VERSION ""

NS_ :

BS_:

BU_: Server VCU Body Brakes
VAL_TABLE_ VCI_SevereWarn 2 "All Clear" 1 "Warning Active" 0 "Offline" ;

BO_ 3221225472 VECTOR__INDEPENDENT_SIG_MSG: 0 Vector__XXX
 SG_ WP_Spd : 0|16@1- (0.01,0) [0|0] "kph" Vector__XXX
 SG_ AuxBattErr : 0|8@1+ (1,0) [0|0] "" Vector__XXX
 SG_ AuxBattCurr : 0|16@1- (0.1,0) [-3276.8|3276.7] "A" Vector__XXX
 SG_ AuxBattVolt : 0|16@1- (0.01,0) [-327.68|327.67] "V" Vector__XXX
 SG_ SOH : 0|8@1+ (1,0) [0|0] "%" Vector__XXX
 SG_ SOC : 0|8@1+ (1,0) [0|0] "%" Vector__XXX
 SG_ TiRemn : 0|8@1+ (1,0) [0|0] "hr" Vector__XXX
 SG_ patch_type : 0|8@1+ (0.1,0) [0|25.5] "" Vector__XXX
 SG_ ActEngBrkPerc : 0|8@1+ (1,-125) [-125|125] "%" Vector__XXX
 SG_ Pressure_P4 : 0|8@1+ (80,0) [0|255] "mbar" Vector__XXX
 SG_ Pressure_P1 : 0|8@1+ (80,0) [0|255] "mbar" Vector__XXX
 SG_ Pressure_P21 : 0|8@1+ (80,0) [0|255] "mbar" Vector__XXX
 SG_ Pressure_P22 : 0|8@1+ (80,0) [0|255] "mbar" Vector__XXX
 SG_ Pressure_P42 : 0|8@1+ (80,0) [0|255] "mbar" Vector__XXX
 SG_ EBS_button : 0|2@1+ (1,0) [0|3] "" Vector__XXX
 SG_ EBS_status : 0|2@1+ (1,0) [0|3] "" Vector__XXX
 SG_ XPR_ErrState : 0|2@1+ (1,0) [0|3] "" Vector__XXX
 SG_ ATC_EC_Act : 0|2@1+ (1,0) [0|3] "" Vector__XXX
 SG_ ATC_BC_Act : 0|2@1+ (1,0) [0|3] "" Vector__XXX
 SG_ ABS_Active : 0|2@1+ (1,0) [0|3] "" Vector__XXX
 SG_ ABS_OffRoad_Switch : 0|2@1+ (1,0) [0|3] "" Vector__XXX
 SG_ ABS_Fully_Op : 0|2@1+ (1,0) [0|3] "" Vector__XXX
 SG_ ABS_Amber_WL : 0|2@1+ (1,0) [0|3] "" Vector__XXX
 SG_ ATC_Info_Lamp : 0|2@1+ (1,0) [0|3] "" Vector__XXX
 SG_ IdentityNum : 0|21@1+ (1,0) [0|2097151] "" Vector__XXX
 SG_ Manufacturer : 0|11@1+ (1,0) [0|2047] "" Vector__XXX
 SG_ EcuInstance : 0|3@1+ (1,0) [0|7] "" Vector__XXX
 SG_ FctInstance : 0|5@1+ (1,0) [0|31] "" Vector__XXX
 SG_ Reserved : 0|1@1+ (1,0) [0|1] "" Vector__XXX
 SG_ VehSystem : 0|7@1+ (1,0) [0|127] "" Vector__XXX
 SG_ VehSysInstance : 0|4@1+ (1,0) [0|15] "" Vector__XXX
 SG_ ArbAddrCapable : 0|1@1+ (1,0) [0|1] "" Vector__XXX
 SG_ ACHeatOption : 0|2@1- (1,0) [0|0] "" Vector__XXX
 SG_ ACControlMode : 0|2@1- (1,0) [0|0] "" Vector__XXX
 SG_ PreCruiseCtrlDeactivRq : 0|2@1+ (1,0) [0|3] "" Vector__XXX
 SG_ CabInteriorTempCmd : 0|16@1+ (0.03125,-273) [-273|1734.96875] "deg C" Vector__XXX
 SG_ AuxHeaterCoolantPumpRq : 0|2@1+ (1,0) [0|3] "" Vector__XXX
 SG_ BatteryMainSwitchHoldRq : 0|2@1+ (1,0) [0|3] "" Vector__XXX
 SG_ OperatorSeatDirectionSwitch : 0|2@1+ (1,0) [0|3] "" Vector__XXX
 SG_ SeatBeltSwitch : 0|2@1+ (1,0) [0|3] "" Vector__XXX
 SG_ VhclLmtngSpdGvrnrDecrementSwitch : 0|2@1+ (1,0) [0|3] "" Vector__XXX
 SG_ VhclLmtngSpdGvrnrIncrementSwitch : 0|2@1+ (1,0) [0|3] "" Vector__XXX
 SG_ VhclLmtngSpdGovernorEnableSwitch : 0|2@1+ (1,0) [0|3] "" Vector__XXX
 SG_ DslPrtcltFltrRgnrtnInhibitSwitch : 0|2@1+ (1,0) [0|3] "" Vector__XXX
 SG_ DslPrtcltFltrRgnrtionForceSwitch : 0|2@1+ (1,0) [0|3] "" Vector__XXX
 SG_ AtomaticGearShiftingEnableSwitch : 0|2@1+ (1,0) [0|3] "" Vector__XXX
 SG_ EngAutomaticStartEnableSwitch : 0|2@1+ (1,0) [0|3] "" Vector__XXX
 SG_ AuxHeaterModeRq : 0|4@1+ (1,0) [0|15] "" Vector__XXX
 SG_ RqEngZoneHeating : 0|2@1+ (1,0) [0|3] "" Vector__XXX
 SG_ RqCabZoneHeating : 0|2@1+ (1,0) [0|3] "" Vector__XXX
 SG_ SelectedMaxVehicleSpeedLimit : 0|8@1+ (1,0) [0|250] "" Vector__XXX
 SG_ EnginePercentLoadAtCurrentSpeed : 0|8@1+ (1,0) [0|255] "%" Vector__XXX
 SG_ AcceleratorPedalPosition2 : 0|8@1+ (0.4,0) [0|102] "%" Vector__XXX
 SG_ AcceleratorPedalPosition1 : 0|8@1+ (0.4,0) [0|102] "%" Vector__XXX
 SG_ xbr_demand : 0|8@1+ (0.025,0) [0|6.375] "" Vector__XXX
 SG_ CTIWheelEndElectricalFault_00 : 0|2@1+ (1,0) [0|3] "" Vector__XXX
 SG_ CTIWheelSensorStatus_00 : 0|2@1+ (1,0) [0|3] "" Vector__XXX
 SG_ TirePress_00 : 0|8@1+ (4,0) [0|1000] "kPa" Vector__XXX
 SG_ TirePress_01 : 0|8@1+ (4,0) [0|1000] "kPa" Vector__XXX
 SG_ TirePressThresholdDetection_00 : 0|3@1+ (1,0) [0|7] "" Vector__XXX
 SG_ TirePressThresholdDetection_20 : 0|3@1+ (1,0) [0|7] "" Vector__XXX
 SG_ TirePressThresholdDetection_21 : 0|3@1+ (1,0) [0|7] "" Vector__XXX
 SG_ TirePressThresholdDetection_22 : 0|3@1+ (1,0) [0|7] "" Vector__XXX
 SG_ TirePressThresholdDetection_23 : 0|3@1+ (1,0) [0|7] "" Vector__XXX
 SG_ TirePressThresholdDetection_30 : 0|3@1+ (1,0) [0|7] "" Vector__XXX
 SG_ TirePressThresholdDetection_31 : 0|3@1+ (1,0) [0|7] "" Vector__XXX
 SG_ TirePressThresholdDetection_32 : 0|3@1+ (1,0) [0|7] "" Vector__XXX
 SG_ TirePressThresholdDetection_33 : 0|3@1+ (1,0) [0|7] "" Vector__XXX
 SG_ TireTemp_01 : 0|16@1+ (0.03125,-273) [-273|1735] "°C" Vector__XXX
 SG_ TireTemp_10 : 0|16@1+ (0.03125,-273) [-273|1735] "°C" Vector__XXX
 SG_ TireTemp_12 : 0|16@1+ (0.03125,-273) [-273|1735] "°C" Vector__XXX
 SG_ TireTemp_13 : 0|16@1+ (0.03125,-273) [-273|1735] "°C" Vector__XXX
 SG_ TireTemp_20 : 0|16@1+ (0.03125,-273) [-273|1735] "°C" Vector__XXX
 SG_ TireTemp_21 : 0|16@1+ (0.03125,-273) [-273|1735] "°C" Vector__XXX
 SG_ TireTemp_22 : 0|16@1+ (0.03125,-273) [-273|1735] "°C" Vector__XXX
 SG_ TireTemp_23 : 0|16@1+ (0.03125,-273) [-273|1735] "°C" Vector__XXX
 SG_ TireTemp_30 : 0|16@1+ (0.03125,-273) [-273|1735] "°C" Vector__XXX
 SG_ TireTemp_31 : 0|16@1+ (0.03125,-273) [-273|1735] "°C" Vector__XXX
 SG_ TireTemp_32 : 0|16@1+ (0.03125,-273) [-273|1735] "°C" Vector__XXX
 SG_ TireTemp_33 : 0|16@1+ (0.03125,-273) [-273|1735] "°C" Vector__XXX
 SG_ TireTemp_11 : 0|16@1+ (0.03125,-273) [-273|1735] "°C" Vector__XXX
 SG_ CTITireStatus_01 : 0|2@1+ (1,0) [0|3] "" Vector__XXX
 SG_ CTITireStatus_10 : 0|2@1+ (1,0) [0|3] "" Vector__XXX
 SG_ CTITireStatus_11 : 0|2@1+ (1,0) [0|3] "" Vector__XXX
 SG_ CTITireStatus_12 : 0|2@1+ (1,0) [0|3] "" Vector__XXX
 SG_ CTITireStatus_13 : 0|2@1+ (1,0) [0|3] "" Vector__XXX
 SG_ CTITireStatus_20 : 0|2@1+ (1,0) [0|3] "" Vector__XXX
 SG_ CTITireStatus_21 : 0|2@1+ (1,0) [0|3] "" Vector__XXX
 SG_ CTITireStatus_22 : 0|2@1+ (1,0) [0|3] "" Vector__XXX
 SG_ CTITireStatus_23 : 0|2@1+ (1,0) [0|3] "" Vector__XXX
 SG_ CTITireStatus_30 : 0|2@1+ (1,0) [0|3] "" Vector__XXX
 SG_ CTITireStatus_31 : 0|2@1+ (1,0) [0|3] "" Vector__XXX
 SG_ CTITireStatus_32 : 0|2@1+ (1,0) [0|3] "" Vector__XXX
 SG_ CTITireStatus_33 : 0|2@1+ (1,0) [0|3] "" Vector__XXX
 SG_ CTIWheelEndElectricalFault_01 : 0|2@1+ (1,0) [0|3] "" Vector__XXX
 SG_ CTIWheelEndElectricalFault_10 : 0|2@1+ (1,0) [0|3] "" Vector__XXX
 SG_ CTIWheelEndElectricalFault_11 : 0|2@1+ (1,0) [0|3] "" Vector__XXX
 SG_ CTIWheelEndElectricalFault_12 : 0|2@1+ (1,0) [0|3] "" Vector__XXX
 SG_ CTIWheelEndElectricalFault_13 : 0|2@1+ (1,0) [0|3] "" Vector__XXX
 SG_ CTIWheelEndElectricalFault_20 : 0|2@1+ (1,0) [0|3] "" Vector__XXX
 SG_ CTIWheelEndElectricalFault_21 : 0|2@1+ (1,0) [0|3] "" Vector__XXX
 SG_ CTIWheelEndElectricalFault_22 : 0|2@1+ (1,0) [0|3] "" Vector__XXX
 SG_ CTIWheelEndElectricalFault_23 : 0|2@1+ (1,0) [0|3] "" Vector__XXX
 SG_ CTIWheelEndElectricalFault_30 : 0|2@1+ (1,0) [0|3] "" Vector__XXX
 SG_ CTIWheelEndElectricalFault_31 : 0|2@1+ (1,0) [0|3] "" Vector__XXX
 SG_ CTIWheelEndElectricalFault_32 : 0|2@1+ (1,0) [0|3] "" Vector__XXX
 SG_ CTIWheelSensorStatus_01 : 0|2@1+ (1,0) [0|3] "" Vector__XXX
 SG_ CTIWheelSensorStatus_10 : 0|2@1+ (1,0) [0|3] "" Vector__XXX
 SG_ CTIWheelSensorStatus_11 : 0|2@1+ (1,0) [0|3] "" Vector__XXX
 SG_ CTIWheelSensorStatus_12 : 0|2@1+ (1,0) [0|3] "" Vector__XXX
 SG_ CTIWheelSensorStatus_13 : 0|2@1+ (1,0) [0|3] "" Vector__XXX
 SG_ CTIWheelSensorStatus_20 : 0|2@1+ (1,0) [0|3] "" Vector__XXX
 SG_ CTIWheelSensorStatus_21 : 0|2@1+ (1,0) [0|3] "" Vector__XXX
 SG_ CTIWheelSensorStatus_22 : 0|2@1+ (1,0) [0|3] "" Vector__XXX
 SG_ CTIWheelSensorStatus_23 : 0|2@1+ (1,0) [0|3] "" Vector__XXX
 SG_ CTIWheelSensorStatus_30 : 0|2@1+ (1,0) [0|3] "" Vector__XXX
 SG_ CTIWheelSensorStatus_31 : 0|2@1+ (1,0) [0|3] "" Vector__XXX
 SG_ CTIWheelSensorStatus_32 : 0|2@1+ (1,0) [0|3] "" Vector__XXX
 SG_ TireAirLeakageRate_00 : 0|16@1+ (0.1,0) [0|6425.5] "Pa/s" Vector__XXX
 SG_ TireAirLeakageRate_01 : 0|16@1+ (0.1,0) [0|6425.5] "Pa/s" Vector__XXX
 SG_ TireAirLeakageRate_10 : 0|16@1+ (0.1,0) [0|6425.5] "Pa/s" Vector__XXX
 SG_ TireAirLeakageRate_11 : 0|16@1+ (0.1,0) [0|6425.5] "Pa/s" Vector__XXX
 SG_ TireAirLeakageRate_12 : 0|16@1+ (0.1,0) [0|6425.5] "Pa/s" Vector__XXX
 SG_ TireAirLeakageRate_13 : 0|16@1+ (0.1,0) [0|6425.5] "Pa/s" Vector__XXX
 SG_ TireAirLeakageRate_20 : 0|16@1+ (0.1,0) [0|6425.5] "Pa/s" Vector__XXX
 SG_ TireAirLeakageRate_21 : 0|16@1+ (0.1,0) [0|6425.5] "Pa/s" Vector__XXX
 SG_ TireAirLeakageRate_22 : 0|16@1+ (0.1,0) [0|6425.5] "Pa/s" Vector__XXX
 SG_ TireAirLeakageRate_23 : 0|16@1+ (0.1,0) [0|6425.5] "Pa/s" Vector__XXX
 SG_ TireAirLeakageRate_30 : 0|16@1+ (0.1,0) [0|6425.5] "Pa/s" Vector__XXX
 SG_ TireAirLeakageRate_31 : 0|16@1+ (0.1,0) [0|6425.5] "Pa/s" Vector__XXX
 SG_ TireAirLeakageRate_32 : 0|16@1+ (0.1,0) [0|6425.5] "Pa/s" Vector__XXX
 SG_ TirePress_10 : 0|8@1+ (4,0) [0|1000] "kPa" Vector__XXX
 SG_ TirePress_11 : 0|8@1+ (4,0) [0|1000] "kPa" Vector__XXX
 SG_ TirePress_12 : 0|8@1+ (4,0) [0|1000] "kPa" Vector__XXX
 SG_ TirePress_13 : 0|8@1+ (4,0) [0|1000] "kPa" Vector__XXX
 SG_ TirePress_20 : 0|8@1+ (4,0) [0|1000] "kPa" Vector__XXX
 SG_ TirePress_21 : 0|8@1+ (4,0) [0|1000] "kPa" Vector__XXX
 SG_ TirePress_22 : 0|8@1+ (4,0) [0|1000] "kPa" Vector__XXX
 SG_ TirePress_23 : 0|8@1+ (4,0) [0|1000] "kPa" Vector__XXX
 SG_ TirePress_30 : 0|8@1+ (4,0) [0|1000] "kPa" Vector__XXX
 SG_ TirePress_31 : 0|8@1+ (4,0) [0|1000] "kPa" Vector__XXX
 SG_ TirePress_32 : 0|8@1+ (4,0) [0|1000] "kPa" Vector__XXX
 SG_ TirePressThresholdDetection_01 : 0|3@1+ (1,0) [0|7] "" Vector__XXX
 SG_ TirePressThresholdDetection_10 : 0|3@1+ (1,0) [0|7] "" Vector__XXX
 SG_ TirePressThresholdDetection_11 : 0|3@1+ (1,0) [0|7] "" Vector__XXX
 SG_ TirePressThresholdDetection_12 : 0|3@1+ (1,0) [0|7] "" Vector__XXX
 SG_ AxleWeight_00 : 0|16@1+ (0.5,0) [0|32127.5] "kg" Vector__XXX
 SG_ AxleWeight_10 : 0|16@1+ (0.5,0) [0|32127.5] "kg" Vector__XXX
 SG_ AxleWeight_20 : 0|16@1+ (0.5,0) [0|32127.5] "kg" Vector__XXX
 SG_ TrailerWeight_00 : 0|16@1+ (2,0) [0|128510] "kg" Vector__XXX
 SG_ TrailerWeight_10 : 0|16@1+ (2,0) [0|128510] "kg" Vector__XXX
 SG_ TrailerWeight_20 : 0|16@1+ (2,0) [0|128510] "kg" Vector__XXX
 SG_ CargoWeight_00 : 0|16@1+ (2,0) [0|128510] "kg" Vector__XXX
 SG_ CargoWeight_10 : 0|16@1+ (2,0) [0|128510] "kg" Vector__XXX
 SG_ CargoWeight_20 : 0|16@1+ (2,0) [0|128510] "kg" Vector__XXX
 SG_ BrkPos_Ord : 0|1@1+ (1,0) [0|1] "" Vector__XXX
 SG_ Counter : 0|4@1+ (1,0) [0|15] "" Vector__XXX
 SG_ EBI_Mode : 0|1@1- (1,0) [0|1] "" Vector__XXX
 SG_ BrakeDemand : 0|16@1- (0.000488,-15.687) [-31.6778|0.303295] "m/s2" Vector__XXX
 SG_ Counter : 0|4@1+ (1,0) [0|15] "" Vector__XXX
 SG_ EBI_Mode : 0|1@1- (1,0) [0|1] "" Vector__XXX
 SG_ BrakeDemand : 0|16@1- (0.000488,-15.687) [-31.6778|0.303295] "m/s2" Vector__XXX

BO_ 2147516743 VehFSLogRpt1: 8 Vector__XXX
 SG_ FSBMod : 8|2@1+ (1,0) [0|3] "" Vector__XXX
 SG_ FSBA : 0|8@1+ (0.1,-12.5) [-12.5|13] "" Vector__XXX

BO_ 2147488545 VCU_Test3MSG: 8 Vector__XXX
 SG_ ACCTarSpd : 8|8@1+ (1,0) [0|255] "km/h" Vector__XXX
 SG_ FSBEna : 0|2@1+ (1,0) [0|3] "" Vector__XXX

BO_ 2466192724 MURR_PWM2: 8 Vector__XXX
 SG_ PWMCtrlOut4B : 48|12@1+ (1,0) [0|0] "" Vector__XXX
 SG_ PWMCtrlOut4A : 32|12@1+ (1,0) [0|0] "" Vector__XXX
 SG_ PWMCtrlOut3B : 16|12@1+ (1,0) [0|0] "" Vector__XXX
 SG_ PWMCtrlOut3A : 0|16@1+ (1,0) [0|0] "" Vector__XXX

BO_ 2466192468 MURR_PWM1: 8 Vector__XXX
 SG_ PWMCtrlOut2B : 48|12@1+ (1,0) [0|0] "" Vector__XXX
 SG_ PWMCtrlOut2A : 32|12@1+ (1,0) [0|0] "" Vector__XXX
 SG_ PWMCtrlOut1B : 16|12@1+ (1,0) [0|0] "" Vector__XXX
 SG_ PWMCtrlOut1A : 0|16@1+ (1,0) [0|0] "" Vector__XXX

BO_ 2466192980 MURR_PWM3: 8 Vector__XXX
 SG_ PWMCtrlOut6B : 48|12@1+ (1,0) [0|0] "" Vector__XXX
 SG_ PWMCtrlOut6A : 32|12@1+ (1,0) [0|0] "" Vector__XXX
 SG_ PWMCtrlOut5B : 16|12@1+ (1,0) [0|0] "" Vector__XXX
 SG_ PWMCtrlOut5A : 0|12@1+ (1,0) [0|0] "" Vector__XXX

BO_ 2466193236 MURR_PWM4: 8 Vector__XXX
 SG_ PWMCtrlOut8B : 48|12@1+ (1,0) [0|0] "" Vector__XXX
 SG_ PWMCtrlOut8A : 32|12@1+ (1,0) [0|0] "" Vector__XXX
 SG_ PWMCtrlOut7B : 16|12@1+ (1,0) [0|0] "" Vector__XXX
 SG_ PWMCtrlOut7A : 0|12@1+ (1,0) [0|0] "" Vector__XXX

BO_ 2147484440 PwrRpt: 8 Vector__XXX
 SG_ PwrSevereWarn : 16|8@1+ (1,0) [0|0] "mV" Vector__XXX
 SG_ AuxV : 0|16@1+ (0.5,0) [0|32767.5] "mV" Vector__XXX

BO_ 2147484438 SwtTRpt: 8 Vector__XXX
 SG_ TSevereWarn : 16|8@1+ (1,0) [0|0] "deg C" Vector__XXX
 SG_ SwtT : 0|16@1+ (0.11,-28.919) [-28.919|7179.931] "deg C" Vector__XXX

BO_ 2566911200 StatusMsg5: 8 Vector__XXX
 SG_ OUT8B_AMP_FB : 56|8@1+ (1,0) [0|4000] "A" Vector__XXX
 SG_ OUT8A_AMP_FB : 48|8@1+ (1,0) [0|4000] "A" Vector__XXX
 SG_ OUT7B_AMP_FB : 40|8@1+ (1,0) [0|4000] "A" Vector__XXX
 SG_ OUT7A_AMP_FB : 32|8@1+ (1,0) [0|4000] "A" Vector__XXX
 SG_ OUT6B_AMP_FB : 24|8@1+ (1,0) [0|4000] "A" Vector__XXX
 SG_ OUT6A_AMP_FB : 16|8@1+ (1,0) [0|4000] "A" Vector__XXX
 SG_ OUT5B_AMP_FB : 8|8@1+ (1,0) [0|4000] "A" Vector__XXX
 SG_ OUT5A_AMP_FB : 0|8@1+ (1,0) [0|4000] "A" Vector__XXX

BO_ 2566910944 StatusMsg4: 8 Vector__XXX
 SG_ OUT4B_AMP_FB : 56|8@1+ (1,0) [0|0] "mA" Vector__XXX
 SG_ OUT4A_AMP_FB : 48|8@1+ (1,0) [0|0] "mA" Vector__XXX
 SG_ OUT3B_AMP_FB : 40|8@1+ (1,0) [0|0] "mA" Vector__XXX
 SG_ OUT3A_AMP_FB : 32|8@1+ (1,0) [0|0] "mA" Vector__XXX
 SG_ OUT2B_AMP_FB : 24|8@1+ (1,0) [0|0] "mA" Vector__XXX
 SG_ OUT2A_AMP_FB : 16|8@1+ (1,0) [0|0] "mA" Vector__XXX
 SG_ OUT1B_AMP_FB : 8|8@1+ (1,0) [0|0] "mA" Vector__XXX
 SG_ OUT1A_AMP_FB : 0|8@1+ (1,0) [0|0] "mA" Vector__XXX

BO_ 2566912992 StatusMsg2: 8 Vector__XXX
 SG_ SaveConfigCounter : 56|8@1+ (1,0) [0|0] "" Vector__XXX
 SG_ PowerBussP3 : 52|2@1+ (1,0) [0|0] "A" Vector__XXX
 SG_ PowerBussP2 : 50|2@1+ (1,0) [0|0] "A" Vector__XXX
 SG_ PowerBussP4 : 54|2@1+ (1,0) [0|0] "A" Vector__XXX
 SG_ PowerBussP1 : 48|2@1+ (1,0) [0|0] "A" Vector__XXX
 SG_ Output8BStatus : 46|2@1+ (1,0) [0|0] "" Vector__XXX
 SG_ Output8AStatus : 44|2@1+ (1,0) [0|0] "" Vector__XXX
 SG_ Output7BStatus : 42|2@1+ (1,0) [0|0] "" Vector__XXX
 SG_ Output7AStatus : 40|2@1+ (1,0) [0|0] "" Vector__XXX
 SG_ Output6BStatus : 38|2@1+ (1,0) [0|0] "" Vector__XXX
 SG_ Output6AStatus : 36|2@1+ (1,0) [0|0] "" Vector__XXX
 SG_ Output5BStatus : 34|2@1+ (1,0) [0|0] "" Vector__XXX
 SG_ Output5AStatus : 32|2@1+ (1,0) [0|0] "" Vector__XXX
 SG_ Output4BStatus : 30|2@1+ (1,0) [0|0] "" Vector__XXX
 SG_ Output4AStatus : 28|2@1+ (1,0) [0|0] "" Vector__XXX
 SG_ Output3BStatus : 26|2@1+ (1,0) [0|0] "" Vector__XXX
 SG_ Output3AStatus : 24|2@1+ (1,0) [0|0] "" Vector__XXX
 SG_ Output2BStatus : 22|2@1+ (1,0) [0|0] "" Vector__XXX
 SG_ Output2AStatus : 20|2@1+ (1,0) [0|0] "" Vector__XXX
 SG_ Output1BStatus : 18|2@1+ (1,0) [0|0] "" Vector__XXX
 SG_ Output1AStatus : 16|2@1+ (1,0) [0|0] "" Vector__XXX
 SG_ ConfigPair5 : 8|2@1+ (1,0) [0|0] "" Vector__XXX
 SG_ ConfigPair4 : 6|2@1+ (1,0) [0|0] "" Vector__XXX
 SG_ ConfigPair3 : 4|2@1+ (1,0) [0|0] "" Vector__XXX
 SG_ ConfigPair2 : 2|2@1+ (1,0) [0|0] "" Vector__XXX
 SG_ ConfigPair1 : 0|2@1+ (1,0) [0|0] "" Vector__XXX

BO_ 2566913248 StatusMsg3: 8 Vector__XXX
 SG_ CNFG3 : 48|8@1+ (1,0) [0|0] "" Vector__XXX
 SG_ TEMP : 32|12@1+ (1,0) [0|0] "" Vector__XXX
 SG_ VBAT : 16|10@1+ (1,0) [0|0] "" Vector__XXX
 SG_ CNFG2 : 8|8@1+ (1,0) [0|0] "" Vector__XXX
 SG_ CNFG1 : 0|8@1+ (1,0) [0|0] "" Vector__XXX

BO_ 2565857361 MURR_Relay: 8 Vector__XXX
 SG_ Output8B : 38|2@1+ (1,0) [0|0] "" Vector__XXX
 SG_ Output8A : 36|2@1+ (1,0) [0|0] "" Vector__XXX
 SG_ Output7B : 34|2@1+ (1,0) [0|0] "" Vector__XXX
 SG_ Output7A : 32|2@1+ (1,0) [0|0] "" Vector__XXX
 SG_ Output6B : 30|2@1+ (1,0) [0|0] "" Vector__XXX
 SG_ Output6A : 28|2@1+ (1,0) [0|0] "" Vector__XXX
 SG_ Output5B : 26|2@1+ (1,0) [0|0] "" Vector__XXX
 SG_ Output5A : 24|2@1+ (1,0) [0|0] "" Vector__XXX
 SG_ Output4B : 22|2@1+ (1,0) [0|0] "" Vector__XXX
 SG_ Output4A : 20|2@1+ (1,0) [0|0] "" Vector__XXX
 SG_ Output3B : 18|2@1+ (1,0) [0|0] "" Vector__XXX
 SG_ Output3A : 16|2@1+ (1,0) [0|0] "" Vector__XXX
 SG_ Output2B : 14|2@1+ (1,0) [0|0] "" Vector__XXX
 SG_ Output2A : 12|2@1+ (1,0) [0|0] "" Vector__XXX
 SG_ Output1B : 10|2@1+ (1,0) [0|0] "" Vector__XXX
 SG_ Output1A : 8|2@1+ (1,0) [0|0] "" Vector__XXX
 SG_ Command : 0|8@1+ (1,0) [0|0] "" Vector__XXX

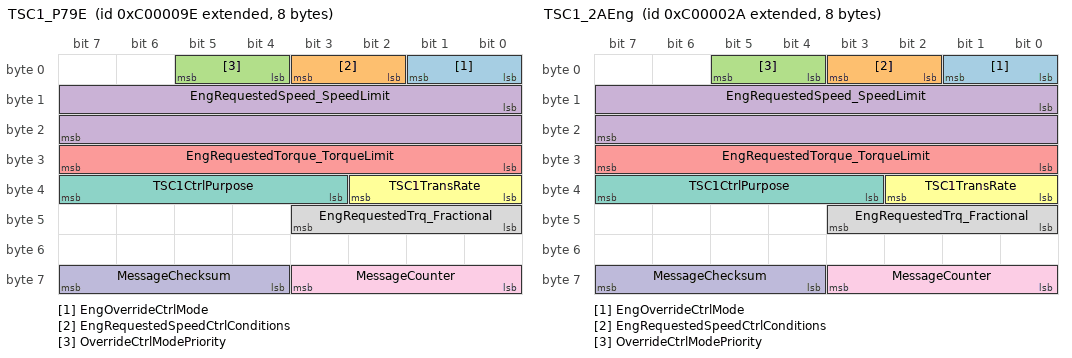
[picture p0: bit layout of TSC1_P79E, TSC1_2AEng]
BO_ 2348810398 TSC1_P79E: 8 Vector__XXX
 SG_ EngOverrideCtrlMode : 0|2@1+ (1,0) [0|3] "" Vector__XXX
 SG_ EngRequestedSpeedCtrlConditions : 2|2@1+ (1,0) [0|3] "" Vector__XXX
 SG_ OverrideCtrlModePriority : 4|2@1+ (1,0) [0|3] "" Vector__XXX
 SG_ EngRequestedSpeed_SpeedLimit : 8|16@1+ (0.125,0) [0|8031.88] "rpm" Vector__XXX
 SG_ EngRequestedTorque_TorqueLimit : 24|8@1+ (1,-125) [-125|125] "%" Vector__XXX
 SG_ TSC1TransRate : 32|3@1+ (1,0) [0|7] "" Vector__XXX
 SG_ TSC1CtrlPurpose : 35|5@1+ (1,0) [0|31] "" Vector__XXX
 SG_ EngRequestedTrq_Fractional : 40|4@1+ (0.125,0) [0|0.875] "%" Vector__XXX
 SG_ MessageCounter : 56|4@1+ (1,0) [0|15] "" Vector__XXX
 SG_ MessageChecksum : 60|4@1+ (1,0) [0|15] "" Vector__XXX

BO_ 2348810282 TSC1_2AEng: 8 Vector__XXX
 SG_ EngOverrideCtrlMode : 0|2@1+ (1,0) [0|3] "" Vector__XXX
 SG_ EngRequestedSpeedCtrlConditions : 2|2@1+ (1,0) [0|3] "" Vector__XXX
 SG_ OverrideCtrlModePriority : 4|2@1+ (1,0) [0|3] "" Vector__XXX
 SG_ EngRequestedSpeed_SpeedLimit : 8|16@1+ (0.125,0) [0|8031.88] "rpm" Vector__XXX
 SG_ EngRequestedTorque_TorqueLimit : 24|8@1+ (1,-125) [-125|125] "%" Vector__XXX
 SG_ TSC1TransRate : 32|3@1+ (1,0) [0|7] "" Vector__XXX
 SG_ TSC1CtrlPurpose : 35|5@1+ (1,0) [0|31] "" Vector__XXX
 SG_ EngRequestedTrq_Fractional : 40|4@1+ (0.125,0) [0|0.875] "%" Vector__XXX
 SG_ MessageCounter : 56|4@1+ (1,0) [0|15] "" Vector__XXX
 SG_ MessageChecksum : 60|4@1+ (1,0) [0|15] "" Vector__XXX

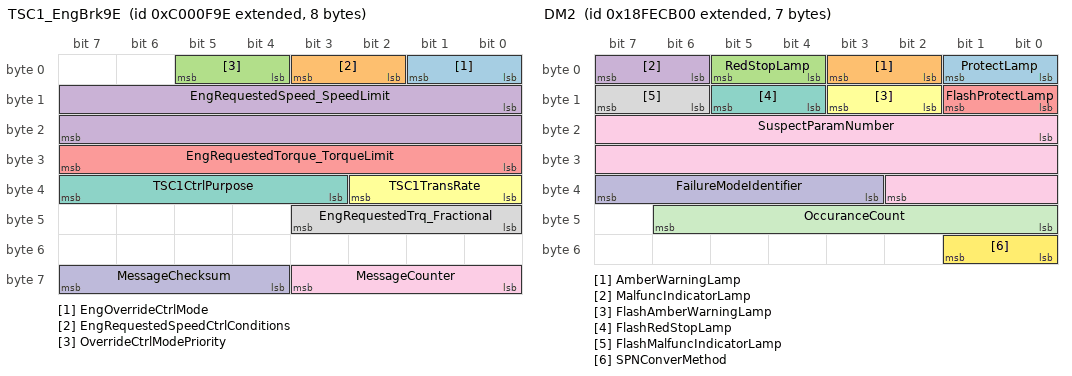
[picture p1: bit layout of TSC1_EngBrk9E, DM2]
BO_ 2348814238 TSC1_EngBrk9E: 8 Vector__XXX
 SG_ EngOverrideCtrlMode : 0|2@1+ (1,0) [0|3] "" Vector__XXX
 SG_ EngRequestedSpeedCtrlConditions : 2|2@1+ (1,0) [0|3] "" Vector__XXX
 SG_ OverrideCtrlModePriority : 4|2@1+ (1,0) [0|3] "" Vector__XXX
 SG_ EngRequestedSpeed_SpeedLimit : 8|16@1+ (0.125,0) [0|8031.88] "rpm" Vector__XXX
 SG_ EngRequestedTorque_TorqueLimit : 24|8@1+ (1,-125) [-125|125] "%" Vector__XXX
 SG_ TSC1TransRate : 32|3@1+ (1,0) [0|7] "" Vector__XXX
 SG_ TSC1CtrlPurpose : 35|5@1+ (1,0) [0|31] "" Vector__XXX
 SG_ EngRequestedTrq_Fractional : 40|4@1+ (0.125,0) [0|0.875] "%" Vector__XXX
 SG_ MessageCounter : 56|4@1+ (1,0) [0|15] "" Vector__XXX
 SG_ MessageChecksum : 60|4@1+ (1,0) [0|15] "" Vector__XXX

BO_ 2566834944 DM2: 7 Vector__XXX
 SG_ ProtectLamp : 0|2@1+ (1,0) [0|3] "" Vector__XXX
 SG_ AmberWarningLamp : 2|2@1+ (1,0) [0|3] "" Vector__XXX
 SG_ RedStopLamp : 4|2@1+ (1,0) [0|3] "" Vector__XXX
 SG_ MalfuncIndicatorLamp : 6|2@1+ (1,0) [0|3] "" Vector__XXX
 SG_ FlashProtectLamp : 8|2@1+ (1,0) [0|3] "" Vector__XXX
 SG_ FlashAmberWarningLamp : 10|2@1+ (1,0) [0|3] "" Vector__XXX
 SG_ FlashRedStopLamp : 12|2@1+ (1,0) [0|3] "" Vector__XXX
 SG_ FlashMalfuncIndicatorLamp : 14|2@1+ (1,0) [0|3] "" Vector__XXX
 SG_ SuspectParamNumber : 16|19@1+ (1,0) [0|524287] "" Vector__XXX
 SG_ FailureModeIdentifier : 35|5@1+ (1,0) [0|31] "" Vector__XXX
 SG_ OccuranceCount : 40|7@1+ (1,0) [0|127] "" Vector__XXX
 SG_ SPNConverMethod : 48|2@1+ (1,0) [0|3] "" Vector__XXX

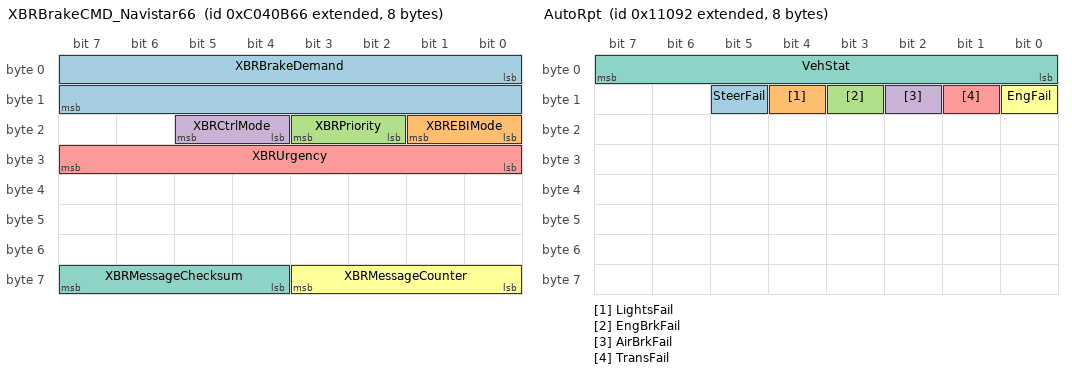
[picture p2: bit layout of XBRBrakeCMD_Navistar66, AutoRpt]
BO_ 2349075302 XBRBrakeCMD_Navistar66: 8 VCU
 SG_ XBRBrakeDemand : 0|16@1+ (0.000488,-15.69) [-15.69|-15.6749] "m/s?" Vector__XXX
 SG_ XBREBIMode : 16|2@1+ (1,0) [0|3] "" Vector__XXX
 SG_ XBRPriority : 18|2@1+ (1,0) [0|3] "" Vector__XXX
 SG_ XBRCtrlMode : 20|2@1+ (1,0) [0|3] "" Vector__XXX
 SG_ XBRUrgency : 24|8@1+ (1,0) [0|100] "%" Vector__XXX
 SG_ XBRMessageCounter : 56|4@1+ (1,0) [0|15] "" Vector__XXX
 SG_ XBRMessageChecksum : 60|4@1+ (1,0) [0|15] "" Vector__XXX

BO_ 2147680272 VersionGWRpt: 8 Vector__XXX
 SG_ GW_truck_type : 24|8@1+ (1,0) [0|0] "" Vector__XXX
 SG_ GW_patch_version : 16|8@1+ (1,0) [0|0] "" Vector__XXX
 SG_ GW_feature_version : 8|8@1+ (1,0) [0|0] "" Vector__XXX
 SG_ GW_version : 0|8@1+ (1,0) [0|0] "" Vector__XXX

BO_ 2147680257 AcsyRpt: 8 VCU
 SG_ HighBeamHeadLightRpt : 8|2@1+ (1,0) [0|0] "" Vector__XXX
 SG_ LowBeamHeadLightRpt : 6|2@1+ (1,0) [0|0] "" Vector__XXX
 SG_ HazardLightRpt : 4|2@1+ (1,0) [0|0] "" Vector__XXX
 SG_ RightTurnSignalLightsRpt : 2|2@1+ (1,0) [0|0] "" Vector__XXX
 SG_ LeftTurnSignalLightsRpt : 0|2@1+ (1,0) [0|0] "" Vector__XXX
 SG_ TurnSignalLightsDriverCmd : 10|2@1+ (1,0) [0|0] "" Vector__XXX

BO_ 2147618952 VcuTimeSync_Slave: 8 Server
 SG_ RollingCounter : 32|32@1+ (1,0) [0|0] "" Vector__XXX
 SG_ Seconds : 24|8@1+ (1,0) [0|0] "sec" Vector__XXX
 SG_ Minutes : 16|8@1+ (1,0) [0|0] "min" Vector__XXX
 SG_ Hour : 8|8@1+ (1,0) [0|0] "hr" Vector__XXX
 SG_ Day : 0|8@1+ (1,0) [0|0] "" Vector__XXX

BO_ 2147520848 TimeSync_Slave: 8 Server
 SG_ RollingCounter : 32|32@1+ (1,0) [0|0] "" Vector__XXX
 SG_ Seconds : 24|8@1+ (1,0) [0|0] "sec" Vector__XXX
 SG_ Minutes : 16|8@1+ (1,0) [0|0] "min" Vector__XXX
 SG_ Hour : 8|8@1+ (1,0) [0|0] "hr" Vector__XXX
 SG_ Day : 0|8@1+ (1,0) [0|0] "" Vector__XXX

BO_ 2147516756 OctopusStatus: 8 Server
 SG_ SystemStatus : 0|8@1+ (1,0) [0|0] "" Vector__XXX
 SG_ ControllerStatus : 14|2@1+ (1,0) [0|0] "" Vector__XXX
 SG_ PlannerStatus : 12|2@1+ (1,0) [0|0] "" Vector__XXX
 SG_ LocalizationStatus : 10|2@1+ (1,0) [0|0] "" Vector__XXX
 SG_ PerceptionStatus : 8|2@1+ (1,0) [0|0] "" Vector__XXX

BO_ 2147516754 VehInfo: 1 Server
 SG_ P7Support : 6|2@1+ (1,0) [0|0] "" Vector__XXX
 SG_ _2C2Present : 4|2@1+ (1,0) [0|3] "" Vector__XXX
 SG_ VehType : 0|4@1+ (1,0) [0|15] "" Vector__XXX

BO_ 2147553416 VcuTimeSync: 8 VCU
 SG_ SimTime : 0|32@1+ (1,0) [0|0] "" Vector__XXX

BO_ 2147484436 AcRpt: 8 VCU
 SG_ SvrT : 48|16@1+ (1,0) [0|0] "" Vector__XXX
 SG_ AcT : 32|16@1+ (1,0) [0|0] "" Vector__XXX
 SG_ CmprSpd : 24|8@1+ (1,0) [0|0] "" Vector__XXX
 SG_ AcSts : 16|4@1+ (1,0) [0|0] "" Vector__XXX
 SG_ CtrlMod : 8|2@1+ (1,0) [0|0] "" Vector__XXX
 SG_ AcFlt : 0|8@1+ (1,0) [0|0] "" Vector__XXX

BO_ 2147484434 AcCmdRpt: 8 VCU
 SG_ CbnT : 48|16@1+ (0.01,0) [0|655.35] "" Vector__XXX
 SG_ ReqdFanSpd : 40|8@1+ (1,0) [0|0] "" Vector__XXX
 SG_ SetT : 32|8@1+ (1,0) [0|0] "" Vector__XXX
 SG_ OperMod : 8|8@1+ (1,0) [0|0] "" Vector__XXX

BO_ 2147516752 TimeSync: 8 Server
 SG_ RollingCounter : 32|32@1+ (1,0) [0|0] "" Vector__XXX
 SG_ Seconds : 24|8@1+ (1,0) [0|0] "sec" Vector__XXX
 SG_ Minutes : 16|8@1+ (1,0) [0|0] "min" Vector__XXX
 SG_ Hour : 8|8@1+ (1,0) [0|0] "hr" Vector__XXX
 SG_ Day : 0|8@1+ (1,0) [0|0] "" Vector__XXX

BO_ 2147516738 VehLatRpt1: 8 Vector__XXX
 SG_ MessageChecksum : 60|4@1+ (1,0) [0|15] "" Vector__XXX
 SG_ MessageCounter : 56|4@1+ (1,0) [0|15] "" Vector__XXX
 SG_ LatSts : 32|4@1+ (1,0) [0|0] "" Vector__XXX
 SG_ A_y : 16|16@1+ (0.00048828,-15.687) [-15.687|16.3124298] "m/s2" Vector__XXX
 SG_ YawRate : 0|16@1+ (0.0001220703125,-3.92) [-3.92|4.0798779296875] "rad/s" Vector__XXX

BO_ 2147516736 SteerRpt1: 8 Vector__XXX
 SG_ SteerSpd : 32|16@1- (0.00097656,0) [-31.99991808|31.99894152] "rev/sec" Vector__XXX
 SG_ MessageChecksum : 60|4@1+ (1,0) [0|15] "" Vector__XXX
 SG_ MessageCounter : 56|4@1+ (1,0) [0|15] "" Vector__XXX
 SG_ SteerAgCmd : 16|16@1- (0.0005,0) [0|0] "rad" Vector__XXX
 SG_ SteerAgMan : 0|16@1- (0.0005,0) [0|0] "rad" Vector__XXX

BO_ 2147516728 LatCmdMai: 8 Server
 SG_ MessageChecksum : 60|4@1+ (1,0) [0|15] "" Vector__XXX
 SG_ MessageCounter : 56|4@1+ (1,0) [0|15] "" Vector__XXX
 SG_ LatCtrlMod : 32|4@1+ (1,0) [0|0] "" Vector__XXX
 SG_ SteerEffort : 16|16@1+ (1,0) [0|0] "" Vector__XXX
 SG_ AgCmd : 0|16@1- (0.04395,0) [0|0] "deg" Vector__XXX

BO_ 2147487744 DTCRpt1: 8 VCU
 SG_ TIRECAN_check2 : 14|2@1+ (1,0) [0|0] "" Vector__XXX
 SG_ TIRECAN_check1 : 12|2@1+ (1,0) [0|0] "" Vector__XXX
 SG_ TireTemp_Flag : 10|2@1+ (1,0) [0|0] "" Vector__XXX
 SG_ TirePres_Flag : 8|2@1+ (1,0) [0|0] "" Vector__XXX
 SG_ MCEPASTEBIN : 0|8@1+ (1,0) [0|0] "" Vector__XXX

BO_ 2147553424 SvrRpt1: 6 VCU
 SG_ Voltage2 : 32|16@1+ (0.05,0) [0|3276.75] "V" Vector__XXX
 SG_ Temperature2 : 16|8@1- (1,-40) [-168|87] "degC" Vector__XXX
 SG_ Current_Server : 0|16@1- (0.05,-1600) [-3238.4|38.3500000000001] "" Vector__XXX

BO_ 2147484432 GenRpt3: 8 VCU

BO_ 2147484424 GenRpt2: 8 VCU

BO_ 2147484422 GenRpt1: 6 VCU
 SG_ DisTFwrVeh : 40|8@1+ (1,0) [0|250] "m" Vector__XXX
 SG_ SpdFwrVeh : 32|8@1+ (1,0) [0|250] "km/h" Vector__XXX
 SG_ WindShieldWiperStatus : 24|8@1+ (1,0) [0|0] "" Vector__XXX
 SG_ RainStatus : 16|8@1+ (1,0) [0|0] "" Vector__XXX
 SG_ GrossCombinationVehicleWeight : 0|16@1+ (10,0) [0|642550] "kg" Vector__XXX

BO_ 2147553426 AutoRpt: 8 VCU
 SG_ SteerFail : 13|1@1+ (1,0) [0|0] "" Vector__XXX
 SG_ LightsFail : 12|1@1+ (1,0) [0|0] "" Vector__XXX
 SG_ EngBrkFail : 11|1@1+ (1,0) [0|0] "" Vector__XXX
 SG_ AirBrkFail : 10|1@1+ (1,0) [0|0] "" Vector__XXX
 SG_ TransFail : 9|1@1+ (1,0) [0|0] "" Vector__XXX
 SG_ EngFail : 8|1@1+ (1,0) [0|0] "" Vector__XXX
 SG_ VehStat : 0|8@1+ (1,0) [0|0] "" Vector__XXX

BO_ 2147484420 EnvRpt1: 8 VCU

BO_ 2147484418 BMSRpt2: 8 VCU
 SG_ StrtgBattVolt : 40|16@1+ (0.01,0) [0|0] "V" Vector__XXX
 SG_ RlySts : 0|2@1+ (1,0) [0|0] "" Vector__XXX

BO_ 2147553428 VINRpt: 1 VCU
 SG_ VINNum : 0|8@1+ (1.02,0) [0|0] "" Vector__XXX

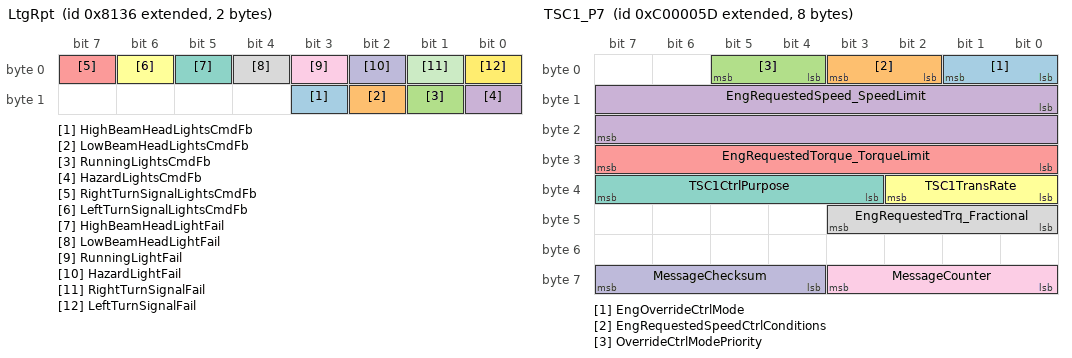
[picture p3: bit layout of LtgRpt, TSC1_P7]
BO_ 2147516726 LtgRpt: 2 VCU
 SG_ HighBeamHeadLightsCmdFb : 11|1@1+ (1,0) [0|1] "" Vector__XXX
 SG_ LowBeamHeadLightsCmdFb : 10|1@1+ (1,0) [0|1] "" Vector__XXX
 SG_ RunningLightsCmdFb : 9|1@1+ (1,0) [0|1] "" Vector__XXX
 SG_ HazardLightsCmdFb : 8|1@1+ (1,0) [0|1] "" Vector__XXX
 SG_ RightTurnSignalLightsCmdFb : 7|1@1+ (1,0) [0|1] "" Vector__XXX
 SG_ LeftTurnSignalLightsCmdFb : 6|1@1+ (1,0) [0|1] "" Vector__XXX
 SG_ HighBeamHeadLightFail : 5|1@1+ (1,0) [0|1] "" Vector__XXX
 SG_ LowBeamHeadLightFail : 4|1@1+ (1,0) [0|1] "" Vector__XXX
 SG_ RunningLightFail : 3|1@1+ (1,0) [0|1] "" Vector__XXX
 SG_ HazardLightFail : 2|1@1+ (1,0) [0|1] "" Vector__XXX
 SG_ RightTurnSignalFail : 1|1@1+ (1,0) [0|1] "" Vector__XXX
 SG_ LeftTurnSignalFail : 0|1@1+ (1,0) [0|1] "" Vector__XXX

BO_ 2147516724 VehLogRpt3: 8 VCU

BO_ 2147516722 VehLatRpt3: 8 VCU

BO_ 2147516720 VehLatRpt2: 8 VCU

BO_ 2147516712 AirBrkRpt2: 8 VCU

BO_ 2147516710 AirBrkRpt1: 8 VCU
 SG_ XPR1CtrlSts : 32|4@1+ (1,0) [0|15] "" Vector__XXX
 SG_ XPRPReq : 24|8@1+ (0.4,0) [0|255] "%" Vector__XXX
 SG_ PrimDrvrPDmd : 16|8@1+ (80,0) [0|255] "mbar" Vector__XXX
 SG_ AirBrkSts : 8|4@1+ (1,0) [0|15] "" Vector__XXX
 SG_ PrimDelivery : 0|8@1+ (80,0) [0|20400] "mbar" Vector__XXX

BO_ 2147516708 EngBrkRpt: 8 VCU
 SG_ EngBrkSts : 8|4@1+ (1,0) [0|15] "" Vector__XXX
 SG_ ActEngBrkTqPerc : 0|8@1+ (1,-125) [-125|125] "%" Vector__XXX

BO_ 2147516706 BrkRpt2: 8 VCU

BO_ 2147516704 BrkRpt1: 8 VCU
 SG_ BrkPedlPos : 0|8@1+ (0.4,0) [0|102] "%" Vector__XXX

BO_ 2147516696 TrsmRpt3: 8 VCU

BO_ 2147516694 TrsmRpt2: 8 VCU
 SG_ TrsmSts : 16|4@1+ (1,0) [0|15] "" Vector__XXX
 SG_ TrsmActGearRat : 0|16@1+ (0.001,0) [0|64.255] "" Vector__XXX

BO_ 2147516692 TrsmRpt1: 8 VCU
 SG_ TrsmShiftInProc : 40|2@1- (1,0) [0|3] "" Vector__XXX
 SG_ TrsmInSpd : 24|16@1+ (0.125,0) [0|8031.88] "rpm" Vector__XXX
 SG_ TrsmOutSpd : 8|16@1+ (0.125,0) [0|8031.88] "rpm" Vector__XXX
 SG_ CurrentGear : 0|8@1+ (1,-125) [-125|125] "" Vector__XXX

BO_ 2147516690 EngRpt3: 8 VCU
 SG_ EngSts : 0|4@1+ (1,0) [0|15] "" Vector__XXX

BO_ 2147516688 EngRpt2: 8 VCU
 SG_ FuLvl2 : 56|8@1+ (0.4,0) [0|102] "" Vector__XXX
 SG_ FuLvl1 : 48|8@1+ (0.4,0) [0|102] "" Vector__XXX
 SG_ EngAvrgFuEco : 32|16@1+ (0.001953,0) [0|125.49] "km/L" Vector__XXX
 SG_ EngInstantaneousFuEco : 16|16@1+ (0.001953,0) [0|125.49] "" Vector__XXX
 SG_ EngFuRate : 0|16@1+ (0.05,0) [0|3212.75] "L/h" Vector__XXX

BO_ 2147516680 EngRpt1: 8 VCU
 SG_ EngNomFricPerTq : 24|8@1+ (1,-125) [-125|130] "%" Vector__XXX
 SG_ EngCooltT : 16|8@1+ (1,-40) [-40|215] "deg C" Vector__XXX
 SG_ EngTq : 8|8@1+ (1,-125) [-125|130] "%" Vector__XXX
 SG_ EngSpd : 0|8@1+ (12.5,0) [0|3187.5] "rpm" Vector__XXX

BO_ 2147516678 SteerColnCmdRpt: 8 VCU
 SG_ MessageChecksum : 60|4@1+ (1,0) [0|15] "" Vector__XXX
 SG_ MessageCounter : 56|4@1+ (1,0) [0|15] "" Vector__XXX
 SG_ SteerCmd : 8|32@1- (0.04395,0) [0|0] "deg" Vector__XXX
 SG_ SteerMod : 0|8@1+ (1,0) [0|0] "" Vector__XXX

BO_ 2147516676 SteerGearCmdRpt: 8 VCU
 SG_ MessageChecksum : 60|4@1+ (1,0) [0|15] "" Vector__XXX
 SG_ MessageCounter : 56|4@1+ (1,0) [0|15] "" Vector__XXX
 SG_ SteerCmd : 8|32@1- (0.04395,0) [0|0] "deg" Vector__XXX
 SG_ SteerMod : 0|8@1+ (1,0) [0|0] "" Vector__XXX

BO_ 2147516674 SteerRpt2: 8 VCU
 SG_ SteerTq : 40|16@1- (0.00097656,0) [0|0] "Nm" Vector__XXX
 SG_ SteerGearCentrPos : 24|16@1- (0.04395,0) [0|0] "deg" Vector__XXX
 SG_ SteerColnCentrPos : 8|16@1- (0.04395,0) [0|0] "deg" Vector__XXX
 SG_ MessageChecksum : 60|4@1+ (1,0) [0|15] "" Vector__XXX
 SG_ MessageCounter : 56|4@1+ (1,0) [0|15] "" Vector__XXX
 SG_ SteerColnSts : 4|4@1+ (1,0) [0|0] "" Vector__XXX
 SG_ SteerGearSts : 0|4@1+ (1,0) [0|3] "" Vector__XXX

BO_ 2147516536 CamClnCmd: 8 Server

BO_ 2147516551 LogCmdOpt: 8 Server
 SG_ MessageChecksum : 60|4@1+ (1,0) [0|15] "" Vector__XXX
 SG_ MessageCounter : 56|4@1+ (1,0) [0|15] "" Vector__XXX
 SG_ BrkPTar : 24|8@1+ (0.4,0) [0|102] "%" Vector__XXX
 SG_ GearTar : 16|8@1+ (1,-125) [-125|130] "" Vector__XXX
 SG_ EngBrkTqPercTar : 8|8@1+ (1,-125) [-125|130] "%" Vector__XXX
 SG_ EngTqPercTar : 0|8@1+ (1,-125) [-125|125] "%" Vector__XXX

BO_ 2147614738 IMUInfo: 8 Server
 SG_ PitchRate : 56|8@1- (0.01,0) [-1.28|1.27] "rad/s" Vector__XXX
 SG_ RollRate : 48|8@1- (0.01,0) [-1.28|1.27] "rad/s" Vector__XXX
 SG_ YawRate : 32|16@1- (0.0001,0) [-3.2768|3.2767] "rad/s" Vector__XXX
 SG_ Ay : 16|16@1- (0.001,0) [-32.768|32.767] "m/s^2" Vector__XXX
 SG_ Ax : 0|16@1- (0.001,0) [-32.768|32.767] "m/s^2" Vector__XXX

BO_ 2147614736 LocalInfo2: 8 Server

BO_ 2147614728 LocalInfo1: 8 Server

BO_ 2147614726 PlanningInfo2: 8 Server

BO_ 2147614724 PlanningInfo1: 8 Server
 SG_ WP_y : 16|16@1- (0.005,0) [0|0] "m" Vector__XXX
 SG_ WP_x : 0|16@1- (0.005,0) [0|0] "m" Vector__XXX

BO_ 2147614722 PerceptInfo2: 8 Server

BO_ 2147614720 PerceptInfo1: 8 Server

BO_ 2147516545 LatCmdOpt: 8 Server
 SG_ SteerCentrPosReq : 0|16@1- (0.04395,0) [0|0] "deg" Vector__XXX

BO_ 2147516432 AcsyCmd: 8 Server
 SG_ HighBeamHeadLightCmd : 8|2@1+ (1,0) [0|3] "" Vector__XXX
 SG_ LowBeamHeadLightCmd : 6|2@1+ (1,0) [0|3] "" Vector__XXX
 SG_ HazardLightSwitch : 4|2@1+ (1,0) [0|3] "" Vector__XXX
 SG_ RightTurnSignalLightsCmd : 2|2@1+ (1,0) [0|3] "" Vector__XXX
 SG_ LeftTurnSignalLightsCmd : 0|2@1+ (1,0) [0|3] "" Vector__XXX

BO_ 2147516740 LogCmdMai: 8 Server
 SG_ MessageChecksum : 60|4@1+ (1,0) [0|15] "" Vector__XXX
 SG_ MessageCounter : 56|4@1+ (1,0) [0|15] "" Vector__XXX
 SG_ LogCtrlUrgency : 24|8@1+ (0.4,0) [0|102] "%" Vector__XXX
 SG_ ATar : 0|8@1+ (0.1,-12.5) [-12.5|13] "" Vector__XXX
 SG_ LogCtrlMod : 32|4@1+ (1,0) [0|15] "" Vector__XXX
 SG_ SpdTar : 8|16@1+ (0.00390625,0) [0|250.996] "km/h" Vector__XXX

BO_ 2147516744 VehLogRpt1: 8 Vector__XXX
 SG_ LogCtrlUrgencyFb : 56|8@1+ (0.4,0) [0|100] "%" Vector__XXX
 SG_ LogCtrlModFb : 48|4@1+ (1,0) [0|15] "" Vector__XXX
 SG_ SpdTarFb : 32|16@1+ (0.00390625,0) [0|250.996] "km/h" Vector__XXX
 SG_ VehA : 0|8@1+ (0.1,-12.5) [-12.5|13] "" Vector__XXX
 SG_ VehSpd : 8|16@1+ (0.00390625,0) [0|255.99609375] "km/h" Vector__XXX
 SG_ ATarFb : 24|8@1+ (0.1,-12.5) [-12.5|13] "" Vector__XXX

BO_ 2147516742 VehLogRpt2: 8 Vector__XXX
 SG_ LogSts : 28|4@1+ (1,0) [0|15] "" Vector__XXX
 SG_ DrvrBrkSwt : 24|2@1+ (1,0) [0|3] "" Vector__XXX
 SG_ RemAPedlPos : 8|8@1+ (0.4,0) [0|102] "%" Vector__XXX
 SG_ BrkPedlPos : 16|8@1+ (0.4,0) [0|102] "%" Vector__XXX
 SG_ DrvrAPedlPos : 0|8@1+ (0.4,0) [0|102] "%" Vector__XXX

BO_ 2147518720 Sim_GPS: 8 Vector__XXX
 SG_ GPS_Y : 32|32@1- (1,0) [-2147483648|2147483647] "m" Vector__XXX
 SG_ GPS_X : 0|32@1- (1,0) [-2147483648|2147483647] "m" Vector__XXX

BO_ 2566862129 ICU_TurnSignal: 8 Vector__XXX
 SG_ ICU_Sound : 62|1@1+ (1,0) [0|0] "" Vector__XXX
 SG_ ICU_RightTurn : 40|1@1+ (1,0) [0|0] "" Vector__XXX
 SG_ ICU_LeftTurn : 14|1@1+ (1,0) [0|0] "" Vector__XXX

BO_ 2566861383 Test: 6 Vector__XXX
 SG_ Test6 : 40|8@1+ (1,0) [0|0] "" Vector__XXX
 SG_ Test5 : 32|8@1+ (1,0) [0|0] "" Vector__XXX

BO_ 1 New_Message_720: 8 Vector__XXX
 SG_ New_Signal_5011 : 7|8@1+ (1,0) [0|0] "" Vector__XXX

BO_ 2452903544 TestTimer: 8 Vector__XXX
 SG_ CurrentTimer : 0|32@1+ (1,0) [0|0] "" Vector__XXX

BO_ 0 New_Message_718: 8 Vector__XXX
 SG_ New_Signal_5010 : 0|8@1+ (1,0) [0|0] "" Vector__XXX

BO_ 2565537536 P7_ECMReq: 3 VCU
 SG_ ParameterGroupNumber : 0|24@1+ (1,0) [0|16777200] "" Vector__XXX

BO_ 2566843229 P7_CptIdnReport: 8 VCU

BO_ 2348810333 TSC1_P7: 8 Vector__XXX
 SG_ EngOverrideCtrlMode : 0|2@1+ (1,0) [0|3] "" Vector__XXX
 SG_ EngRequestedSpeedCtrlConditions : 2|2@1+ (1,0) [0|3] "" Vector__XXX
 SG_ OverrideCtrlModePriority : 4|2@1+ (1,0) [0|3] "" Vector__XXX
 SG_ EngRequestedSpeed_SpeedLimit : 8|16@1+ (0.125,0) [0|8031.88] "rpm" Vector__XXX
 SG_ EngRequestedTorque_TorqueLimit : 24|8@1+ (1,-125) [-125|125] "%" Vector__XXX
 SG_ TSC1TransRate : 32|3@1+ (1,0) [0|7] "" Vector__XXX
 SG_ TSC1CtrlPurpose : 35|5@1+ (1,0) [0|31] "" Vector__XXX
 SG_ EngRequestedTrq_Fractional : 40|4@1+ (0.125,0) [0|0.875] "%" Vector__XXX
 SG_ MessageCounter : 56|4@1+ (1,0) [0|15] "" Vector__XXX
 SG_ MessageChecksum : 60|4@1+ (1,0) [0|15] "" Vector__XXX

BO_ 2365543969 PGN65366_Rx_0x21: 8 Body
 SG_ xprPresReq : 0|8@1+ (0.4,0) [0|255] "%" Vector__XXX
 SG_ xprCtrlMode : 8|2@1+ (1,0) [0|3] "" Vector__XXX
 SG_ xprPresReduct : 16|8@1+ (0.4,0) [0|255] "%" Vector__XXX
 SG_ xprMsgCntr : 56|4@1+ (1,0) [0|15] "" Vector__XXX
 SG_ xprMsgChksum : 60|4@1+ (1,0) [0|15] "" Vector__XXX

BO_ 2633943600 DM1_Tx_2: 0 Vector__XXX
 SG_ ProtLamp : 0|2@1+ (1,0) [0|3] "" Vector__XXX
 SG_ AmbWarnLamp : 2|2@1+ (1,0) [0|3] "" Vector__XXX
 SG_ RedStopLamp : 4|2@1+ (1,0) [0|3] "" Vector__XXX
 SG_ MFILamp : 6|2@1+ (1,0) [0|3] "" Vector__XXX
 SG_ SPNLow : 16|16@1+ (1,0) [0|65535] "" Vector__XXX
 SG_ SPNHigh : 37|3@1+ (1,0) [0|7] "" Vector__XXX
 SG_ FMI : 32|5@1+ (1,0) [0|31] "" Vector__XXX
 SG_ OcCnt : 40|7@1+ (1,0) [0|127] "" Vector__XXX
 SG_ CM : 47|1@1+ (1,0) [0|1] "" Vector__XXX

BO_ 2365544037 XPRCmd_Navistar65: 8 Body
 SG_ xprPresReq : 0|8@1+ (0.4,0) [0|255] "%" Vector__XXX
 SG_ xprCtrlMode : 8|2@1+ (1,0) [0|3] "" Vector__XXX
 SG_ xprPresReduct : 16|8@1+ (0.4,0) [0|255] "%" Vector__XXX
 SG_ xprMsgCntr : 56|4@1+ (1,0) [0|15] "" Vector__XXX
 SG_ xprMsgChksum : 60|4@1+ (1,0) [0|15] "" Vector__XXX

BO_ 2565406512 AckPGN_Tx: 8 Brakes
 SG_ ControlByte : 0|8@1+ (1,0) [0|255] "" Vector__XXX
 SG_ GroupFuncVal : 8|8@1+ (1,0) [0|255] "" Vector__XXX
 SG_ ECUAddress : 32|8@1+ (1,0) [0|255] "" Vector__XXX
 SG_ RequestedPGN : 40|16@1+ (1,0) [0|65535] "" Vector__XXX

BO_ 2298375728 HRW2C2_Tx: 8 Brakes
 SG_ V_FL : 0|16@1+ (0.00390625,0) [0|65535] "km/h" Vector__XXX
 SG_ V_FR : 16|16@1+ (0.00390625,0) [0|65535] "km/h" Vector__XXX
 SG_ V_RL : 32|16@1+ (0.00390625,0) [0|65535] "km/h" Vector__XXX
 SG_ V_RR : 48|16@1+ (0.00390625,0) [0|65535] "km/h" Vector__XXX

BO_ 2632777520 BAM_Tx: 8 Brakes
 SG_ ControlByte : 0|8@1+ (1,0) [0|255] "" Vector__XXX
 SG_ MsgSize_Bytes : 8|16@1+ (1,0) [0|65535] "" Vector__XXX
 SG_ PacketsNum : 24|8@1+ (1,0) [0|255] "" Vector__XXX
 SG_ PacketedPGN : 40|16@1+ (1,0) [0|65535] "" Vector__XXX

BO_ 2632711984 DT_Tx: 8 Brakes
 SG_ SeqNum : 0|8@1+ (1,0) [0|255] "" Vector__XXX
 SG_ Data1 : 8|8@1+ (1,0) [0|255] "" Vector__XXX
 SG_ Data2 : 16|8@1+ (1,0) [0|255] "" Vector__XXX
 SG_ Data3 : 24|8@1+ (1,0) [0|255] "" Vector__XXX
 SG_ Data4 : 32|8@1+ (1,0) [0|255] "" Vector__XXX
 SG_ Data5 : 40|8@1+ (1,0) [0|255] "" Vector__XXX
 SG_ Data6 : 48|8@1+ (1,0) [0|255] "" Vector__XXX
 SG_ Data7 : 56|8@1+ (1,0) [0|255] "" Vector__XXX

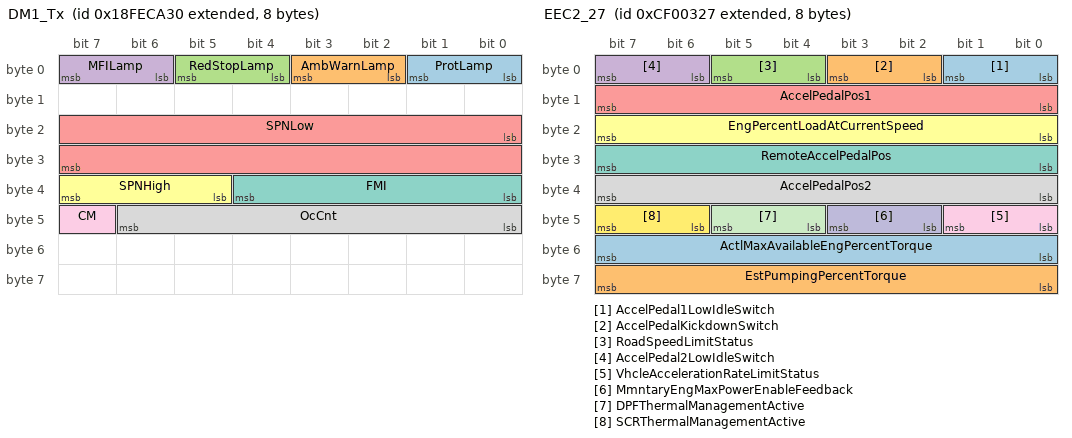
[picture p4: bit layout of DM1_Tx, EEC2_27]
BO_ 2566834736 DM1_Tx: 8 Brakes
 SG_ ProtLamp : 0|2@1+ (1,0) [0|3] "" Vector__XXX
 SG_ AmbWarnLamp : 2|2@1+ (1,0) [0|3] "" Vector__XXX
 SG_ RedStopLamp : 4|2@1+ (1,0) [0|3] "" Vector__XXX
 SG_ MFILamp : 6|2@1+ (1,0) [0|3] "" Vector__XXX
 SG_ SPNLow : 16|16@1+ (1,0) [0|65535] "" Vector__XXX
 SG_ SPNHigh : 37|3@1+ (1,0) [0|7] "" Vector__XXX
 SG_ FMI : 32|5@1+ (1,0) [0|31] "" Vector__XXX
 SG_ OcCnt : 40|7@1+ (1,0) [0|127] "" Vector__XXX
 SG_ CM : 47|1@1+ (1,0) [0|1] "" Vector__XXX

BO_ 2566852135 LightIndicator: 4 Vector__XXX
 SG_ RightLight : 25|1@1+ (1,0) [0|1] "" Vector__XXX
 SG_ LeftLight : 24|1@1+ (1,0) [0|1] ""  VCU

BO_ 2566865191 LightCmd: 8 VCU
 SG_ DRLFrontLeft : 46|2@1+ (1,0) [0|3] "" Vector__XXX
 SG_ DRLFrontRight : 44|2@1+ (1,0) [0|3] "" Vector__XXX
 SG_ HazardSideRight : 40|2@1+ (1,0) [0|3] "" Vector__XXX
 SG_ HazardSideLeft : 42|2@1+ (1,0) [0|3] "" Vector__XXX
 SG_ BrkHazardRearLeft : 36|2@1+ (1,0) [0|3] "" Vector__XXX
 SG_ BrkHazardRearRight : 34|2@1+ (1,0) [0|3] "" Vector__XXX
 SG_ ReverseLight : 32|2@1+ (1,0) [0|3] "" Vector__XXX
 SG_ RearParkLight : 30|2@1+ (1,0) [0|3] "" Vector__XXX
 SG_ HighBeamRight : 28|2@1+ (1,0) [0|3] "" Vector__XXX
 SG_ HighBeamLeft : 26|2@1+ (1,0) [0|3] "" Vector__XXX
 SG_ FrontParkLight : 24|2@1+ (1,0) [0|3] "" Vector__XXX
 SG_ FrontFogLight : 22|2@1+ (1,0) [0|3] "" Vector__XXX
 SG_ RunRight : 20|2@1+ (1,0) [0|3] "" Vector__XXX
 SG_ RunLeft : 18|2@1+ (1,0) [0|3] "" Vector__XXX
 SG_ RightCmd : 16|2@1+ (1,0) [0|3] "" Vector__XXX
 SG_ LeftCmd : 14|2@1+ (1,0) [0|3] "" Vector__XXX
 SG_ Reserve : 0|14@1+ (1,0) [0|0] "" Vector__XXX

BO_ 2364539687 EEC2_27: 8 Vector__XXX
 SG_ AccelPedal1LowIdleSwitch : 0|2@1+ (1,0) [0|3] "" Vector__XXX
 SG_ AccelPedalKickdownSwitch : 2|2@1+ (1,0) [0|3] "" Vector__XXX
 SG_ RoadSpeedLimitStatus : 4|2@1+ (1,0) [0|3] "" Vector__XXX
 SG_ AccelPedal2LowIdleSwitch : 6|2@1+ (1,0) [0|3] "" Vector__XXX
 SG_ AccelPedalPos1 : 8|8@1+ (0.4,0) [0|100] "%" Vector__XXX
 SG_ EngPercentLoadAtCurrentSpeed : 16|8@1+ (1,0) [0|250] "%" Vector__XXX
 SG_ RemoteAccelPedalPos : 24|8@1+ (0.4,0) [0|100] "%" Vector__XXX
 SG_ AccelPedalPos2 : 32|8@1+ (0.4,0) [0|100] "%" Vector__XXX
 SG_ VhcleAccelerationRateLimitStatus : 40|2@1+ (1,0) [0|3] "" Vector__XXX
 SG_ MmntaryEngMaxPowerEnableFeedback : 42|2@1+ (1,0) [0|3] "" Vector__XXX
 SG_ DPFThermalManagementActive : 44|2@1+ (1,0) [0|3] "" Vector__XXX
 SG_ SCRThermalManagementActive : 46|2@1+ (1,0) [0|3] "" Vector__XXX
 SG_ ActlMaxAvailableEngPercentTorque : 48|8@1+ (0.4,0) [0|100] "%" Vector__XXX
 SG_ EstPumpingPercentTorque : 56|8@1+ (1,-125) [-125|125] "%" Vector__XXX

BO_ 2566844711 CCVS_C_Cru: 8 Vector__XXX
 SG_ TwoSpeedAxleSwitch : 0|2@1+ (1,0) [0|3] "" Vector__XXX
 SG_ ParkingBrakeSwitch : 2|2@1+ (1,0) [0|3] "" Vector__XXX
 SG_ CruiseCtrlPauseSwitch : 4|2@1+ (1,0) [0|3] "" Vector__XXX
 SG_ ParkBrakeReleaseInhibitRq : 6|2@1+ (1,0) [0|3] "" Vector__XXX
 SG_ WheelBasedVehicleSpeed : 8|16@1+ (0.003906,0) [0|250.98] "km/h" Vector__XXX
 SG_ CruiseCtrlActive : 24|2@1+ (1,0) [0|3] "" Vector__XXX
 SG_ CruiseCtrlEnableSwitch : 26|2@1+ (1,0) [0|3] "" Vector__XXX
 SG_ BrakeSwitch : 28|2@1+ (1,0) [0|3] "" Vector__XXX
 SG_ ClutchSwitch : 30|2@1+ (1,0) [0|3] "" Vector__XXX
 SG_ CruiseCtrlSetSwitch : 32|2@1+ (1,0) [0|3] "" Vector__XXX
 SG_ CruiseCtrlCoastSwitch : 34|2@1+ (1,0) [0|3] "" Vector__XXX
 SG_ CruiseCtrlResumeSwitch : 36|2@1+ (1,0) [0|3] "" Vector__XXX
 SG_ CruiseCtrlAccelerateSwitch : 38|2@1+ (1,0) [0|3] "" Vector__XXX
 SG_ CruiseCtrlSetSpeed : 40|8@1+ (1,0) [0|250] "km/h" Vector__XXX
 SG_ PTOGovernorState : 48|5@1+ (1,0) [0|31] "" Vector__XXX
 SG_ CruiseCtrlStates : 53|3@1+ (1,0) [0|7] "" Vector__XXX
 SG_ EngIdleIncrementSwitch : 56|2@1+ (1,0) [0|3] "" Vector__XXX
 SG_ EngIdleDecrementSwitch : 58|2@1+ (1,0) [0|3] "" Vector__XXX
 SG_ EngTestModeSwitch : 60|2@1+ (1,0) [0|3] "" Vector__XXX
 SG_ EngShutdownOverrideSwitch : 62|2@1+ (1,0) [0|3] ""  VCU

BO_ 2566844773 CCVS1_Navistar_Control: 8 Vector__XXX
 SG_ TwoSpdAxleSw : 0|2@1+ (1,0) [0|3] "bit" Vector__XXX
 SG_ ParkingBrakeSw : 2|2@1+ (1,0) [0|3] "" Vector__XXX
 SG_ CruiseCtrlPauseSw : 4|2@1+ (1,0) [0|3] "" Vector__XXX
 SG_ ParkBrakeReleaseInhibitReq : 6|2@1+ (1,0) [0|3] "" Vector__XXX
 SG_ WheelBasedVehSpd : 8|16@1+ (0.003906,0) [0|250.98] "km/h" Vector__XXX
 SG_ CruiseCtrlAct : 24|2@1+ (1,0) [0|3] "" Vector__XXX
 SG_ CruiseCtrlEnSw : 26|2@1+ (1,0) [0|3] "" Vector__XXX
 SG_ BrkSw : 28|2@1+ (1,0) [0|3] "" Vector__XXX
 SG_ ClutchSw : 30|2@1+ (1,0) [0|3] "" Vector__XXX
 SG_ CruiseCtrlSetSw : 32|2@1+ (1,0) [0|3] "" Vector__XXX
 SG_ CruiseCtrlCoastSw : 34|2@1+ (1,0) [0|3] "" Vector__XXX
 SG_ CruiseCtrlReSw : 36|2@1+ (1,0) [0|3] "" Vector__XXX
 SG_ CruiseCtrlAccSw : 38|2@1+ (1,0) [0|3] "" Vector__XXX
 SG_ CruiseCtrlSetSpd : 40|8@1+ (1,0) [0|250] "" Vector__XXX
 SG_ PTOGovernorSt : 48|5@1+ (1,0) [0|31] "" Vector__XXX
 SG_ CruiseCtrlSt : 53|3@1+ (1,0) [0|7] "" Vector__XXX
 SG_ EngIdleIncreSw : 56|2@1+ (1,0) [0|3] "" Vector__XXX
 SG_ EngIdleDecreSw : 58|2@1+ (1,0) [0|3] "" Vector__XXX
 SG_ EngDiagTestMdSw : 60|2@1+ (1,0) [0|3] "" Vector__XXX
 SG_ EngShutOvrdSw : 62|2@1+ (1,0) [0|3] "" Vector__XXX

BO_ 2566843392 VI_Navistar: 8 Vector__XXX
 SG_ VehicleIdentificationNumber : 0|8@1+ (1.02,0) [0|255] "per byte" Vector__XXX

BO_ 2566838767 AUXIO1_NavistarCtrl: 8 Vector__XXX
 SG_ AuxI_O03_AutoSwLtgColor : 2|2@1+ (1,0) [0|3] "" Vector__XXX
 SG_ AuxI_O04_AutoSwSts : 0|2@1+ (1,0) [0|3] "" Vector__XXX
 SG_ AuxI_O02_AutoSwLtgSts : 4|2@1+ (1,0) [0|3] "" Vector__XXX
 SG_ AuxI_O01_PrkBrkCmd : 6|2@1+ (1,0) [0|3] "" Vector__XXX
 SG_ AuxI_O08 : 8|2@1+ (1,0) [0|3] "" Vector__XXX
 SG_ RightTurnRq : 10|2@1+ (1,0) [0|3] "" Vector__XXX
 SG_ LeftTurnRq : 12|2@1+ (1,0) [0|3] "" Vector__XXX
 SG_ AuxI_O05_CityHorn : 14|2@1+ (1,0) [0|3] "" Vector__XXX
 SG_ AuxI_O12 : 16|2@1+ (1,0) [0|3] "" Vector__XXX
 SG_ AuxI_O11 : 18|2@1+ (1,0) [0|3] "" Vector__XXX
 SG_ AuxI_O10 : 20|2@1+ (1,0) [0|3] "" Vector__XXX
 SG_ AuxI_O09 : 22|2@1+ (1,0) [0|3] "" Vector__XXX
 SG_ AuxI_O16 : 24|2@1+ (1,0) [0|3] "" Vector__XXX
 SG_ AuxI_O15 : 26|2@1+ (1,0) [0|3] "" Vector__XXX
 SG_ AuxI_O14 : 28|2@1+ (1,0) [0|3] "" Vector__XXX
 SG_ AuxI_O13 : 30|2@1+ (1,0) [0|3] "" Vector__XXX
 SG_ AuxI_OChannel1 : 32|16@1+ (1,0) [0|64255] "counts" Vector__XXX
 SG_ AuxI_OChannel2 : 48|16@1+ (1,0) [0|64255] "counts" Vector__XXX

BO_ 2566803735 ACC2_Navistar: 8 Vector__XXX
 SG_ ACCUsageDemand : 0|2@1+ (1,0) [0|3] "" Vector__XXX
 SG_ RequestedACCDistanceMode : 5|3@1+ (1,0) [0|7] "" Vector__XXX

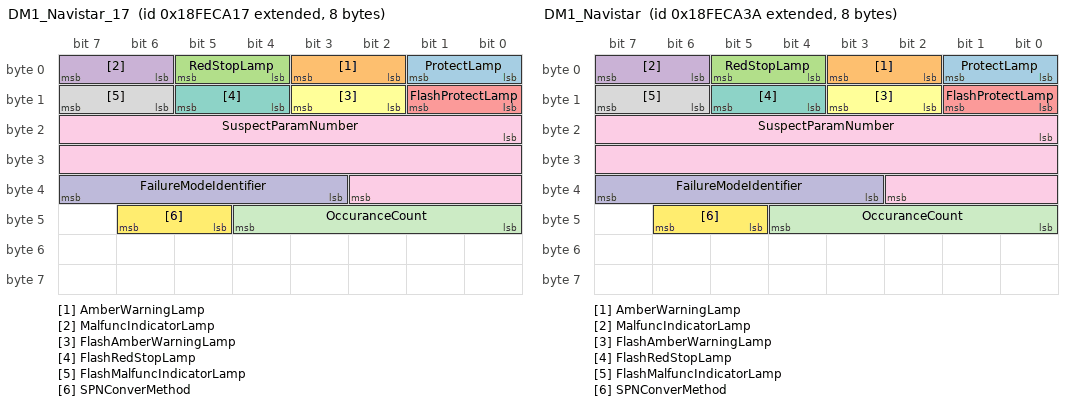
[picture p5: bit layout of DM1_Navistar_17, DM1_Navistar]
BO_ 2566834711 DM1_Navistar_17: 8 Vector__XXX
 SG_ ProtectLamp : 0|2@1+ (1,0) [0|3] "" Vector__XXX
 SG_ AmberWarningLamp : 2|2@1+ (1,0) [0|3] "" Vector__XXX
 SG_ RedStopLamp : 4|2@1+ (1,0) [0|3] "" Vector__XXX
 SG_ MalfuncIndicatorLamp : 6|2@1+ (1,0) [0|3] "" Vector__XXX
 SG_ FlashProtectLamp : 8|2@1+ (1,0) [0|3] "" Vector__XXX
 SG_ FlashAmberWarningLamp : 10|2@1+ (1,0) [0|3] "" Vector__XXX
 SG_ FlashRedStopLamp : 12|2@1+ (1,0) [0|3] "" Vector__XXX
 SG_ FlashMalfuncIndicatorLamp : 14|2@1+ (1,0) [0|3] "" Vector__XXX
 SG_ SuspectParamNumber : 16|19@1+ (1,0) [0|524287] "" Vector__XXX
 SG_ FailureModeIdentifier : 35|5@1+ (1,0) [0|31] "" Vector__XXX
 SG_ OccuranceCount : 40|5@1+ (1,0) [0|31] "" Vector__XXX
 SG_ SPNConverMethod : 45|2@1+ (1,0) [0|3] "" Vector__XXX

BO_ 2566846987 B1_Navistar_0B: 8 Vector__XXX
 SG_ BrkAppPress : 0|8@1+ (4,0) [0|1000] "kPa" Vector__XXX
 SG_ BrkPrimPress : 8|8@1+ (4,0) [0|1000] "kPa" Vector__XXX
 SG_ BrkSecondPress : 16|8@1+ (4,0) [0|1000] "kPa" Vector__XXX
 SG_ ParkingBrkAct : 24|2@1+ (1,0) [0|3] "" Vector__XXX
 SG_ ParkingBrkRdWarnSig : 32|2@1+ (1,0) [0|3] "" Vector__XXX
 SG_ ParkBrkReleasenhibitSt : 40|2@1+ (1,0) [0|3] "" Vector__XXX

BO_ 2566844683 CCVS_OnlyD_spd: 8 Vector__XXX
 SG_ TwoSpdAxleSw : 0|2@1+ (1,0) [0|3] "bit" Vector__XXX
 SG_ ParkingBrakeSw : 2|2@1+ (1,0) [0|3] "" Vector__XXX
 SG_ CruiseCtrlPauseSw : 4|2@1+ (1,0) [0|3] "" Vector__XXX
 SG_ ParkBrakeReleaseInhibitReq : 6|2@1+ (1,0) [0|3] "" Vector__XXX
 SG_ WheelBasedVehSpd : 8|16@1+ (0.003906,0) [0|250.98] "km/h" Vector__XXX
 SG_ CruiseCtrlAct : 24|2@1+ (1,0) [0|3] "" Vector__XXX
 SG_ CruiseCtrlEnSw : 26|2@1+ (1,0) [0|3] "" Vector__XXX
 SG_ BrkSw : 28|2@1+ (1,0) [0|3] "" Vector__XXX
 SG_ ClutchSw : 30|2@1+ (1,0) [0|3] "" Vector__XXX
 SG_ CruiseCtrlSetSw : 32|2@1+ (1,0) [0|3] "" Vector__XXX
 SG_ CruiseCtrlCoastSw : 34|2@1+ (1,0) [0|3] "" Vector__XXX
 SG_ CruiseCtrlReSw : 36|2@1+ (1,0) [0|3] "" Vector__XXX
 SG_ CruiseCtrlAccSw : 38|2@1+ (1,0) [0|3] "" Vector__XXX
 SG_ CruiseCtrlSetSpd : 40|8@1+ (1,0) [0|250] "" Vector__XXX
 SG_ PTOGovernorSt : 48|5@1+ (1,0) [0|31] "" Vector__XXX
 SG_ CruiseCtrlSt : 53|3@1+ (1,0) [0|7] "" Vector__XXX
 SG_ EngIdleIncreSw : 56|2@1+ (1,0) [0|3] "" Vector__XXX
 SG_ EngIdleDecreSw : 58|2@1+ (1,0) [0|3] "" Vector__XXX
 SG_ EngDiagTestMdSw : 60|2@1+ (1,0) [0|3] "" Vector__XXX
 SG_ EngShutOvrdSw : 62|2@1+ (1,0) [0|3] ""  VCU

BO_ 2364602883 ETC13: 8 Vector__XXX

BO_ 2566759427 PTODE_Navistar: 8 Vector__XXX
 SG_ EnblSwtchTrnsfrCseOutputShaftPTO : 0|2@1+ (1,0) [0|3] "" Vector__XXX
 SG_ EnableSwitchTransOutputShaftPTO : 2|2@1+ (1,0) [0|3] "" Vector__XXX
 SG_ EnableSwitchTransInputShaftPTO2 : 4|2@1+ (1,0) [0|3] "" Vector__XXX
 SG_ EnableSwitchTransInputShaftPTO1 : 6|2@1+ (1,0) [0|3] "" Vector__XXX
 SG_ EnableSwitchPTOEngFlywheel : 8|2@1+ (1,0) [0|3] "" Vector__XXX
 SG_ EnbleSwitchPTOEngAccessoryDrive1 : 10|2@1+ (1,0) [0|3] "" Vector__XXX
 SG_ EnbleSwitchPTOEngAccessoryDrive2 : 12|2@1+ (1,0) [0|3] "" Vector__XXX
 SG_ EnggmntCnsntTrnsfrCsOtptShaftPTO : 16|2@1+ (1,0) [0|3] "" Vector__XXX
 SG_ EnggmntCnsentTransOutputShaftPTO : 18|2@1+ (1,0) [0|3] "" Vector__XXX
 SG_ EnggmntCnsentTransInputShaftPTO2 : 20|2@1+ (1,0) [0|3] "" Vector__XXX
 SG_ EnggmntCnsentTransInputShaftPTO1 : 22|2@1+ (1,0) [0|3] "" Vector__XXX
 SG_ EngagementConsentPTOEngFlywheel : 24|2@1+ (1,0) [0|3] "" Vector__XXX
 SG_ EnggmntCnsntPTOEngAccssoryDrive1 : 26|2@1+ (1,0) [0|3] "" Vector__XXX
 SG_ EnggmntCnsntPTOEngAccssoryDrive2 : 28|2@1+ (1,0) [0|3] "" Vector__XXX
 SG_ EnggmntSttsTrnsfrCsOtputShaftPTO : 32|2@1+ (1,0) [0|3] "" Vector__XXX
 SG_ EnggmntStatusTransOutputShaftPTO : 34|2@1+ (1,0) [0|3] "" Vector__XXX
 SG_ EnggmntStatusTransInputShaftPTO2 : 36|2@1+ (1,0) [0|3] "" Vector__XXX
 SG_ EnggmntStatusTransInputShaftPTO1 : 38|2@1+ (1,0) [0|3] "" Vector__XXX
 SG_ EngagementStatusPTOEngFlywheel : 40|2@1+ (1,0) [0|3] "" Vector__XXX
 SG_ EnggmntSttsPTOEngAccessoryDrive1 : 42|2@1+ (1,0) [0|3] "" Vector__XXX
 SG_ EnggmntSttsPTOEngAccessoryDrive2 : 44|2@1+ (1,0) [0|3] "" Vector__XXX
 SG_ AtLeastOnePTOEngaged : 48|2@1+ (1,0) [0|3] "" Vector__XXX

BO_ 2566842913 VW_Navistar: 7 Vector__XXX
 SG_ AxleWeight : 8|16@1+ (0.5,0) [0|32127.5] "kg" Vector__XXX
 SG_ TrailerWeight : 24|16@1+ (2,0) [0|128510] "kg" Vector__XXX
 SG_ CargoWeight : 40|16@1+ (2,0) [0|128510] "kg" Vector__XXX
 SG_ AxleLocation : 0|8@1+ (1,0) [0|255] "" Vector__XXX

BO_ 2565865733 EBC1_Navistar_05: 8 Vector__XXX
 SG_ ASREngCtrlActive : 0|2@1+ (1,0) [0|3] "" Vector__XXX
 SG_ ASRBrakeCtrlActive : 2|2@1+ (1,0) [0|3] "" Vector__XXX
 SG_ AntiLockBrakingActive : 4|2@1+ (1,0) [0|3] "" Vector__XXX
 SG_ EBSBrakeSwitch : 6|2@1+ (1,0) [0|3] "" Vector__XXX
 SG_ BrakePedalPos : 8|8@1+ (0.4,0) [0|100] "%" Vector__XXX
 SG_ ABSOffroadSwitch : 16|2@1+ (1,0) [0|3] "" Vector__XXX
 SG_ ASROffroadSwitch : 18|2@1+ (1,0) [0|3] "" Vector__XXX
 SG_ ASRHillHolderSwitch : 20|2@1+ (1,0) [0|3] "" Vector__XXX
 SG_ TractionCtrlOverrideSwitch : 22|2@1+ (1,0) [0|3] "" Vector__XXX
 SG_ AccelInterlockSwitch : 24|2@1+ (1,0) [0|3] "" Vector__XXX
 SG_ EngDerateSwitch : 26|2@1+ (1,0) [0|3] "" Vector__XXX
 SG_ EngAuxShutdownSwitch : 28|2@1+ (1,0) [0|3] "" Vector__XXX
 SG_ RemoteAccelEnableSwitch : 30|2@1+ (1,0) [0|3] "" Vector__XXX
 SG_ EngRetarderSelection : 32|8@1+ (0.4,0) [0|100] "%" Vector__XXX
 SG_ ABSFullyOperational : 40|2@1+ (1,0) [0|3] "" Vector__XXX
 SG_ EBSRedWarningSignal : 42|2@1+ (1,0) [0|3] "" Vector__XXX
 SG_ ABS_EBSAmberWarningSignal : 44|2@1+ (1,0) [0|3] "" Vector__XXX
 SG_ ATC_ASRInformationSignal : 46|2@1+ (1,0) [0|3] "" Vector__XXX
 SG_ SrcAddrssOfCntrllngDvcFrBrkeCtrl : 48|8@1+ (1,0) [0|255] "" Vector__XXX
 SG_ HaltBrakeSwitch : 58|2@1+ (1,0) [0|3] "" Vector__XXX
 SG_ TrailerABSStatus : 60|2@1+ (1,0) [0|3] "" Vector__XXX
 SG_ TrctrMntdTrailerABSWarningSignal : 62|2@1+ (1,0) [0|3] "" Vector__XXX
 SG_ RailroadModeSwitch : 56|2@1+ (1,0) [0|3] "" Vector__XXX

BO_ 2432498944 EEC9_Navistar: 8 Vector__XXX
 SG_ EngExhstGsRecirculation2ValvePos : 0|16@1+ (0.0025,0) [0|160.637] "%" Vector__XXX
 SG_ EngExhstGsRcirculation2Valve2Pos : 16|16@1+ (0.0025,0) [0|160.637] "%" Vector__XXX
 SG_ CommandedEngFuelRailPress : 32|16@1+ (0.003906,0) [0|250.98] "MPa" Vector__XXX
 SG_ CmmndedEngFuelInjectionCtrlPress : 48|16@1+ (0.003906,0) [0|250.98] "MPa" Vector__XXX

BO_ 2564882209 CM1_Navistar_FF: 8 Vector__XXX
 SG_ RequestedPercentFanSpeed : 0|8@1+ (0.4,0) [0|100] "%" Vector__XXX
 SG_ CabInteriorTempCmd : 8|16@1+ (0.03125,-273) [-273|1734.96875] "deg C" Vector__XXX
 SG_ AuxHeaterCoolantPumpRq : 24|2@1+ (1,0) [0|3] "" Vector__XXX
 SG_ BatteryMainSwitchHoldRq : 26|2@1+ (1,0) [0|3] "" Vector__XXX
 SG_ OperatorSeatDirectionSwitch : 28|2@1+ (1,0) [0|3] "" Vector__XXX
 SG_ SeatBeltSwitch : 30|2@1+ (1,0) [0|3] "" Vector__XXX
 SG_ VhclLmtngSpdGvrnrDecrementSwitch : 34|2@1+ (1,0) [0|3] "" Vector__XXX
 SG_ VhclLmtngSpdGvrnrIncrementSwitch : 36|2@1+ (1,0) [0|3] "" Vector__XXX
 SG_ VhclLmtngSpdGovernorEnableSwitch : 38|2@1+ (1,0) [0|3] "" Vector__XXX
 SG_ DslPrtcltFltrRgnrtnInhibitSwitch : 40|2@1+ (1,0) [0|3] "" Vector__XXX
 SG_ DslPrtcltFltrRgnrtionForceSwitch : 42|2@1+ (1,0) [0|3] "" Vector__XXX
 SG_ AtomaticGearShiftingEnableSwitch : 44|2@1+ (1,0) [0|3] "" Vector__XXX
 SG_ EngAutomaticStartEnableSwitch : 46|2@1+ (1,0) [0|3] "" Vector__XXX
 SG_ AuxHeaterModeRq : 48|4@1+ (1,0) [0|15] "" Vector__XXX
 SG_ RqEngZoneHeating : 52|2@1+ (1,0) [0|3] "" Vector__XXX
 SG_ RqCabZoneHeating : 54|2@1+ (1,0) [0|3] "" Vector__XXX
 SG_ SelectedMaxVehicleSpeedLimit : 56|8@1+ (1,0) [0|250] "" Vector__XXX

BO_ 2566799393 LD_Navistar: 8 Vector__XXX
 SG_ RunningLight : 0|2@1+ (1,0) [0|3] "" Vector__XXX
 SG_ AltBeamHeadLightData : 2|2@1+ (1,0) [0|3] "" Vector__XXX
 SG_ LowBeamHeadLightData : 4|2@1+ (1,0) [0|3] "" Vector__XXX
 SG_ HighBeamHeadLightData : 6|2@1+ (1,0) [0|3] "" Vector__XXX
 SG_ TractorFrontFogLights : 8|2@1+ (1,0) [0|3] "" Vector__XXX
 SG_ RotatingBeaconLight : 10|2@1+ (1,0) [0|3] "" Vector__XXX
 SG_ RightTurnSignalLights : 12|2@1+ (1,0) [0|3] "" Vector__XXX
 SG_ LeftTurnSignalLights : 14|2@1+ (1,0) [0|3] "" Vector__XXX
 SG_ BackUpLightAndAlarmHorn : 16|2@1+ (1,0) [0|3] "" Vector__XXX
 SG_ CenterStopLight : 18|2@1+ (1,0) [0|3] "" Vector__XXX
 SG_ RightStopLight : 20|2@1+ (1,0) [0|3] "" Vector__XXX
 SG_ LeftStopLight : 22|2@1+ (1,0) [0|3] "" Vector__XXX
 SG_ ImplementClearanceLight : 24|2@1+ (1,0) [0|3] "" Vector__XXX
 SG_ TractorClearanceLight : 26|2@1+ (1,0) [0|3] "" Vector__XXX
 SG_ ImplementMarkerLight : 28|2@1+ (1,0) [0|3] "" Vector__XXX
 SG_ TractorMarkerLight : 30|2@1+ (1,0) [0|3] "" Vector__XXX
 SG_ RearFogLights : 32|2@1+ (1,0) [0|3] "" Vector__XXX
 SG_ TrctorUndersideMountedWorkLights : 34|2@1+ (1,0) [0|3] "" Vector__XXX
 SG_ TractorRearLowMountedWorkLights : 36|2@1+ (1,0) [0|3] "" Vector__XXX
 SG_ TractorRearHighMountedWorkLights : 38|2@1+ (1,0) [0|3] "" Vector__XXX
 SG_ TractorSideLowMountedWorkLights : 40|2@1+ (1,0) [0|3] "" Vector__XXX
 SG_ TractorSideHighMountedWorkLights : 42|2@1+ (1,0) [0|3] "" Vector__XXX
 SG_ TractorFrontLowMountedWorkLights : 44|2@1+ (1,0) [0|3] "" Vector__XXX
 SG_ TrctorFrontHighMountedWorkLights : 46|2@1+ (1,0) [0|3] "" Vector__XXX
 SG_ ImplementOEMOption2Light : 48|2@1+ (1,0) [0|3] "" Vector__XXX
 SG_ ImplementOEMOption1Light : 50|2@1+ (1,0) [0|3] "" Vector__XXX
 SG_ ImplementRightFacingWorkLight : 52|2@1+ (1,0) [0|3] "" Vector__XXX
 SG_ ImplementLeftFacingWorkLight : 54|2@1+ (1,0) [0|3] "" Vector__XXX
 SG_ ImplementRightForwardWorkLight : 58|2@1+ (1,0) [0|3] "" Vector__XXX
 SG_ ImplementLeftForwardWorkLight : 60|2@1+ (1,0) [0|3] "" Vector__XXX
 SG_ ImplementRearWorkLight : 62|2@1+ (1,0) [0|3] "" Vector__XXX

BO_ 2564816929 CM1_Navistar: 8 Vector__XXX
 SG_ RequestedPercentFanSpeed : 0|8@1+ (0.4,0) [0|100] "%" Vector__XXX
 SG_ CabInteriorTempCmd : 8|16@1+ (0.03125,-273) [-273|1734.96875] "deg C" Vector__XXX
 SG_ AuxHeaterCoolantPumpRq : 24|2@1+ (1,0) [0|3] "" Vector__XXX
 SG_ BatteryMainSwitchHoldRq : 26|2@1+ (1,0) [0|3] "" Vector__XXX
 SG_ OperatorSeatDirectionSwitch : 28|2@1+ (1,0) [0|3] "" Vector__XXX
 SG_ SeatBeltSwitch : 30|2@1+ (1,0) [0|3] "" Vector__XXX
 SG_ VhclLmtngSpdGvrnrDecrementSwitch : 34|2@1+ (1,0) [0|3] "" Vector__XXX
 SG_ VhclLmtngSpdGvrnrIncrementSwitch : 36|2@1+ (1,0) [0|3] "" Vector__XXX
 SG_ VhclLmtngSpdGovernorEnableSwitch : 38|2@1+ (1,0) [0|3] "" Vector__XXX
 SG_ DslPrtcltFltrRgnrtnInhibitSwitch : 40|2@1+ (1,0) [0|3] "" Vector__XXX
 SG_ DslPrtcltFltrRgnrtionForceSwitch : 42|2@1+ (1,0) [0|3] "" Vector__XXX
 SG_ AtomaticGearShiftingEnableSwitch : 44|2@1+ (1,0) [0|3] "" Vector__XXX
 SG_ EngAutomaticStartEnableSwitch : 46|2@1+ (1,0) [0|3] "" Vector__XXX
 SG_ AuxHeaterModeRq : 48|4@1+ (1,0) [0|15] "" Vector__XXX
 SG_ RqEngZoneHeating : 52|2@1+ (1,0) [0|3] "" Vector__XXX
 SG_ RqCabZoneHeating : 54|2@1+ (1,0) [0|3] "" Vector__XXX
 SG_ SelectedMaxVehicleSpeedLimit : 56|8@1+ (1,0) [0|250] "" Vector__XXX

BO_ 2566846241 VEP1_Navistar: 8 Vector__XXX
 SG_ BatteryPotential_PowerInput1 : 32|16@1+ (0.05,0) [0|3212.75] "V" Vector__XXX
 SG_ KeyswitchBatteryPotential : 48|16@1+ (0.05,0) [0|3212.75] "V" Vector__XXX
 SG_ NetBatteryCurrent : 0|8@1+ (1,-125) [-125|125] "A" Vector__XXX
 SG_ AltCurrent : 8|8@1+ (1,0) [0|250] "A" Vector__XXX
 SG_ ChargingSystemPotential : 16|16@1+ (0.05,0) [0|3212.75] "V" Vector__XXX

BO_ 2566827553 AIR1_Navistar: 8 Vector__XXX
 SG_ PneumaticSupplyPress : 0|8@1+ (8,0) [0|2000] "kPa" Vector__XXX
 SG_ ParkingAnd_orTrailerAirPress : 8|8@1+ (8,0) [0|2000] "kPa" Vector__XXX
 SG_ ServiceBrakeCircuit1AirPress : 16|8@1+ (8,0) [0|2000] "kPa" Vector__XXX
 SG_ ServiceBrakeCircuit2AirPress : 24|8@1+ (8,0) [0|2000] "kPa" Vector__XXX
 SG_ AuxEquipmentSupplyPress : 32|8@1+ (8,0) [0|2000] "kPa" Vector__XXX
 SG_ AirSuspensionSupplyPress : 40|8@1+ (8,0) [0|2000] "kPa" Vector__XXX
 SG_ AirCompressorStatus : 48|2@1+ (1,0) [0|3] ""  VCU

BO_ 2566834746 DM1_Navistar: 8 Vector__XXX
 SG_ ProtectLamp : 0|2@1+ (1,0) [0|3] "" Vector__XXX
 SG_ AmberWarningLamp : 2|2@1+ (1,0) [0|3] "" Vector__XXX
 SG_ RedStopLamp : 4|2@1+ (1,0) [0|3] "" Vector__XXX
 SG_ MalfuncIndicatorLamp : 6|2@1+ (1,0) [0|3] "" Vector__XXX
 SG_ FlashProtectLamp : 8|2@1+ (1,0) [0|3] "" Vector__XXX
 SG_ FlashAmberWarningLamp : 10|2@1+ (1,0) [0|3] "" Vector__XXX
 SG_ FlashRedStopLamp : 12|2@1+ (1,0) [0|3] "" Vector__XXX
 SG_ FlashMalfuncIndicatorLamp : 14|2@1+ (1,0) [0|3] "" Vector__XXX
 SG_ SuspectParamNumber : 16|19@1+ (1,0) [0|524287] "" Vector__XXX
 SG_ FailureModeIdentifier : 35|5@1+ (1,0) [0|31] "" Vector__XXX
 SG_ OccuranceCount : 40|5@1+ (1,0) [0|31] "" Vector__XXX
 SG_ SPNConverMethod : 45|2@1+ (1,0) [0|3] "" Vector__XXX

BO_ 2566847009 B1_Navistar: 8 Vector__XXX
 SG_ BrkAppPress : 0|8@1+ (4,0) [0|1000] "kPa" Vector__XXX
 SG_ BrkPrimPress : 8|8@1+ (4,0) [0|1000] "kPa" Vector__XXX
 SG_ BrkSecondPress : 16|8@1+ (4,0) [0|1000] "kPa" Vector__XXX
 SG_ ParkingBrkAct : 24|2@1+ (1,0) [0|3] "" Vector__XXX
 SG_ ParkingBrkRdWarnSig : 32|2@1+ (1,0) [0|3] "" Vector__XXX
 SG_ ParkBrkReleasenhibitSt : 40|2@1+ (1,0) [0|3] "" Vector__XXX

BO_ 2566846753 AI_Navistar: 8 Vector__XXX
 SG_ DriveAxleLocation : 8|8@1+ (1.02,0) [0|255] "" Vector__XXX
 SG_ DriveAxleLiftAirPress : 16|8@1+ (4,0) [0|1000] "kPa" Vector__XXX
 SG_ DriveAxleTemp : 24|8@1+ (1,-40) [-40|210] "deg C" Vector__XXX
 SG_ DriveAxleLubePress : 32|8@1+ (4,0) [0|1000] "kPa" Vector__XXX
 SG_ SteerAxleTemp : 0|8@1+ (1,-40) [-40|210] "deg C" Vector__XXX
 SG_ SteerAxleLubePress : 56|8@1+ (4,0) [0|1000] "kPa" Vector__XXX

BO_ 2566847521 DD1_Navistar: 8 Vector__XXX
 SG_ WasherFluidLevel : 0|8@1+ (0.4,0) [0|100] "%" Vector__XXX
 SG_ FuelLevel1 : 8|8@1+ (0.4,0) [0|100] "%" Vector__XXX
 SG_ EngFuelFilterDiffPress : 16|8@1+ (2,0) [0|500] "kPa" Vector__XXX
 SG_ EngOilFilterDiffPress : 24|8@1+ (0.5,0) [0|125] "kPa" Vector__XXX
 SG_ CargoAmbientTemp : 32|16@1+ (0.03125,-273) [-273|1734.97] "deg C" Vector__XXX
 SG_ FuelLevel2 : 48|8@1+ (0.4,0) [0|100] "%"  VCU

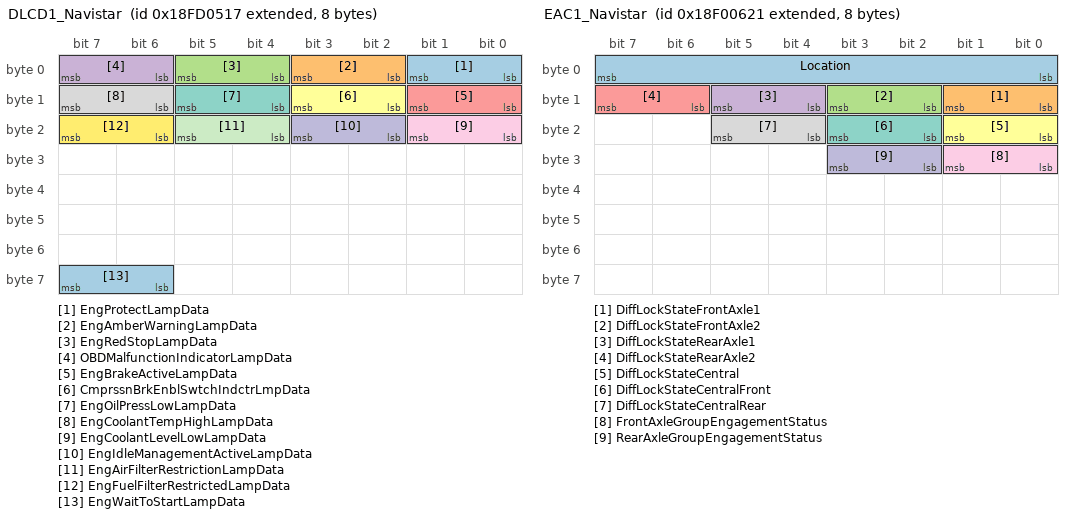
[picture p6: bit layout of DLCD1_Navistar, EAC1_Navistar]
BO_ 2566718743 DLCD1_Navistar: 8 Vector__XXX
 SG_ EngProtectLampData : 0|2@1+ (1,0) [0|3] "" Vector__XXX
 SG_ EngAmberWarningLampData : 2|2@1+ (1,0) [0|3] "" Vector__XXX
 SG_ EngRedStopLampData : 4|2@1+ (1,0) [0|3] "" Vector__XXX
 SG_ OBDMalfunctionIndicatorLampData : 6|2@1+ (1,0) [0|3] "" Vector__XXX
 SG_ EngBrakeActiveLampData : 8|2@1+ (1,0) [0|3] "" Vector__XXX
 SG_ CmprssnBrkEnblSwtchIndctrLmpData : 10|2@1+ (1,0) [0|3] "" Vector__XXX
 SG_ EngOilPressLowLampData : 12|2@1+ (1,0) [0|3] "" Vector__XXX
 SG_ EngCoolantTempHighLampData : 14|2@1+ (1,0) [0|3] "" Vector__XXX
 SG_ EngCoolantLevelLowLampData : 16|2@1+ (1,0) [0|3] "" Vector__XXX
 SG_ EngIdleManagementActiveLampData : 18|2@1+ (1,0) [0|3] "" Vector__XXX
 SG_ EngAirFilterRestrictionLampData : 20|2@1+ (1,0) [0|3] "" Vector__XXX
 SG_ EngFuelFilterRestrictedLampData : 22|2@1+ (1,0) [0|3] "" Vector__XXX
 SG_ EngWaitToStartLampData : 62|2@1+ (1,0) [0|3] "" Vector__XXX

BO_ 2565867041 EAC1_Navistar: 8 Vector__XXX
 SG_ Location : 0|8@1+ (1.02,0) [0|255] "" Vector__XXX
 SG_ DiffLockStateFrontAxle1 : 8|2@1+ (1,0) [0|3] "" Vector__XXX
 SG_ DiffLockStateFrontAxle2 : 10|2@1+ (1,0) [0|3] "" Vector__XXX
 SG_ DiffLockStateRearAxle1 : 12|2@1+ (1,0) [0|3] "" Vector__XXX
 SG_ DiffLockStateRearAxle2 : 14|2@1+ (1,0) [0|3] "" Vector__XXX
 SG_ DiffLockStateCentral : 16|2@1+ (1,0) [0|3] "" Vector__XXX
 SG_ DiffLockStateCentralFront : 18|2@1+ (1,0) [0|3] "" Vector__XXX
 SG_ DiffLockStateCentralRear : 20|2@1+ (1,0) [0|3] "" Vector__XXX
 SG_ FrontAxleGroupEngagementStatus : 24|2@1+ (1,0) [0|3] "" Vector__XXX
 SG_ RearAxleGroupEngagementStatus : 26|2@1+ (1,0) [0|3] "" Vector__XXX

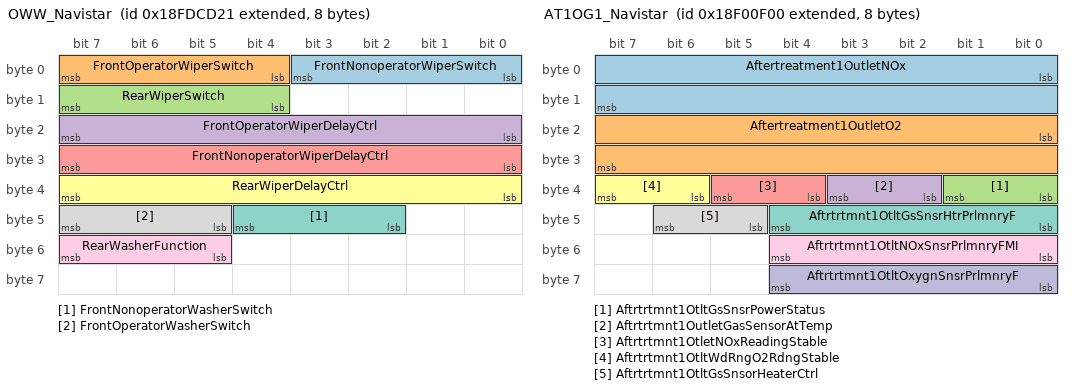
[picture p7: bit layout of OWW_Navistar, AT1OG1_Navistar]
BO_ 2566769953 OWW_Navistar: 8 Vector__XXX
 SG_ FrontNonoperatorWiperSwitch : 0|4@1+ (1,0) [0|15] "" Vector__XXX
 SG_ FrontOperatorWiperSwitch : 4|4@1+ (1,0) [0|15] "" Vector__XXX
 SG_ RearWiperSwitch : 12|4@1+ (1,0) [0|15] "" Vector__XXX
 SG_ FrontOperatorWiperDelayCtrl : 16|8@1+ (0.4,0) [0|100] "%" Vector__XXX
 SG_ FrontNonoperatorWiperDelayCtrl : 24|8@1+ (0.4,0) [0|100] "%" Vector__XXX
 SG_ RearWiperDelayCtrl : 32|8@1+ (0.4,0) [0|100] "%" Vector__XXX
 SG_ FrontNonoperatorWasherSwitch : 42|3@1+ (1,0) [0|7] "" Vector__XXX
 SG_ FrontOperatorWasherSwitch : 45|3@1+ (1,0) [0|7] "" Vector__XXX
 SG_ RearWasherFunction : 53|3@1+ (1,0) [0|7] "" Vector__XXX

BO_ 2566838561 AUXIO1_NavistarMonitor: 8 Vector__XXX
 SG_ AuxI_O03_AutoSwLtgColor : 2|2@1+ (1,0) [0|3] "" Vector__XXX
 SG_ AuxI_O04_AutoSwSts : 0|2@1+ (1,0) [0|3] "" Vector__XXX
 SG_ AuxI_O02_AutoSwLtgSts : 4|2@1+ (1,0) [0|3] "" Vector__XXX
 SG_ AuxI_O01_PrkBrkCmd : 6|2@1+ (1,0) [0|3] "" Vector__XXX
 SG_ AuxI_O08 : 8|2@1+ (1,0) [0|3] "" Vector__XXX
 SG_ RightTurnRq : 10|2@1+ (1,0) [0|3] "" Vector__XXX
 SG_ LeftTurnRq : 12|2@1+ (1,0) [0|3] ""  VCU
 SG_ AuxI_O05_CityHorn : 14|2@1+ (1,0) [0|3] "" Vector__XXX
 SG_ AuxI_O12 : 16|2@1+ (1,0) [0|3] "" Vector__XXX
 SG_ AuxI_O11 : 18|2@1+ (1,0) [0|3] "" Vector__XXX
 SG_ AuxI_O10 : 20|2@1+ (1,0) [0|3] "" Vector__XXX
 SG_ AuxI_O09 : 22|2@1+ (1,0) [0|3] "" Vector__XXX
 SG_ AuxI_O16 : 24|2@1+ (1,0) [0|3] "" Vector__XXX
 SG_ AuxI_O15 : 26|2@1+ (1,0) [0|3] "" Vector__XXX
 SG_ AuxI_O14 : 28|2@1+ (1,0) [0|3] "" Vector__XXX
 SG_ AuxI_O13 : 30|2@1+ (1,0) [0|3] "" Vector__XXX
 SG_ AuxI_OChannel1 : 32|16@1+ (1,0) [0|64255] "counts" Vector__XXX
 SG_ AuxI_OChannel2 : 48|16@1+ (1,0) [0|64255] "counts" Vector__XXX

BO_ 2565865761 EBC1_Navistar: 8 Vector__XXX
 SG_ ASREngCtrlActive : 0|2@1+ (1,0) [0|3] "" Vector__XXX
 SG_ ASRBrakeCtrlActive : 2|2@1+ (1,0) [0|3] "" Vector__XXX
 SG_ AntiLockBrakingActive : 4|2@1+ (1,0) [0|3] "" Vector__XXX
 SG_ EBSBrakeSwitch : 6|2@1+ (1,0) [0|3] "" Vector__XXX
 SG_ BrakePedalPos : 8|8@1+ (0.4,0) [0|100] "%" Vector__XXX
 SG_ ABSOffroadSwitch : 16|2@1+ (1,0) [0|3] "" Vector__XXX
 SG_ ASROffroadSwitch : 18|2@1+ (1,0) [0|3] "" Vector__XXX
 SG_ ASRHillHolderSwitch : 20|2@1+ (1,0) [0|3] "" Vector__XXX
 SG_ TractionCtrlOverrideSwitch : 22|2@1+ (1,0) [0|3] "" Vector__XXX
 SG_ AccelInterlockSwitch : 24|2@1+ (1,0) [0|3] "" Vector__XXX
 SG_ EngDerateSwitch : 26|2@1+ (1,0) [0|3] "" Vector__XXX
 SG_ EngAuxShutdownSwitch : 28|2@1+ (1,0) [0|3] "" Vector__XXX
 SG_ RemoteAccelEnableSwitch : 30|2@1+ (1,0) [0|3] "" Vector__XXX
 SG_ EngRetarderSelection : 32|8@1+ (0.4,0) [0|100] "%" Vector__XXX
 SG_ ABSFullyOperational : 40|2@1+ (1,0) [0|3] "" Vector__XXX
 SG_ EBSRedWarningSignal : 42|2@1+ (1,0) [0|3] "" Vector__XXX
 SG_ ABS_EBSAmberWarningSignal : 44|2@1+ (1,0) [0|3] "" Vector__XXX
 SG_ ATC_ASRInformationSignal : 46|2@1+ (1,0) [0|3] "" Vector__XXX
 SG_ SrcAddrssOfCntrllngDvcFrBrkeCtrl : 48|8@1+ (1,0) [0|255] "" Vector__XXX
 SG_ HaltBrakeSwitch : 58|2@1+ (1,0) [0|3] "" Vector__XXX
 SG_ TrailerABSStatus : 60|2@1+ (1,0) [0|3] "" Vector__XXX
 SG_ TrctrMntdTrailerABSWarningSignal : 62|2@1+ (1,0) [0|3] "" Vector__XXX
 SG_ RailroadModeSwitch : 56|2@1+ (1,0) [0|3] "" Vector__XXX

BO_ 2565869312 AT1OG1_Navistar: 8 Vector__XXX
 SG_ Aftertreatment1OutletNOx : 0|16@1+ (0.05,-200) [-200|3012.75] "ppm" Vector__XXX
 SG_ Aftertreatment1OutletO2 : 16|16@1+ (0.000514,-12) [-12|21.0271] "%" Vector__XXX
 SG_ Aftrtrtmnt1OtltGsSnsrPowerStatus : 32|2@1+ (1,0) [0|3] "" Vector__XXX
 SG_ Aftrtrtmnt1OutletGasSensorAtTemp : 34|2@1+ (1,0) [0|3] "" Vector__XXX
 SG_ Aftrtrtmnt1OtletNOxReadingStable : 36|2@1+ (1,0) [0|3] "" Vector__XXX
 SG_ Aftrtrtmnt1OtltWdRngO2RdngStable : 38|2@1+ (1,0) [0|3] "" Vector__XXX
 SG_ Aftrtrtmnt1OtltGsSnsrHtrPrlmnryF : 40|5@1+ (1,0) [0|31] "" Vector__XXX
 SG_ Aftrtrtmnt1OtltGsSnsorHeaterCtrl : 45|2@1+ (1,0) [0|3] "" Vector__XXX
 SG_ Aftrtrtmnt1OtltNOxSnsrPrlmnryFMI : 48|5@1+ (1,0) [0|31] "" Vector__XXX
 SG_ Aftrtrtmnt1OtltOxygnSnsrPrlmnryF : 56|5@1+ (1,0) [0|31] "" Vector__XXX

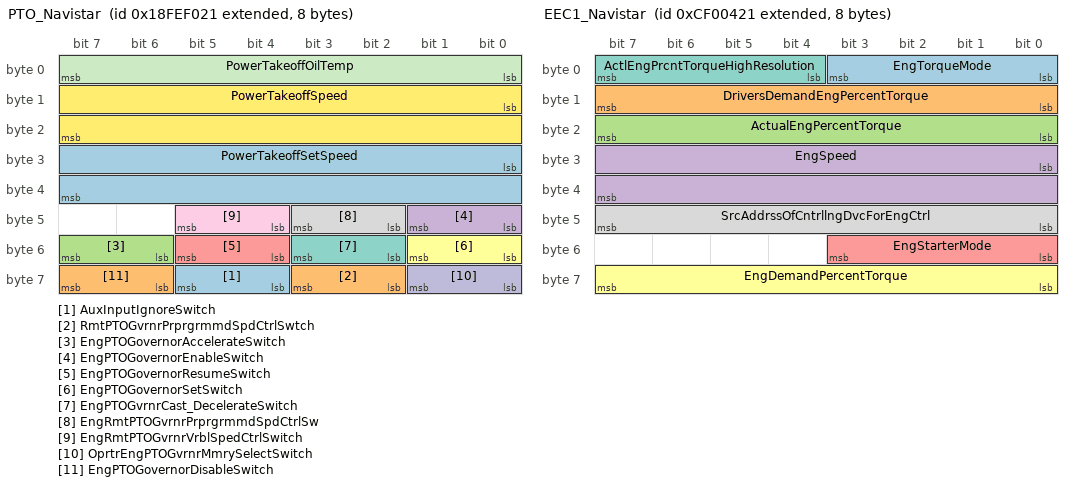
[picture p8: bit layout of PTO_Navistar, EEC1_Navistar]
BO_ 2566844449 PTO_Navistar: 8 Vector__XXX
 SG_ AuxInputIgnoreSwitch : 60|2@1+ (1,0) [0|3] "" Vector__XXX
 SG_ RmtPTOGvrnrPrprgrmmdSpdCtrlSwtch : 58|2@1+ (1,0) [0|3] "" Vector__XXX
 SG_ EngPTOGovernorAccelerateSwitch : 54|2@1+ (1,0) [0|3] "" Vector__XXX
 SG_ EngPTOGovernorEnableSwitch : 40|2@1+ (1,0) [0|3] "" Vector__XXX
 SG_ EngPTOGovernorResumeSwitch : 52|2@1+ (1,0) [0|3] "" Vector__XXX
 SG_ EngPTOGovernorSetSwitch : 48|2@1+ (1,0) [0|3] "" Vector__XXX
 SG_ EngPTOGvrnrCast_DecelerateSwitch : 50|2@1+ (1,0) [0|3] "" Vector__XXX
 SG_ EngRmtPTOGvrnrPrprgrmmdSpdCtrlSw : 42|2@1+ (1,0) [0|3] "" Vector__XXX
 SG_ EngRmtPTOGvrnrVrblSpedCtrlSwitch : 44|2@1+ (1,0) [0|3] "" Vector__XXX
 SG_ OprtrEngPTOGvrnrMmrySelectSwitch : 56|2@1+ (1,0) [0|3] "" Vector__XXX
 SG_ PowerTakeoffOilTemp : 0|8@1+ (1,-40) [-40|210] "deg C" Vector__XXX
 SG_ PowerTakeoffSpeed : 8|16@1+ (0.125,0) [0|8031.88] "rpm" Vector__XXX
 SG_ PowerTakeoffSetSpeed : 24|16@1+ (0.125,0) [0|8031.88] "rpm" Vector__XXX
 SG_ EngPTOGovernorDisableSwitch : 62|2@1+ (1,0) [0|3] "" Vector__XXX

BO_ 2566844705 CCVS_D_Cru: 8 Vector__XXX
 SG_ TwoSpdAxleSw : 0|2@1+ (1,0) [0|3] "bit" Vector__XXX
 SG_ ParkingBrakeSw : 2|2@1+ (1,0) [0|3] "" Vector__XXX
 SG_ CruiseCtrlPauseSw : 4|2@1+ (1,0) [0|3] "" Vector__XXX
 SG_ ParkBrakeReleaseInhibitReq : 6|2@1+ (1,0) [0|3] "" Vector__XXX
 SG_ WheelBasedVehSpd : 8|16@1+ (0.003906,0) [0|250.98] "km/h" Vector__XXX
 SG_ CruiseCtrlAct : 24|2@1+ (1,0) [0|3] "" Vector__XXX
 SG_ CruiseCtrlEnSw : 26|2@1+ (1,0) [0|3] "" Vector__XXX
 SG_ BrkSw : 28|2@1+ (1,0) [0|3] "" Vector__XXX
 SG_ ClutchSw : 30|2@1+ (1,0) [0|3] "" Vector__XXX
 SG_ CruiseCtrlSetSw : 32|2@1+ (1,0) [0|3] "" Vector__XXX
 SG_ CruiseCtrlCoastSw : 34|2@1+ (1,0) [0|3] "" Vector__XXX
 SG_ CruiseCtrlReSw : 36|2@1+ (1,0) [0|3] "" Vector__XXX
 SG_ CruiseCtrlAccSw : 38|2@1+ (1,0) [0|3] "" Vector__XXX
 SG_ CruiseCtrlSetSpd : 40|8@1+ (1,0) [0|250] "" Vector__XXX
 SG_ PTOGovernorSt : 48|5@1+ (1,0) [0|31] "" Vector__XXX
 SG_ CruiseCtrlSt : 53|3@1+ (1,0) [0|7] "" Vector__XXX
 SG_ EngIdleIncreSw : 56|2@1+ (1,0) [0|3] "" Vector__XXX
 SG_ EngIdleDecreSw : 58|2@1+ (1,0) [0|3] "" Vector__XXX
 SG_ EngDiagTestMdSw : 60|2@1+ (1,0) [0|3] "" Vector__XXX
 SG_ EngShutOvrdSw : 62|2@1+ (1,0) [0|3] ""  VCU

BO_ 2364539937 EEC1_Navistar: 8 Vector__XXX
 SG_ EngTorqueMode : 0|4@1+ (1,0) [0|15] "" Vector__XXX
 SG_ DriversDemandEngPercentTorque : 8|8@1+ (1,-125) [-125|125] "%" Vector__XXX
 SG_ ActualEngPercentTorque : 16|8@1+ (1,-125) [-125|125] "%" Vector__XXX
 SG_ EngSpeed : 24|16@1+ (0.125,0) [0|8031.88] "rpm" Vector__XXX
 SG_ EngStarterMode : 48|4@1+ (1,0) [0|15] "" Vector__XXX
 SG_ EngDemandPercentTorque : 56|8@1+ (1,-125) [-125|125] "%" Vector__XXX
 SG_ ActlEngPrcntTorqueHighResolution : 4|4@1+ (1,0) [0|1] "%" Vector__XXX
 SG_ SrcAddrssOfCntrllngDvcForEngCtrl : 40|8@1+ (1,0) [0|255] ""  VCU

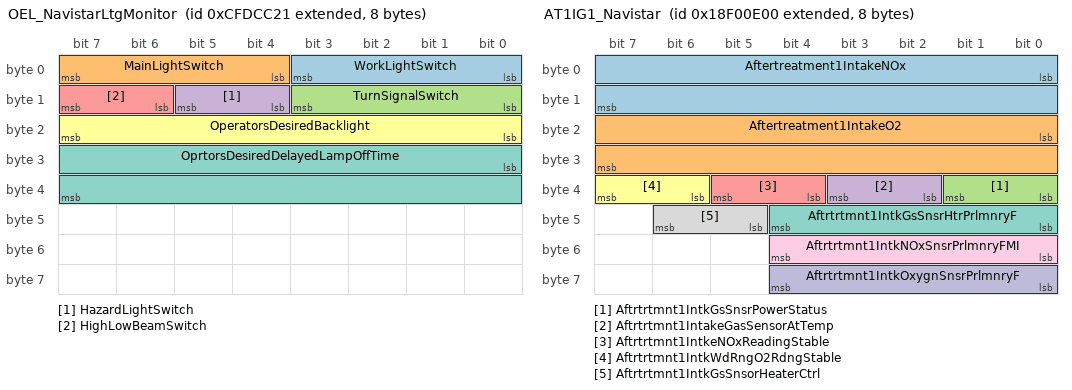
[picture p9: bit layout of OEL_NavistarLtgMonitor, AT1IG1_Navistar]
BO_ 2365443105 OEL_NavistarLtgMonitor: 8 Vector__XXX
 SG_ WorkLightSwitch : 0|4@1+ (1,0) [0|15] "" Vector__XXX
 SG_ MainLightSwitch : 4|4@1+ (1,0) [0|15] "" Vector__XXX
 SG_ TurnSignalSwitch : 8|4@1+ (1,0) [0|15] "" Vector__XXX
 SG_ HazardLightSwitch : 12|2@1+ (1,0) [0|3] "" Vector__XXX
 SG_ HighLowBeamSwitch : 14|2@1+ (1,0) [0|3] "" Vector__XXX
 SG_ OperatorsDesiredBacklight : 16|8@1+ (0.4,0) [0|100] "%" Vector__XXX
 SG_ OprtorsDesiredDelayedLampOffTime : 24|16@1+ (1,0) [0|64255] "s" Vector__XXX

BO_ 2566755328 EEC7_Navistar: 8 Vector__XXX
 SG_ EngExhstGsRecirculation1ValvePos : 0|16@1+ (0.0025,0) [0|160.637] "%" Vector__XXX
 SG_ EngExhstGsRcirculation1Valve2Pos : 16|16@1+ (0.0025,0) [0|160.637] "%" Vector__XXX
 SG_ EngCrnkcsBrtherOilSeparatorSpeed : 32|16@1+ (1,0) [0|64255] "rpm" Vector__XXX
 SG_ CommandedEngIntakeManifoldPress : 48|16@1+ (0.125,0) [0|8031.88] "kPa" Vector__XXX

BO_ 2566839040 EFLP2_Navistar: 8 Vector__XXX
 SG_ EngInjectionCtrlPress : 0|16@1+ (0.003906,0) [0|250.98] "MPa" Vector__XXX
 SG_ EngInjectorMeteringRail1Press : 16|16@1+ (0.003906,0) [0|250.98] "MPa" Vector__XXX
 SG_ EngInjectorTimingRail1Press : 32|16@1+ (0.003906,0) [0|250.98] "MPa" Vector__XXX
 SG_ EngInjectorMeteringRail2Press : 48|16@1+ (0.003906,0) [0|250.98] "MPa" Vector__XXX

BO_ 2633929216 EI1: 8 Vector__XXX
 SG_ EngPrefilterOilPress : 0|8@1+ (4,0) [0|1000] "kPa" Vector__XXX
 SG_ EngExhaustGasPress : 8|16@1+ (0.007812,-250) [-250|251.96] "kPa" Vector__XXX
 SG_ InstantaneousEstBrakePower : 48|16@1+ (0.5,0) [0|32127.5] "kW" Vector__XXX
 SG_ EngGasMassFlowRate1 : 32|16@1+ (0.05,0) [0|3212.75] "kg/h" Vector__XXX
 SG_ EngFuelRackPos : 24|8@1+ (0.4,0) [0|100] "%" Vector__XXX

BO_ 2565869056 AT1IG1_Navistar: 8 Vector__XXX
 SG_ Aftertreatment1IntakeNOx : 0|16@1+ (0.05,-200) [-200|3012.75] "ppm" Vector__XXX
 SG_ Aftertreatment1IntakeO2 : 16|16@1+ (0.000514,-12) [-12|21.0271] "%" Vector__XXX
 SG_ Aftrtrtmnt1IntkGsSnsrPowerStatus : 32|2@1+ (1,0) [0|3] "" Vector__XXX
 SG_ Aftrtrtmnt1IntakeGasSensorAtTemp : 34|2@1+ (1,0) [0|3] "" Vector__XXX
 SG_ Aftrtrtmnt1IntkeNOxReadingStable : 36|2@1+ (1,0) [0|3] "" Vector__XXX
 SG_ Aftrtrtmnt1IntkWdRngO2RdngStable : 38|2@1+ (1,0) [0|3] "" Vector__XXX
 SG_ Aftrtrtmnt1IntkGsSnsrHtrPrlmnryF : 40|5@1+ (1,0) [0|31] "" Vector__XXX
 SG_ Aftrtrtmnt1IntkGsSnsorHeaterCtrl : 45|2@1+ (1,0) [0|3] "" Vector__XXX
 SG_ Aftrtrtmnt1IntkNOxSnsrPrlmnryFMI : 48|5@1+ (1,0) [0|31] "" Vector__XXX
 SG_ Aftrtrtmnt1IntkOxygnSnsrPrlmnryF : 56|5@1+ (1,0) [0|31] "" Vector__XXX

BO_ 2566775073 CACI_Navistar: 8 Vector__XXX
 SG_ CbA_CRfrgrntCmpressorOutletPress : 0|8@1+ (16,0) [0|4000] "kPa" Vector__XXX

BO_ 2298375691 HRW_Navistar: 8 Vector__XXX
 SG_ FrontAxleLeftWheelSpeed : 0|16@1+ (0.003906,0) [0|250.98] "km/h" Vector__XXX
 SG_ FrontAxleRightWheelSpeed : 16|16@1+ (0.003906,0) [0|250.98] "km/h" Vector__XXX
 SG_ RearAxleLeftWheelSpeed : 32|16@1+ (0.003906,0) [0|250.98] "km/h" Vector__XXX
 SG_ RearAxleRightWheelSpeed : 48|16@1+ (0.003906,0) [0|250.98] "km/h" Vector__XXX

BO_ 2566713856 EFTVI1: 8 Vector__XXX

BO_ 2432541440 EEC6_Navistar: 8 Vector__XXX
 SG_ EngDsrdTrbCmprssrBypssActtor1Pos : 48|8@1+ (0.4,0) [0|100] "%" Vector__XXX
 SG_ EngTrbCmprssorBypassActuator1Cmd : 0|16@1+ (1,0) [0|161] "%" Vector__XXX
 SG_ EngTrbCmprssorBypassActuator1Pos : 24|8@1+ (0.4,0) [0|100] "%" Vector__XXX
 SG_ EngTrbCmprssorBypassActuator2Cmd : 32|16@1+ (1,0) [0|161] "%" Vector__XXX
 SG_ EngTrbCmprssrBypssActtr1PrlmnryF : 56|5@1+ (1,0) [0|31] "" Vector__XXX
 SG_ EngTrbCmprssrBypssActtr1TmpSttus : 61|3@1+ (1,0) [0|7] "" Vector__XXX
 SG_ EngVriableGeometryTurboActuator1 : 16|8@1+ (1,0) [0|100] "%" Vector__XXX

BO_ 2364549379 SSI2_Navistar: 8 Vector__XXX
 SG_ PitchAngleExRange : 0|24@1+ (1,-250) [-250|251] "deg" Vector__XXX
 SG_ RollAngleExRange : 24|24@1+ (1,-250) [-250|251] "deg" Vector__XXX
 SG_ PitchAngleExRangeCompensation : 48|2@1+ (1,0) [0|3] "" Vector__XXX
 SG_ PitchAngleExRangeFigureOfMerit : 50|2@1+ (1,0) [0|3] "" Vector__XXX
 SG_ RollAngleExRangeCompensation : 52|2@1+ (1,0) [0|3] "" Vector__XXX
 SG_ RollAngleExRangeFigureOfMerit : 54|2@1+ (1,0) [0|3] "" Vector__XXX
 SG_ RllAndPtchExRngMasurementLatency : 56|8@1+ (0.5,0) [0|125] "ms" Vector__XXX

BO_ 2348941061 TC1_Navistar: 8 Vector__XXX
 SG_ TransGearShiftInhibitRq : 0|2@1+ (1,0) [0|3] "" Vector__XXX
 SG_ TrnsTrqeConverterLockupDisableRq : 2|2@1+ (1,0) [0|3] "" Vector__XXX
 SG_ DisengageDrivelineRq : 4|2@1+ (1,0) [0|3] "" Vector__XXX
 SG_ TransReverseGearShiftInhibitRq : 6|2@1+ (1,0) [0|3] "" Vector__XXX
 SG_ RequestedPercentClutchSlip : 8|8@1+ (1,0) [0|100] "%" Vector__XXX
 SG_ TransRequestedGear : 16|8@1+ (1,-125) [-125|125] "" Vector__XXX
 SG_ DisengageDiffLockRqFrontAxle1 : 24|2@1+ (1,0) [0|3] "" Vector__XXX
 SG_ DisengageDiffLockRqFrontAxle2 : 26|2@1+ (1,0) [0|3] "" Vector__XXX
 SG_ DisengageDiffLockRqRearAxle1 : 28|2@1+ (1,0) [0|3] "" Vector__XXX
 SG_ DisengageDiffLockRqRearAxle2 : 30|2@1+ (1,0) [0|3] "" Vector__XXX
 SG_ DisengageDiffLockRqCentral : 32|2@1+ (1,0) [0|3] "" Vector__XXX
 SG_ DisengageDiffLockRqCentralFront : 34|2@1+ (1,0) [0|3] "" Vector__XXX
 SG_ DisengageDiffLockRqCentralRear : 36|2@1+ (1,0) [0|3] "" Vector__XXX
 SG_ TransMode1 : 40|2@1+ (1,0) [0|3] "" Vector__XXX
 SG_ TransMode2 : 42|2@1+ (1,0) [0|3] "" Vector__XXX
 SG_ TransMode3 : 44|2@1+ (1,0) [0|3] "" Vector__XXX
 SG_ TransMode4 : 46|2@1+ (1,0) [0|3] "" Vector__XXX
 SG_ TransRequestedLaunchGear : 50|4@1+ (1,0) [0|15] "" Vector__XXX
 SG_ TrnsShftSlectorDisplayModeSwitch : 54|2@1+ (1,0) [0|3] "" Vector__XXX
 SG_ TransMode5 : 56|2@1+ (1,0) [0|3] "" Vector__XXX
 SG_ TransMode6 : 58|2@1+ (1,0) [0|3] "" Vector__XXX
 SG_ TransMode7 : 60|2@1+ (1,0) [0|3] "" Vector__XXX
 SG_ TransMode8 : 62|2@1+ (1,0) [0|3] "" Vector__XXX

BO_ 2349541911 AEBS2: 0 Vector__XXX

BO_ 2147484416 BMSReport: 8 VCU
 SG_ ACSetTemp : 24|8@1+ (1,0) [0|0] "" Vector__XXX
 SG_ AuxBatteryCurrent : 48|16@1+ (1,0) [0|0] "" Vector__XXX
 SG_ AuxBatteryVoltage : 32|16@1+ (1,0) [0|0] "" Vector__XXX
 SG_ AuxBatteryStateOfHealth : 16|8@1+ (1,0) [0|0] "" Vector__XXX
 SG_ AuxBatteryStateOfCharge : 8|8@1+ (1,0) [0|0] "" Vector__XXX
 SG_ BattTimeRemain : 0|8@1+ (1,0) [0|0] "hr" Vector__XXX

BO_ 2147553430 VCU_Version: 4 VCU
 SG_ truck_type : 24|8@1+ (1,0) [0|255] "" Vector__XXX
 SG_ patch_version : 16|8@1+ (1,0) [0|255] "" Vector__XXX
 SG_ feature_version : 8|8@1+ (1,0) [0|255] "" Vector__XXX
 SG_ VCU_version : 0|8@1+ (1,0) [0|255] "" Vector__XXX

BO_ 2566848839 BMS_StartBattPara: 4 Vector__XXX
 SG_ BMS_StartingBattVolt : 39|16@0+ (0.01,0) [0|0] "VDC" Vector__XXX
 SG_ BMS_SpearatorRelayStatus : 1|2@0+ (1,0) [0|0] "" Vector__XXX

BO_ 2566848583 BMS_AuxBattPara: 8 Vector__XXX
 SG_ BMS_AuxBattTemp : 55|16@0- (1,40) [0|0] "°C" Vector__XXX
 SG_ BMS_AuxBattVoltage : 39|16@0+ (0.01,0) [0|0] "VDC" Vector__XXX
 SG_ BMS_AuxBattCurrent : 7|32@0- (0.1,0) [0|0] "ADC" Vector__XXX

BO_ 2566849095 BMS_AlgorithmOutputs: 4 Vector__XXX
 SG_ BMS_StOfHealth : 31|8@0+ (1,0) [0|0] "%" Vector__XXX
 SG_ BMS_StOfCharge : 23|8@0+ (1,0) [0|0] "%" Vector__XXX
 SG_ BMS_TimeRemaining : 7|16@0+ (0.1,0) [0|0] "hr" Vector__XXX

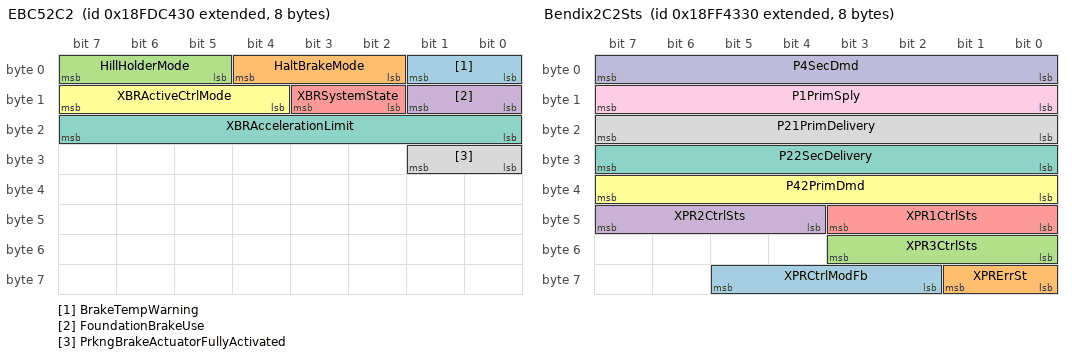
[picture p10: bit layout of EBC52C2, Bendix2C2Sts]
BO_ 2566767664 EBC52C2: 8 Vector__XXX
 SG_ BrakeTempWarning : 0|2@1+ (1,0) [0|3] "" Vector__XXX
 SG_ HaltBrakeMode : 2|3@1+ (1,0) [0|7] "" Vector__XXX
 SG_ HillHolderMode : 5|3@1+ (1,0) [0|7] "" Vector__XXX
 SG_ FoundationBrakeUse : 8|2@1+ (1,0) [0|3] "" Vector__XXX
 SG_ XBRSystemState : 10|2@1+ (1,0) [0|3] "" Vector__XXX
 SG_ XBRActiveCtrlMode : 12|4@1+ (1,0) [0|15] "" Vector__XXX
 SG_ XBRAccelerationLimit : 16|8@1+ (1,-12.5) [-12.5|12.5] "" Vector__XXX
 SG_ PrkngBrakeActuatorFullyActivated : 24|2@1+ (1,0) [0|3] "" Vector__XXX

BO_ 2565865776 EBC12C2: 8 Vector__XXX
 SG_ ASREngCtrlActive : 0|2@1+ (1,0) [0|3] "" Vector__XXX
 SG_ ASRBrakeCtrlActive : 2|2@1+ (1,0) [0|3] "" Vector__XXX
 SG_ AntiLockBrakingActive : 4|2@1+ (1,0) [0|3] "" Vector__XXX
 SG_ EBSBrakeSwitch : 6|2@1+ (1,0) [0|3] "" Vector__XXX
 SG_ BrakePedalPos : 8|8@1+ (0.4,0) [0|100] "%" Vector__XXX
 SG_ ABSOffroadSwitch : 16|2@1+ (1,0) [0|3] "" Vector__XXX
 SG_ ASROffroadSwitch : 18|2@1+ (1,0) [0|3] "" Vector__XXX
 SG_ ASRHillHolderSwitch : 20|2@1+ (1,0) [0|3] "" Vector__XXX
 SG_ TractionCtrlOverrideSwitch : 22|2@1+ (1,0) [0|3] "" Vector__XXX
 SG_ AccelInterlockSwitch : 24|2@1+ (1,0) [0|3] "" Vector__XXX
 SG_ EngDerateSwitch : 26|2@1+ (1,0) [0|3] "" Vector__XXX
 SG_ EngAuxShutdownSwitch : 28|2@1+ (1,0) [0|3] "" Vector__XXX
 SG_ RemoteAccelEnableSwitch : 30|2@1+ (1,0) [0|3] "" Vector__XXX
 SG_ EngRetarderSelection : 32|8@1+ (0.4,0) [0|100] "%" Vector__XXX
 SG_ ABSFullyOperational : 40|2@1+ (1,0) [0|3] "" Vector__XXX
 SG_ EBSRedWarningSignal : 42|2@1+ (1,0) [0|3] "" Vector__XXX
 SG_ ABS_EBSAmberWarningSignal : 44|2@1+ (1,0) [0|3] "" Vector__XXX
 SG_ ATC_ASRInformationSignal : 46|2@1+ (1,0) [0|3] "" Vector__XXX
 SG_ SrcAddrssOfCntrllngDvcFrBrkeCtrl : 48|8@1+ (1,0) [0|255] "" Vector__XXX
 SG_ HaltBrakeSwitch : 58|2@1+ (1,0) [0|3] "" Vector__XXX
 SG_ TrailerABSStatus : 60|2@1+ (1,0) [0|3] "" Vector__XXX
 SG_ TrctrMntdTrailerABSWarningSignal : 62|2@1+ (1,0) [0|3] "" Vector__XXX
 SG_ RailroadModeSwitch : 56|2@1+ (1,0) [0|3] "" Vector__XXX

BO_ 2565799728 HRW2C2: 8 Vector__XXX
 SG_ V_RR : 48|16@1+ (0.00390625,0) [0|65535] "km/h" Vector__XXX
 SG_ V_RL : 32|16@1+ (0.00390625,0) [0|65535] "km/h" Vector__XXX
 SG_ V_FR : 16|16@1+ (0.00390625,0) [0|65535] "km/h" Vector__XXX
 SG_ V_FL : 0|16@1+ (0.00390625,0) [0|65535] "km/h" Vector__XXX

BO_ 2566865712 Bendix2C2Sts: 8 Vector__XXX
 SG_ XPRCtrlModFb : 58|4@1+ (1,0) [0|15] "" Vector__XXX
 SG_ XPRErrSt : 56|2@1+ (1,0) [0|3] "" Vector__XXX
 SG_ XPR3CtrlSts : 48|4@1+ (1,0) [0|15] "" Vector__XXX
 SG_ XPR2CtrlSts : 44|4@1+ (1,0) [0|15] "" Vector__XXX
 SG_ XPR1CtrlSts : 40|4@1+ (1,0) [0|15] "" Vector__XXX
 SG_ P42PrimDmd : 32|8@1+ (80,0) [0|255] "mbar" Vector__XXX
 SG_ P22SecDelivery : 24|8@1+ (80,0) [0|255] "mbar" Vector__XXX
 SG_ P21PrimDelivery : 16|8@1+ (80,0) [0|255] "mbar" Vector__XXX
 SG_ P1PrimSply : 8|8@1+ (80,0) [0|255] "mbar" Vector__XXX
 SG_ P4SecDmd : 0|8@1+ (80,0) [0|255] "mbar"  VCU

BO_ 2365543992 XPRCmd: 8 VCU
 SG_ MessageChecksum : 60|4@1+ (1,0) [0|15] "" Vector__XXX
 SG_ MessageCounter : 56|4@1+ (1,0) [0|15] "" Vector__XXX
 SG_ XPRPrio : 10|2@1+ (1,0) [0|3] "" Vector__XXX
 SG_ XPRPReq : 0|8@1+ (0.4,0) [0|255] "%" Vector__XXX
 SG_ XPRPRedt : 16|8@1+ (0.4,0) [0|255] "%" Vector__XXX
 SG_ XPRCtrlMod : 8|2@1+ (1,0) [0|3] "" Vector__XXX

BO_ 2566863418 AC_ControlMainCommand: 8 Vector__XXX
 SG_ ACFanSpeed : 40|8@1- (1,0) [0|0] "" Vector__XXX
 SG_ ACTemperatureSetting : 32|8@1- (1,0) [0|0] "" Vector__XXX
 SG_ ACTemperature : 55|16@0+ (0.11,-28.919) [0|0] "" Vector__XXX
 SG_ ACOperatingMode : 8|2@1- (1,0) [0|0] "" Vector__XXX

BO_ 2566864196 AC_Control: 8 Vector__XXX
 SG_ AC_HeaterOption : 11|2@0+ (1,0) [0|0] "" Vector__XXX
 SG_ AC_ControlMode : 9|2@0+ (1,0) [0|0] "" Vector__XXX
 SG_ AC_CompressorSpd : 63|8@0+ (1,0) [0|0] "" Vector__XXX
 SG_ AC_RelayOutput : 7|8@0+ (1,0) [0|0] "" Vector__XXX

BO_ 2147488544 VCU_Test2MSG: 8 VCU
 SG_ Test2XPRPTar : 24|8@1+ (0.4,0) [0|255] "%" Vector__XXX
 SG_ Test2GearTar : 16|8@1+ (1,-125) [-125|125] "" Vector__XXX
 SG_ Test2EngBrkPercTar : 8|8@1+ (1,-125) [-125|125] "%" Vector__XXX
 SG_ Test2P7EngTqPercTar : 0|8@1+ (1,-125) [-125|125] "%" Vector__XXX

BO_ 2147553431 ACC_Switches: 6 Vector__XXX
 SG_ CCVS_ReadErr : 24|16@1+ (1,0) [0|0] "" Vector__XXX
 SG_ Ord_THTCmd : 16|8@1+ (1,0) [0|255] "" Vector__XXX
 SG_ Ord_THTPos : 8|8@1+ (1,0) [0|255] "" Vector__XXX
 SG_ Cancel : 6|2@1+ (1,0) [0|3] "" Vector__XXX
 SG_ Resume : 4|2@1+ (1,0) [0|3] "" Vector__XXX
 SG_ Set : 2|2@1+ (1,0) [0|3] "" Vector__XXX
 SG_ OnOff : 0|2@1+ (1,0) [0|3] "" Vector__XXX

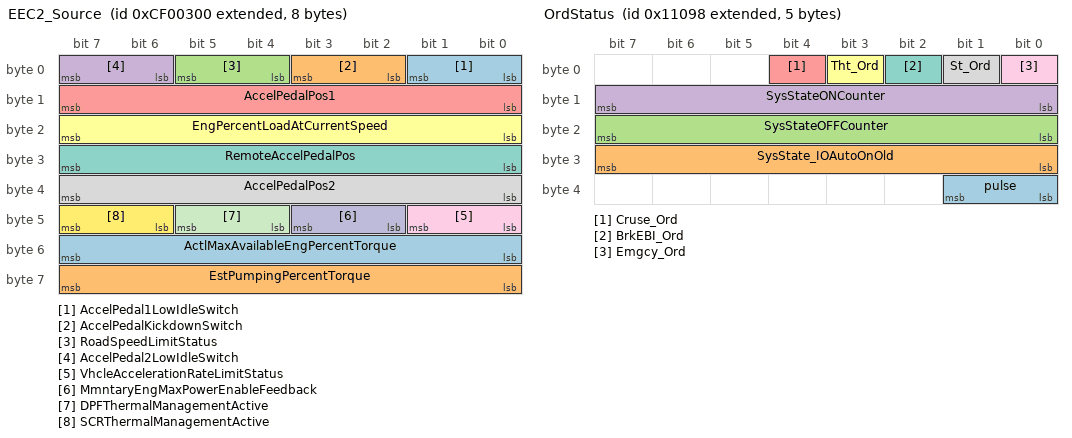
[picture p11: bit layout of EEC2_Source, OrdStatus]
BO_ 2364539648 EEC2_Source: 8 Vector__XXX
 SG_ AccelPedal1LowIdleSwitch : 0|2@1+ (1,0) [0|3] "" Vector__XXX
 SG_ AccelPedalKickdownSwitch : 2|2@1+ (1,0) [0|3] "" Vector__XXX
 SG_ RoadSpeedLimitStatus : 4|2@1+ (1,0) [0|3] "" Vector__XXX
 SG_ AccelPedal2LowIdleSwitch : 6|2@1+ (1,0) [0|3] "" Vector__XXX
 SG_ AccelPedalPos1 : 8|8@1+ (0.4,0) [0|100] "%" Vector__XXX
 SG_ EngPercentLoadAtCurrentSpeed : 16|8@1+ (1,0) [0|250] "%" Vector__XXX
 SG_ RemoteAccelPedalPos : 24|8@1+ (0.4,0) [0|100] "%" Vector__XXX
 SG_ AccelPedalPos2 : 32|8@1+ (0.4,0) [0|100] "%" Vector__XXX
 SG_ VhcleAccelerationRateLimitStatus : 40|2@1+ (1,0) [0|3] "" Vector__XXX
 SG_ MmntaryEngMaxPowerEnableFeedback : 42|2@1+ (1,0) [0|3] "" Vector__XXX
 SG_ DPFThermalManagementActive : 44|2@1+ (1,0) [0|3] "" Vector__XXX
 SG_ SCRThermalManagementActive : 46|2@1+ (1,0) [0|3] "" Vector__XXX
 SG_ ActlMaxAvailableEngPercentTorque : 48|8@1+ (0.4,0) [0|100] "%" Vector__XXX
 SG_ EstPumpingPercentTorque : 56|8@1+ (1,-125) [-125|125] "%"  VCU

BO_ 2147553432 OrdStatus: 5 VCU
 SG_ pulse : 32|2@1+ (1,0) [0|0] "" Vector__XXX
 SG_ SysState_IOAutoOnOld : 24|8@1+ (1,0) [0|255] "" Vector__XXX
 SG_ SysStateOFFCounter : 16|8@1+ (1,0) [0|255] "" Vector__XXX
 SG_ SysStateONCounter : 8|8@1+ (1,0) [0|255] "" Vector__XXX
 SG_ Cruse_Ord : 4|1@1+ (1,0) [0|1] "" Vector__XXX
 SG_ Tht_Ord : 3|1@1+ (1,0) [0|1] "" Vector__XXX
 SG_ BrkEBI_Ord : 2|1@1+ (1,0) [0|1] "" Vector__XXX
 SG_ St_Ord : 1|1@1+ (1,0) [0|1] "" Vector__XXX
 SG_ Emgcy_Ord : 0|1@1+ (1,0) [0|1] "" Vector__XXX

BO_ 2566745600 A1SCRSI1: 8 Vector__XXX
 SG_ Aftrtrtmnt1SCRSysSulfationLevl : 56|8@1+ (1,0) [0|250] "%" Vector__XXX
 SG_ AftrtrtmentSCRInduceActTrvlDist : 40|16@1+ (1,0) [0|64255] "km" Vector__XXX
 SG_ Aftrtrtment1SCRConversionEff : 32|8@1+ (0.4,0) [0|100] "%" Vector__XXX
 SG_ Aftrtrtmnt1SCRCmdExhstAvgCnsmp : 16|16@1+ (0.05,0) [0|3212.75] "L/h" Vector__XXX
 SG_ Aftrtrtmnt1ExhstFluidAvgCnsmp : 0|16@1+ (0.05,0) [0|3212.75] "L/h" Vector__XXX

BO_ 2566771968 EEC5_00: 8 Vector__XXX
 SG_ EngTrb1ClclatedTurbineOutletTemp : 16|16@1+ (0.03125,-273) [-273|1734.96875] "deg C" Vector__XXX
 SG_ EngVrblGmtryTrbArCtrlShtoffValve : 48|2@1+ (1,0) [0|3] "" Vector__XXX
 SG_ EngVrblGeometryTurbo1ActuatorPos : 56|8@1+ (0.4,0) [0|100] "%" Vector__XXX
 SG_ EngExhstGsRcirculation1ValveCtrl : 32|16@1+ (0.0025,0) [0|160.8375] "%" Vector__XXX
 SG_ EngTrb1ClclatedTurbineIntakeTemp : 0|16@1+ (0.03125,-273) [-273|1734.96875] "deg C" Vector__XXX
 SG_ EngVriableGeometryTurbo1CtrlMode : 52|2@1+ (1,0) [0|3] "" Vector__XXX

BO_ 2566764544 DM26_00: 8 Vector__XXX
 SG_ TimeSinceEngineStart : 0|16@1+ (1,0) [0|64255] "sec" Vector__XXX
 SG_ NumOfWarmUpsSinceDTCsCleared : 16|8@1+ (1,0) [0|250] "" Vector__XXX
 SG_ FuelSystemMonitoringComplete : 29|1@1- (1,0) [0|1] "" Vector__XXX
 SG_ ACSystemRefrigerantMonEnabled : 36|1@1- (1,0) [0|1] "" Vector__XXX
 SG_ ACSystemRefrigerantMonComplete : 52|1@1- (1,0) [0|1] "" Vector__XXX
 SG_ CatalystMonEnabled : 32|1@1- (1,0) [0|1] "" Vector__XXX
 SG_ CatalystMonComplete : 48|1@1- (1,0) [0|1] "" Vector__XXX
 SG_ ColdStartAidSystemMonEnabled : 40|1@1- (1,0) [0|1] "" Vector__XXX
 SG_ ColdStartAidSystemMonComplete : 56|1@1- (1,0) [0|1] "" Vector__XXX
 SG_ EGRSystemMonitoringEnabled : 39|1@1- (1,0) [0|1] "" Vector__XXX
 SG_ EGRSystemMonitoringComplete : 55|1@1- (1,0) [0|1] "" Vector__XXX
 SG_ EvaporativeSystemMonEnabled : 34|1@1- (1,0) [0|1] "" Vector__XXX
 SG_ EvaporativeSystemMonComplete : 50|1@1- (1,0) [0|1] "" Vector__XXX
 SG_ HeatedCatalystMonEnabled : 33|1@1- (1,0) [0|1] "" Vector__XXX
 SG_ HeatedCatalystMonComplete : 49|1@1- (1,0) [0|1] "" Vector__XXX
 SG_ OxygenSensorHeaterMonEnabled : 38|1@1- (1,0) [0|1] "" Vector__XXX
 SG_ OxygenSensorHeaterMonComplete : 54|1@1- (1,0) [0|1] "" Vector__XXX
 SG_ OxygenSensorMonEnabled : 37|1@1- (1,0) [0|1] "" Vector__XXX
 SG_ OxygenSensorMonComplete : 53|1@1- (1,0) [0|1] "" Vector__XXX
 SG_ SecondAirSystemMonEnabled : 35|1@1- (1,0) [0|1] "" Vector__XXX
 SG_ SecondAirSystemMonComplete : 51|1@1- (1,0) [0|1] "" Vector__XXX
 SG_ ComprehensiveCompMonEnabled : 26|1@1- (1,0) [0|1] "" Vector__XXX
 SG_ ComprehensiveComptMonComplete : 30|1@1- (1,0) [0|1] "" Vector__XXX
 SG_ FuelSystemMonitoringEnabled : 25|1@1- (1,0) [0|1] "" Vector__XXX
 SG_ MisfireMonitoringEnabled : 24|1@1- (1,0) [0|1] "" Vector__XXX
 SG_ MisfireMonitoringComplete : 28|1@1- (1,0) [0|1] "" Vector__XXX
 SG_ BoostPressureControlSystemEnable : 41|1@1- (1,0) [0|1] "" Vector__XXX
 SG_ BoostPressureControlSystemComple : 57|1@1- (1,0) [0|1] "" Vector__XXX
 SG_ DieselParticulateFilterEnabled : 42|1@1- (1,0) [0|1] "" Vector__XXX
 SG_ DieselParticulateFilterCompleted : 58|1@1- (1,0) [0|1] "" Vector__XXX
 SG_ NOxConvertingCatalystAdsorberEna : 43|1@1- (1,0) [0|1] "" Vector__XXX
 SG_ NOxConvertingCatalystAdsorberCom : 59|1@1- (1,0) [0|1] "" Vector__XXX
 SG_ NMHCConvertingCatalystEnabled : 44|1@1- (1,0) [0|1] "" Vector__XXX
 SG_ NMHCConvertingCatalystCompleted : 60|1@1- (1,0) [0|1] "" Vector__XXX

BO_ 2633937152 EH_00: 8 Vector__XXX
 SG_ TotalECUDistance : 0|32@1+ (0.125,0) [0|526385000] "km" Vector__XXX
 SG_ TotalECURunTime : 32|32@1+ (0.05,0) [0|210554000] "hr" Vector__XXX

BO_ 2565537785 RQST_FFF9: 3 Vector__XXX
 SG_ ParameterGroupNumber : 0|24@1+ (1,0) [0|16777200] "" Vector__XXX

BO_ 2565406467 ACKM_03: 8 Vector__XXX
 SG_ AddressAcknowledged : 32|8@1+ (1,0) [0|255] "" Vector__XXX
 SG_ AddressNegativeAcknowledgement : 32|8@1+ (1,0) [0|255] "" Vector__XXX
 SG_ AddressAccessDenied : 32|8@1+ (1,0) [0|255] "" Vector__XXX
 SG_ GroupFunctionValue : 8|8@1+ (1,0) [0|255] "" Vector__XXX
 SG_ ParameterGroupNumber : 40|24@1+ (1,0) [0|16777200] "" Vector__XXX
 SG_ ControlByte : 0|8@1+ (1,0) [0|255] "" Vector__XXX
 SG_ AddressBusy : 32|8@1+ (1,0) [0|255] "" Vector__XXX

BO_ 2565473273 RQST_03F9: 3 Vector__XXX
 SG_ ParameterGroupNumber : 0|24@1+ (1,0) [0|16777200] "" Vector__XXX

BO_ 2566852906 PropB_11: 8 Vector__XXX

BO_ 2632712076 TPDT_8C: 8 Vector__XXX
 SG_ SequenceNumber : 0|8@1+ (1,0) [0|255] "" Vector__XXX

BO_ 2632712168 TPDT_E8: 8 Vector__XXX
 SG_ SequenceNumber : 0|8@1+ (1,0) [0|255] "" Vector__XXX

BO_ 2632711947 TPDT_0B: 8 Vector__XXX
 SG_ SequenceNumber : 0|8@1+ (1,0) [0|255] "" Vector__XXX

BO_ 2565603114 TPDT_2A: 8 Vector__XXX
 SG_ SequenceNumber : 0|8@1+ (1,0) [0|255] "" Vector__XXX

BO_ 2632711939 TPDT_03: 8 Vector__XXX
 SG_ SequenceNumber : 0|8@1+ (1,0) [0|255] "" Vector__XXX

BO_ 2632712145 TPDT_D1: 8 Vector__XXX
 SG_ SequenceNumber : 0|8@1+ (1,0) [0|255] "" Vector__XXX

BO_ 2632711955 TPDT_13: 8 Vector__XXX
 SG_ SequenceNumber : 0|8@1+ (1,0) [0|255] "" Vector__XXX

BO_ 2632777475 TPCM_FF03: 8 Vector__XXX
 SG_ ControlByte : 0|8@1+ (1,0) [0|255] "" Vector__XXX
 SG_ TotalMessageSize : 8|16@1+ (1,0) [0|64255] "counts" Vector__XXX
 SG_ TotalNumberOfPackets : 24|8@1+ (1,0) [0|255] "" Vector__XXX
 SG_ MaximumNumberOfPackets : 32|8@1+ (1,0) [0|255] "" Vector__XXX
 SG_ PGNumber : 40|24@1+ (1,0) [0|16777200] "" Vector__XXX
 SG_ NumberOfPacketsThatCanBeSent : 8|8@1+ (1,0) [0|255] "" Vector__XXX
 SG_ NextPacketNumberToBeSent : 16|8@1+ (1,0) [0|255] "" Vector__XXX
 SG_ ConnectionAbortReason : 8|8@1+ (1,0) [0|255] "" Vector__XXX
 SG_ TotalNumberOfPacketsBAM : 24|8@1+ (1,0) [0|255] "" Vector__XXX
 SG_ TotalMessageSizeBAM : 8|16@1+ (1,0) [0|64255] "counts" Vector__XXX
 SG_ TotalMessageSizeEoMA : 8|16@1+ (1,0) [0|64255] "counts" Vector__XXX
 SG_ TotalNumberOfPacketsEoMA : 24|8@1+ (1,0) [0|255] "" Vector__XXX

BO_ 2632777612 TPCM_8C: 8 Vector__XXX
 SG_ ControlByte : 0|8@1+ (1,0) [0|255] "" Vector__XXX
 SG_ TotalMessageSize : 8|16@1+ (1,0) [0|64255] "counts" Vector__XXX
 SG_ TotalNumberOfPackets : 24|8@1+ (1,0) [0|255] "" Vector__XXX
 SG_ MaximumNumberOfPackets : 32|8@1+ (1,0) [0|255] "" Vector__XXX
 SG_ PGNumber : 40|24@1+ (1,0) [0|16777200] "" Vector__XXX
 SG_ NumberOfPacketsThatCanBeSent : 8|8@1+ (1,0) [0|255] "" Vector__XXX
 SG_ NextPacketNumberToBeSent : 16|8@1+ (1,0) [0|255] "" Vector__XXX
 SG_ ConnectionAbortReason : 8|8@1+ (1,0) [0|255] "" Vector__XXX
 SG_ TotalNumberOfPacketsBAM : 24|8@1+ (1,0) [0|255] "" Vector__XXX
 SG_ TotalMessageSizeBAM : 8|16@1+ (1,0) [0|64255] "counts" Vector__XXX
 SG_ TotalMessageSizeEoMA : 8|16@1+ (1,0) [0|64255] "counts" Vector__XXX
 SG_ TotalNumberOfPacketsEoMA : 24|8@1+ (1,0) [0|255] "" Vector__XXX

BO_ 2632777483 TPCM_0B: 8 Vector__XXX
 SG_ ControlByte : 0|8@1+ (1,0) [0|255] "" Vector__XXX
 SG_ TotalMessageSize : 8|16@1+ (1,0) [0|64255] "counts" Vector__XXX
 SG_ TotalNumberOfPackets : 24|8@1+ (1,0) [0|255] "" Vector__XXX
 SG_ MaximumNumberOfPackets : 32|8@1+ (1,0) [0|255] "" Vector__XXX
 SG_ PGNumber : 40|24@1+ (1,0) [0|16777200] "" Vector__XXX
 SG_ NumberOfPacketsThatCanBeSent : 8|8@1+ (1,0) [0|255] "" Vector__XXX
 SG_ NextPacketNumberToBeSent : 16|8@1+ (1,0) [0|255] "" Vector__XXX
 SG_ ConnectionAbortReason : 8|8@1+ (1,0) [0|255] "" Vector__XXX
 SG_ TotalNumberOfPacketsBAM : 24|8@1+ (1,0) [0|255] "" Vector__XXX
 SG_ TotalMessageSizeBAM : 8|16@1+ (1,0) [0|64255] "counts" Vector__XXX
 SG_ TotalMessageSizeEoMA : 8|16@1+ (1,0) [0|64255] "counts" Vector__XXX
 SG_ TotalNumberOfPacketsEoMA : 24|8@1+ (1,0) [0|255] "" Vector__XXX

BO_ 2632777704 TPCM_E8: 8 Vector__XXX
 SG_ ControlByte : 0|8@1+ (1,0) [0|255] "" Vector__XXX
 SG_ TotalMessageSize : 8|16@1+ (1,0) [0|64255] "counts" Vector__XXX
 SG_ TotalNumberOfPackets : 24|8@1+ (1,0) [0|255] "" Vector__XXX
 SG_ MaximumNumberOfPackets : 32|8@1+ (1,0) [0|255] "" Vector__XXX
 SG_ PGNumber : 40|24@1+ (1,0) [0|16777200] "" Vector__XXX
 SG_ NumberOfPacketsThatCanBeSent : 8|8@1+ (1,0) [0|255] "" Vector__XXX
 SG_ NextPacketNumberToBeSent : 16|8@1+ (1,0) [0|255] "" Vector__XXX
 SG_ ConnectionAbortReason : 8|8@1+ (1,0) [0|255] "" Vector__XXX
 SG_ TotalNumberOfPacketsBAM : 24|8@1+ (1,0) [0|255] "" Vector__XXX
 SG_ TotalMessageSizeBAM : 8|16@1+ (1,0) [0|64255] "counts" Vector__XXX
 SG_ TotalMessageSizeEoMA : 8|16@1+ (1,0) [0|64255] "counts" Vector__XXX
 SG_ TotalNumberOfPacketsEoMA : 24|8@1+ (1,0) [0|255] "" Vector__XXX

BO_ 2632777491 TPCM_13: 8 Vector__XXX
 SG_ ControlByte : 0|8@1+ (1,0) [0|255] "" Vector__XXX
 SG_ TotalMessageSize : 8|16@1+ (1,0) [0|64255] "counts" Vector__XXX
 SG_ TotalNumberOfPackets : 24|8@1+ (1,0) [0|255] "" Vector__XXX
 SG_ MaximumNumberOfPackets : 32|8@1+ (1,0) [0|255] "" Vector__XXX
 SG_ PGNumber : 40|24@1+ (1,0) [0|16777200] "" Vector__XXX
 SG_ NumberOfPacketsThatCanBeSent : 8|8@1+ (1,0) [0|255] "" Vector__XXX
 SG_ NextPacketNumberToBeSent : 16|8@1+ (1,0) [0|255] "" Vector__XXX
 SG_ ConnectionAbortReason : 8|8@1+ (1,0) [0|255] "" Vector__XXX
 SG_ TotalNumberOfPacketsBAM : 24|8@1+ (1,0) [0|255] "" Vector__XXX
 SG_ TotalMessageSizeBAM : 8|16@1+ (1,0) [0|64255] "counts" Vector__XXX
 SG_ TotalMessageSizeEoMA : 8|16@1+ (1,0) [0|64255] "counts" Vector__XXX
 SG_ TotalNumberOfPacketsEoMA : 24|8@1+ (1,0) [0|255] "" Vector__XXX

BO_ 2565668650 TPCM_2A: 8 Vector__XXX
 SG_ ControlByte : 0|8@1+ (1,0) [0|255] "" Vector__XXX
 SG_ TotalMessageSize : 8|16@1+ (1,0) [0|64255] "counts" Vector__XXX
 SG_ TotalNumberOfPackets : 24|8@1+ (1,0) [0|255] "" Vector__XXX
 SG_ MaximumNumberOfPackets : 32|8@1+ (1,0) [0|255] "" Vector__XXX
 SG_ PGNumber : 40|24@1+ (1,0) [0|16777200] "" Vector__XXX
 SG_ NumberOfPacketsThatCanBeSent : 8|8@1+ (1,0) [0|255] "" Vector__XXX
 SG_ NextPacketNumberToBeSent : 16|8@1+ (1,0) [0|255] "" Vector__XXX
 SG_ ConnectionAbortReason : 8|8@1+ (1,0) [0|255] "" Vector__XXX
 SG_ TotalNumberOfPacketsBAM : 24|8@1+ (1,0) [0|255] "" Vector__XXX
 SG_ TotalMessageSizeBAM : 8|16@1+ (1,0) [0|64255] "counts" Vector__XXX
 SG_ TotalMessageSizeEoMA : 8|16@1+ (1,0) [0|64255] "counts" Vector__XXX
 SG_ TotalNumberOfPacketsEoMA : 24|8@1+ (1,0) [0|255] "" Vector__XXX

BO_ 2565472505 RQST_F9: 3 Vector__XXX
 SG_ ParameterGroupNumber : 0|24@1+ (1,0) [0|16777200] "" Vector__XXX

BO_ 2348876555 TC1_Shifter_0B: 8 Vector__XXX
 SG_ TransGearShiftInhibitRq : 0|2@1+ (1,0) [0|3] "" Vector__XXX
 SG_ TrnsTrqeConverterLockupDisableRq : 2|2@1+ (1,0) [0|3] "" Vector__XXX
 SG_ DisengageDrivelineRq : 4|2@1+ (1,0) [0|3] "" Vector__XXX
 SG_ TransReverseGearShiftInhibitRq : 6|2@1+ (1,0) [0|3] "" Vector__XXX
 SG_ RequestedPercentClutchSlip : 8|8@1+ (1,0) [0|100] "%" Vector__XXX
 SG_ TransRequestedGear : 16|8@1+ (1,-125) [-125|125] "" Vector__XXX
 SG_ DisengageDiffLockRqFrontAxle1 : 24|2@1+ (1,0) [0|3] "" Vector__XXX
 SG_ DisengageDiffLockRqFrontAxle2 : 26|2@1+ (1,0) [0|3] "" Vector__XXX
 SG_ DisengageDiffLockRqRearAxle1 : 28|2@1+ (1,0) [0|3] "" Vector__XXX
 SG_ DisengageDiffLockRqRearAxle2 : 30|2@1+ (1,0) [0|3] "" Vector__XXX
 SG_ DisengageDiffLockRqCentral : 32|2@1+ (1,0) [0|3] "" Vector__XXX
 SG_ DisengageDiffLockRqCentralFront : 34|2@1+ (1,0) [0|3] "" Vector__XXX
 SG_ DisengageDiffLockRqCentralRear : 36|2@1+ (1,0) [0|3] "" Vector__XXX
 SG_ TransMode1 : 40|2@1+ (1,0) [0|3] "" Vector__XXX
 SG_ TransMode2 : 42|2@1+ (1,0) [0|3] "" Vector__XXX
 SG_ TransMode3 : 44|2@1+ (1,0) [0|3] "" Vector__XXX
 SG_ TransMode4 : 46|2@1+ (1,0) [0|3] "" Vector__XXX
 SG_ TransRequestedLaunchGear : 50|4@1+ (1,0) [0|15] "" Vector__XXX
 SG_ TrnsShftSlectorDisplayModeSwitch : 54|2@1+ (1,0) [0|3] "" Vector__XXX
 SG_ TransMode5 : 56|2@1+ (1,0) [0|3] "" Vector__XXX
 SG_ TransMode6 : 58|2@1+ (1,0) [0|3] "" Vector__XXX
 SG_ TransMode7 : 60|2@1+ (1,0) [0|3] "" Vector__XXX
 SG_ TransMode8 : 62|2@1+ (1,0) [0|3] "" Vector__XXX

BO_ 2565537578 RQST_FF2A: 3 Vector__XXX
 SG_ ParameterGroupNumber : 0|24@1+ (1,0) [0|16777200] "" Vector__XXX

BO_ 2566850611 PropB_08: 8 Vector__XXX

BO_ 2566856936 PropB_20: 8 Vector__XXX

BO_ 2566849331 PropB_03: 8 Vector__XXX

BO_ 2566857356 PropB_22: 8 Vector__XXX

BO_ 2565475114 RQST_2A: 3 Vector__XXX
 SG_ ParameterGroupNumber : 0|24@1+ (1,0) [0|16777200] "" Vector__XXX

BO_ 2633937664 LFI1: 7 Vector__XXX
 SG_ FlexibleFuelPrct : 48|16@1+ (0.0025,0) [0|160.6375] "%" Vector__XXX
 SG_ TripAvgFuelRate : 32|16@1+ (0.05,0) [0|3212.75] "L/h" Vector__XXX
 SG_ TotalEngPTOFuelUsed : 0|32@1+ (0.5,0) [0|2105540607.5] "L" Vector__XXX

BO_ 2566848256 OI: 4 Vector__XXX
 SG_ FuelEstRemainDis : 24|16@1+ (1,0) [0|64255] "km" Vector__XXX
 SG_ WaterInChrgAirDuct : 16|2@1+ (1,0) [0|3] "" Vector__XXX
 SG_ EmiCtrlSysOperateInduceSeverity : 11|3@1+ (1,0) [0|7] "%" Vector__XXX
 SG_ DriverWarnSysIndicatorStat : 8|3@1+ (1,0) [0|7] "%" Vector__XXX
 SG_ EngOvrloadedIndicator : 6|2@1+ (1,0) [0|3] "%" Vector__XXX
 SG_ WaterInFuelIndicator2 : 4|2@1+ (1,0) [0|3] "%" Vector__XXX
 SG_ OperatorShiftPrompt : 2|2@1+ (1,0) [0|3] "%" Vector__XXX
 SG_ WaterInFuelIndicator1 : 0|2@1+ (1,0) [0|3] "%" Vector__XXX

BO_ 2565537768 RQST_E8: 3 Vector__XXX
 SG_ ParameterGroupNumber : 0|24@1+ (1,0) [0|16777200] "" Vector__XXX

BO_ 2565537547 RQST_0B: 3 Vector__XXX
 SG_ ParameterGroupNumber : 0|24@1+ (1,0) [0|16777200] "" Vector__XXX

BO_ 2566912494 PropB_F9: 8 Vector__XXX

BO_ 2566909752 PropB_EF: 8 Vector__XXX

BO_ 2632777681 TPCM_D1: 8 Vector__XXX
 SG_ ControlByte : 0|8@1+ (1,0) [0|255] "" Vector__XXX
 SG_ TotalMessageSize : 8|16@1+ (1,0) [0|64255] "counts" Vector__XXX
 SG_ TotalNumberOfPackets : 24|8@1+ (1,0) [0|255] "" Vector__XXX
 SG_ MaximumNumberOfPackets : 32|8@1+ (1,0) [0|255] "" Vector__XXX
 SG_ PGNumber : 40|24@1+ (1,0) [0|16777200] "" Vector__XXX
 SG_ NumberOfPacketsThatCanBeSent : 8|8@1+ (1,0) [0|255] "" Vector__XXX
 SG_ NextPacketNumberToBeSent : 16|8@1+ (1,0) [0|255] "" Vector__XXX
 SG_ ConnectionAbortReason : 8|8@1+ (1,0) [0|255] "" Vector__XXX
 SG_ TotalNumberOfPacketsBAM : 24|8@1+ (1,0) [0|255] "" Vector__XXX
 SG_ TotalMessageSizeBAM : 8|16@1+ (1,0) [0|64255] "counts" Vector__XXX
 SG_ TotalMessageSizeEoMA : 8|16@1+ (1,0) [0|64255] "counts" Vector__XXX
 SG_ TotalNumberOfPacketsEoMA : 24|8@1+ (1,0) [0|255] "" Vector__XXX

BO_ 2632712195 TPCM_03: 8 Vector__XXX
 SG_ ControlByte : 0|8@1+ (1,0) [0|255] "" Vector__XXX
 SG_ TotalMessageSize : 8|16@1+ (1,0) [0|64255] "counts" Vector__XXX
 SG_ TotalNumberOfPackets : 24|8@1+ (1,0) [0|255] "" Vector__XXX
 SG_ MaximumNumberOfPackets : 32|8@1+ (1,0) [0|255] "" Vector__XXX
 SG_ PGNumber : 40|24@1+ (1,0) [0|16777200] "" Vector__XXX
 SG_ NumberOfPacketsThatCanBeSent : 8|8@1+ (1,0) [0|255] "" Vector__XXX
 SG_ NextPacketNumberToBeSent : 16|8@1+ (1,0) [0|255] "" Vector__XXX
 SG_ ConnectionAbortReason : 8|8@1+ (1,0) [0|255] "" Vector__XXX
 SG_ TotalNumberOfPacketsBAM : 24|8@1+ (1,0) [0|255] "" Vector__XXX
 SG_ TotalMessageSizeBAM : 8|16@1+ (1,0) [0|64255] "counts" Vector__XXX
 SG_ TotalMessageSizeEoMA : 8|16@1+ (1,0) [0|64255] "counts" Vector__XXX
 SG_ TotalNumberOfPacketsEoMA : 24|8@1+ (1,0) [0|255] "" Vector__XXX

BO_ 2632777472 TPCM_00: 8 Vector__XXX
 SG_ ControlByte : 0|8@1+ (1,0) [0|255] "" Vector__XXX
 SG_ TotalMessageSize : 8|16@1+ (1,0) [0|64255] "counts" Vector__XXX
 SG_ TotalNumberOfPackets : 24|8@1+ (1,0) [0|255] "" Vector__XXX
 SG_ MaximumNumberOfPackets : 32|8@1+ (1,0) [0|255] "" Vector__XXX
 SG_ PGNumber : 40|24@1+ (1,0) [0|16777200] "" Vector__XXX
 SG_ NumberOfPacketsThatCanBeSent : 8|8@1+ (1,0) [0|255] "" Vector__XXX
 SG_ NextPacketNumberToBeSent : 16|8@1+ (1,0) [0|255] "" Vector__XXX
 SG_ ConnectionAbortReason : 8|8@1+ (1,0) [0|255] "" Vector__XXX
 SG_ TotalNumberOfPacketsBAM : 24|8@1+ (1,0) [0|255] "" Vector__XXX
 SG_ TotalMessageSizeBAM : 8|16@1+ (1,0) [0|64255] "counts" Vector__XXX
 SG_ TotalMessageSizeEoMA : 8|16@1+ (1,0) [0|64255] "counts" Vector__XXX
 SG_ TotalNumberOfPacketsEoMA : 24|8@1+ (1,0) [0|255] "" Vector__XXX

BO_ 2564371249 DM14_3331: 8 Vector__XXX
 SG_ NumberRequestedHigh : 13|3@1+ (1,0) [0|7] "" Vector__XXX
 SG_ NumberRequested : 0|8@1+ (1,0) [0|255] "" Vector__XXX
 SG_ PointerType : 12|1@1- (1,0) [0|1] "" Vector__XXX
 SG_ Command : 9|3@1+ (1,0) [0|7] "" Vector__XXX
 SG_ Pointer : 16|24@1+ (1,0) [0|16777200] "" Vector__XXX
 SG_ PointerExtension : 40|8@1+ (1,0) [0|255] "" Vector__XXX
 SG_ KeyOrUserLevel : 48|16@1+ (1,0) [0|65535] "" Vector__XXX

BO_ 2565859339 PropA_0B: 8 Vector__XXX

BO_ 2565537585 RQST_31: 3 Vector__XXX
 SG_ ParameterGroupNumber : 0|24@1+ (1,0) [0|16777200] "" Vector__XXX

BO_ 2632711951 TPDT_0F: 8 Vector__XXX
 SG_ SequenceNumber : 0|8@1+ (1,0) [0|255] "" Vector__XXX

BO_ 2632777487 TPCM_0F: 8 Vector__XXX
 SG_ ControlByte : 0|8@1+ (1,0) [0|255] "" Vector__XXX
 SG_ TotalMessageSize : 8|16@1+ (1,0) [0|64255] "counts" Vector__XXX
 SG_ TotalNumberOfPackets : 24|8@1+ (1,0) [0|255] "" Vector__XXX
 SG_ MaximumNumberOfPackets : 32|8@1+ (1,0) [0|255] "" Vector__XXX
 SG_ PGNumber : 40|24@1+ (1,0) [0|16777200] "" Vector__XXX
 SG_ NumberOfPacketsThatCanBeSent : 8|8@1+ (1,0) [0|255] "" Vector__XXX
 SG_ NextPacketNumberToBeSent : 16|8@1+ (1,0) [0|255] "" Vector__XXX
 SG_ ConnectionAbortReason : 8|8@1+ (1,0) [0|255] "" Vector__XXX
 SG_ TotalNumberOfPacketsBAM : 24|8@1+ (1,0) [0|255] "" Vector__XXX
 SG_ TotalMessageSizeBAM : 8|16@1+ (1,0) [0|64255] "counts" Vector__XXX
 SG_ TotalMessageSizeEoMA : 8|16@1+ (1,0) [0|64255] "counts" Vector__XXX
 SG_ TotalNumberOfPacketsEoMA : 24|8@1+ (1,0) [0|255] "" Vector__XXX

BO_ 2565475121 RQST_0B31: 3 Vector__XXX
 SG_ ParameterGroupNumber : 0|24@1+ (1,0) [0|16777200] "" Vector__XXX

BO_ 2632711985 TPDT_31: 8 Vector__XXX
 SG_ SequenceNumber : 0|8@1+ (1,0) [0|255] "" Vector__XXX

BO_ 2632777521 TPCM_31: 8 Vector__XXX
 SG_ ControlByte : 0|8@1+ (1,0) [0|255] "" Vector__XXX
 SG_ TotalMessageSize : 8|16@1+ (1,0) [0|64255] "counts" Vector__XXX
 SG_ TotalNumberOfPackets : 24|8@1+ (1,0) [0|255] "" Vector__XXX
 SG_ MaximumNumberOfPackets : 32|8@1+ (1,0) [0|255] "" Vector__XXX
 SG_ PGNumber : 40|24@1+ (1,0) [0|16777200] "" Vector__XXX
 SG_ NumberOfPacketsThatCanBeSent : 8|8@1+ (1,0) [0|255] "" Vector__XXX
 SG_ NextPacketNumberToBeSent : 16|8@1+ (1,0) [0|255] "" Vector__XXX
 SG_ ConnectionAbortReason : 8|8@1+ (1,0) [0|255] "" Vector__XXX
 SG_ TotalNumberOfPacketsBAM : 24|8@1+ (1,0) [0|255] "" Vector__XXX
 SG_ TotalMessageSizeBAM : 8|16@1+ (1,0) [0|64255] "counts" Vector__XXX
 SG_ TotalMessageSizeEoMA : 8|16@1+ (1,0) [0|64255] "counts" Vector__XXX
 SG_ TotalNumberOfPacketsEoMA : 24|8@1+ (1,0) [0|255] "" Vector__XXX

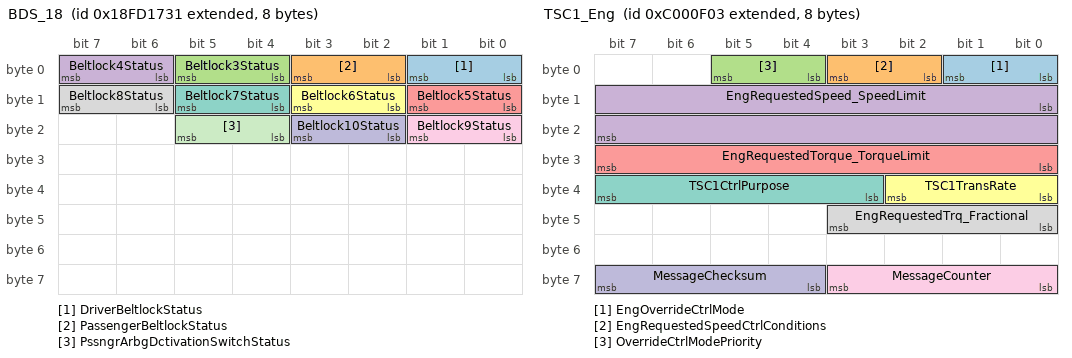
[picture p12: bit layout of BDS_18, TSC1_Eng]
BO_ 2566723377 BDS_18: 8 Vector__XXX
 SG_ DriverBeltlockStatus : 0|2@1+ (1,0) [0|3] "" Vector__XXX
 SG_ PassengerBeltlockStatus : 2|2@1+ (1,0) [0|3] "" Vector__XXX
 SG_ Beltlock3Status : 4|2@1+ (1,0) [0|3] "" Vector__XXX
 SG_ Beltlock4Status : 6|2@1+ (1,0) [0|3] "" Vector__XXX
 SG_ Beltlock5Status : 8|2@1+ (1,0) [0|3] "" Vector__XXX
 SG_ Beltlock6Status : 10|2@1+ (1,0) [0|3] "" Vector__XXX
 SG_ Beltlock7Status : 12|2@1+ (1,0) [0|3] "" Vector__XXX
 SG_ Beltlock8Status : 14|2@1+ (1,0) [0|3] "" Vector__XXX
 SG_ Beltlock9Status : 16|2@1+ (1,0) [0|3] "" Vector__XXX
 SG_ Beltlock10Status : 18|2@1+ (1,0) [0|3] "" Vector__XXX
 SG_ PssngrArbgDctivationSwitchStatus : 20|2@1+ (1,0) [0|3] "" Vector__XXX

BO_ 2565537790 RQST_FFFE: 3 Vector__XXX
 SG_ ParameterGroupNumber : 0|24@1+ (1,0) [0|16777200] "" Vector__XXX

BO_ 2632711936 TPDT_FF00: 8 Vector__XXX
 SG_ SequenceNumber : 0|8@1+ (1,0) [0|255] "" Vector__XXX

BO_ 2563833649 CL_FF31: 3 Vector__XXX
 SG_ SwIndicatBrightnessPrct : 16|8@1+ (0.4,0) [0|100] "%" Vector__XXX
 SG_ SwBacklightBrightnessPrct : 8|8@1+ (0.4,0) [0|100] "%" Vector__XXX
 SG_ IlluminationBrightnessPercent : 0|8@1+ (0.4,0) [0|100] "%" Vector__XXX

BO_ 2348814083 TSC1_Eng: 8 Vector__XXX
 SG_ EngOverrideCtrlMode : 0|2@1+ (1,0) [0|3] "" Vector__XXX
 SG_ EngRequestedSpeedCtrlConditions : 2|2@1+ (1,0) [0|3] "" Vector__XXX
 SG_ OverrideCtrlModePriority : 4|2@1+ (1,0) [0|3] "" Vector__XXX
 SG_ EngRequestedSpeed_SpeedLimit : 8|16@1+ (0.125,0) [0|8031.88] "rpm" Vector__XXX
 SG_ EngRequestedTorque_TorqueLimit : 24|8@1+ (1,-125) [-125|125] "%" Vector__XXX
 SG_ TSC1TransRate : 32|3@1+ (1,0) [0|7] "" Vector__XXX
 SG_ TSC1CtrlPurpose : 35|5@1+ (1,0) [0|31] "" Vector__XXX
 SG_ EngRequestedTrq_Fractional : 40|4@1+ (0.125,0) [0|0.875] "%" Vector__XXX
 SG_ MessageCounter : 56|4@1+ (1,0) [0|15] "" Vector__XXX
 SG_ MessageChecksum : 60|4@1+ (1,0) [0|15] "" Vector__XXX

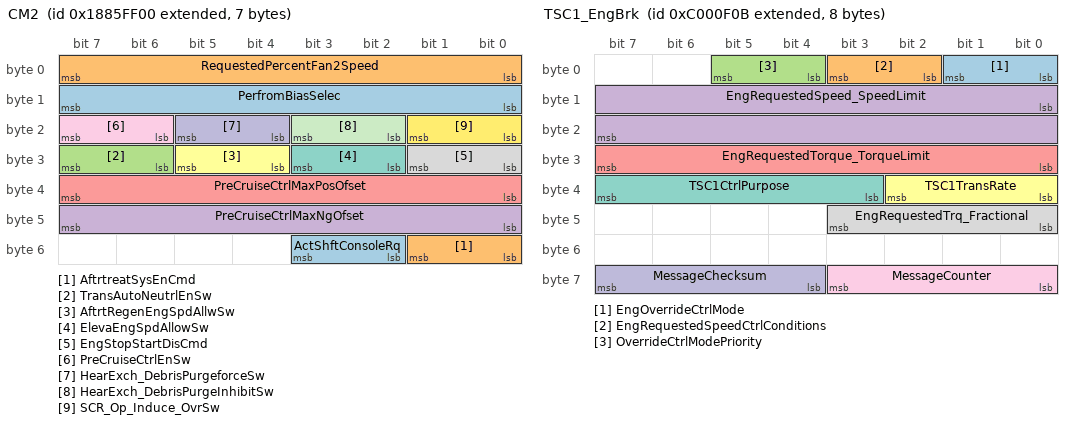
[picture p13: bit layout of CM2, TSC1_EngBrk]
BO_ 2558918400 CM2: 7 Vector__XXX
 SG_ ActShftConsoleRq : 50|2@1+ (1,0) [0|3] "" Vector__XXX
 SG_ AftrtreatSysEnCmd : 48|2@1+ (1,0) [0|3] "" Vector__XXX
 SG_ TransAutoNeutrlEnSw : 30|2@1+ (1,0) [0|3] "" Vector__XXX
 SG_ PreCruiseCtrlMaxNgOfset : 40|8@1+ (0.125,-31.25) [-31.25|0] "km/h" Vector__XXX
 SG_ PreCruiseCtrlMaxPosOfset : 32|8@1+ (0.125,0) [0|31.25] "km/h" Vector__XXX
 SG_ AftrtRegenEngSpdAllwSw : 28|2@1+ (1,0) [0|3] "" Vector__XXX
 SG_ ElevaEngSpdAllowSw : 26|2@1+ (1,0) [0|3] "" Vector__XXX
 SG_ EngStopStartDisCmd : 24|2@1+ (1,0) [0|3] "" Vector__XXX
 SG_ PreCruiseCtrlEnSw : 22|2@1+ (1,0) [0|3] "" Vector__XXX
 SG_ HearExch_DebrisPurgeforceSw : 20|2@1+ (1,0) [0|3] "" Vector__XXX
 SG_ HearExch_DebrisPurgeInhibitSw : 18|2@1+ (1,0) [0|3] "" Vector__XXX
 SG_ SCR_Op_Induce_OvrSw : 16|2@1+ (1,0) [0|3] "" Vector__XXX
 SG_ PerfromBiasSelec : 8|8@1+ (0.4,0) [0|100] "" Vector__XXX
 SG_ RequestedPercentFan2Speed : 0|8@1+ (0.4,0) [0|100] "%" Vector__XXX

BO_ 2566845696 AMB_00: 8 Vector__XXX
 SG_ BarometricPress : 0|8@1+ (0.5,0) [0|125] "kPa" Vector__XXX
 SG_ CabInteriorTemp : 8|16@1+ (0.03125,-273) [-273|1734.97] "deg C" Vector__XXX
 SG_ AmbientAirTemp : 24|16@1+ (0.03125,-273) [-273|1734.97] "deg C" Vector__XXX
 SG_ EngAirIntakeTemp : 40|8@1+ (1,-40) [-40|210] "deg C" Vector__XXX
 SG_ RoadSurfaceTemp : 48|16@1+ (0.03125,-273) [-273|1734.97] "deg C" Vector__XXX

BO_ 2564882176 CM1_00: 8 Vector__XXX
 SG_ RequestedPercentFanSpeed : 0|8@1+ (0.4,0) [0|100] "%" Vector__XXX
 SG_ CabInteriorTempCmd : 8|16@1+ (0.03125,-273) [-273|1734.96875] "deg C" Vector__XXX
 SG_ AuxHeaterCoolantPumpRq : 24|2@1+ (1,0) [0|3] "" Vector__XXX
 SG_ BatteryMainSwitchHoldRq : 26|2@1+ (1,0) [0|3] "" Vector__XXX
 SG_ OperatorSeatDirectionSwitch : 28|2@1+ (1,0) [0|3] "" Vector__XXX
 SG_ SeatBeltSwitch : 30|2@1+ (1,0) [0|3] "" Vector__XXX
 SG_ VhclLmtngSpdGvrnrDecrementSwitch : 34|2@1+ (1,0) [0|3] "" Vector__XXX
 SG_ VhclLmtngSpdGvrnrIncrementSwitch : 36|2@1+ (1,0) [0|3] "" Vector__XXX
 SG_ VhclLmtngSpdGovernorEnableSwitch : 38|2@1+ (1,0) [0|3] "" Vector__XXX
 SG_ DslPrtcltFltrRgnrtnInhibitSwitch : 40|2@1+ (1,0) [0|3] "" Vector__XXX
 SG_ DslPrtcltFltrRgnrtionForceSwitch : 42|2@1+ (1,0) [0|3] "" Vector__XXX
 SG_ AtomaticGearShiftingEnableSwitch : 44|2@1+ (1,0) [0|3] "" Vector__XXX
 SG_ EngAutomaticStartEnableSwitch : 46|2@1+ (1,0) [0|3] "" Vector__XXX
 SG_ AuxHeaterModeRq : 48|4@1+ (1,0) [0|15] "" Vector__XXX
 SG_ RqEngZoneHeating : 52|2@1+ (1,0) [0|3] "" Vector__XXX
 SG_ RqCabZoneHeating : 54|2@1+ (1,0) [0|3] "" Vector__XXX
 SG_ SelectedMaxVehicleSpeedLimit : 56|8@1+ (1,0) [0|250] "" Vector__XXX

BO_ 2566850355 PropB_07: 8 Vector__XXX

BO_ 2566849843 PropB_05: 8 Vector__XXX

BO_ 2566869553 PropB_52: 8 Vector__XXX

BO_ 2566849587 PropB_04: 8 Vector__XXX

BO_ 2564882225 CM1_31: 8 Vector__XXX
 SG_ RequestedPercentFanSpeed : 0|8@1+ (0.4,0) [0|100] "%" Vector__XXX
 SG_ CabInteriorTempCmd : 8|16@1+ (0.03125,-273) [-273|1734.96875] "deg C" Vector__XXX
 SG_ AuxHeaterCoolantPumpRq : 24|2@1+ (1,0) [0|3] "" Vector__XXX
 SG_ BatteryMainSwitchHoldRq : 26|2@1+ (1,0) [0|3] "" Vector__XXX
 SG_ OperatorSeatDirectionSwitch : 28|2@1+ (1,0) [0|3] "" Vector__XXX
 SG_ SeatBeltSwitch : 30|2@1+ (1,0) [0|3] "" Vector__XXX
 SG_ VhclLmtngSpdGvrnrDecrementSwitch : 34|2@1+ (1,0) [0|3] "" Vector__XXX
 SG_ VhclLmtngSpdGvrnrIncrementSwitch : 36|2@1+ (1,0) [0|3] "" Vector__XXX
 SG_ VhclLmtngSpdGovernorEnableSwitch : 38|2@1+ (1,0) [0|3] "" Vector__XXX
 SG_ DslPrtcltFltrRgnrtnInhibitSwitch : 40|2@1+ (1,0) [0|3] "" Vector__XXX
 SG_ DslPrtcltFltrRgnrtionForceSwitch : 42|2@1+ (1,0) [0|3] "" Vector__XXX
 SG_ AtomaticGearShiftingEnableSwitch : 44|2@1+ (1,0) [0|3] "" Vector__XXX
 SG_ EngAutomaticStartEnableSwitch : 46|2@1+ (1,0) [0|3] "" Vector__XXX
 SG_ AuxHeaterModeRq : 48|4@1+ (1,0) [0|15] "" Vector__XXX
 SG_ RqEngZoneHeating : 52|2@1+ (1,0) [0|3] "" Vector__XXX
 SG_ RqCabZoneHeating : 54|2@1+ (1,0) [0|3] "" Vector__XXX
 SG_ SelectedMaxVehicleSpeedLimit : 56|8@1+ (1,0) [0|250] "" Vector__XXX

BO_ 2365522187 PropB_01: 8 Vector__XXX

BO_ 2561272017 FLIC_E8D1: 4 Vector__XXX
 SG_ Current_SubRegion : 24|24@1+ (1,0) [0|16777215] "" Vector__XXX
 SG_ Current_Region : 8|16@1+ (1,0) [0|65535] "" Vector__XXX
 SG_ LaneDepartureWarningEnableCmd : 0|2@1+ (1,0) [0|3] "" Vector__XXX

BO_ 2566857192 PropB_21: 8 Vector__XXX

BO_ 2364476202 PropA: 8 Vector__XXX

BO_ 2349662981 TC2: 2 Vector__XXX
 SG_ TranMd10 : 8|2@1+ (1,0) [0|3] "" Vector__XXX
 SG_ TranMd9 : 0|2@1+ (1,0) [0|3] "" Vector__XXX

BO_ 2566852650 PropB_10: 8 Vector__XXX

BO_ 2566870016 PropB_54: 8 Vector__XXX

BO_ 2566864899 PropB_40: 8 Vector__XXX

BO_ 2147516672 ROST_FuelEconReport: 8 VCU
 SG_ EngFuelRate : 0|16@1+ (0.05,0) [0|3212.75] "L/h" Vector__XXX
 SG_ EngInstantaneousFuelEconomy : 16|16@1+ (0.001953,0) [0|125.49] "km/L" Vector__XXX
 SG_ EngAverageFuelEconomy : 32|16@1+ (0.001953,0) [0|125.49] "km/L" Vector__XXX

BO_ 2147516568 ROST_ModReport: 8 VCU
 SG_ Current_Gear : 0|8@1+ (1,-125) [-125|125] "" Vector__XXX
 SG_ Current_EngineBrakePercentage : 8|8@1+ (1,-125) [-125|125] "%" Vector__XXX

BO_ 2147516564 ROS_ModCmd: 8 Server
 SG_ Target_EngineBrakePercentage : 8|8@1+ (1,-125) [-125|125] "%" Vector__XXX
 SG_ Target_Gear : 0|8@1+ (1,-125) [-125|125] ""  VCU

BO_ 2550203141 TC1_TransCtrl: 8 VCU
 SG_ TransGearShiftInhibitRq : 0|2@1+ (1,0) [0|3] "" Vector__XXX
 SG_ TrnsTrqeConverterLockupDisableRq : 2|2@1+ (1,0) [0|3] "" Vector__XXX
 SG_ DisengageDrivelineRq : 4|2@1+ (1,0) [0|3] "" Vector__XXX
 SG_ TransReverseGearShiftInhibitRq : 6|2@1+ (1,0) [0|3] "" Vector__XXX
 SG_ RequestedPercentClutchSlip : 8|8@1+ (1,0) [0|100] "%" Vector__XXX
 SG_ TransRequestedGear : 16|8@1+ (1,-125) [-125|125] "" Vector__XXX
 SG_ DisengageDiffLockRqFrontAxle1 : 24|2@1+ (1,0) [0|3] "" Vector__XXX
 SG_ DisengageDiffLockRqFrontAxle2 : 26|2@1+ (1,0) [0|3] "" Vector__XXX
 SG_ DisengageDiffLockRqRearAxle1 : 28|2@1+ (1,0) [0|3] "" Vector__XXX
 SG_ DisengageDiffLockRqRearAxle2 : 30|2@1+ (1,0) [0|3] "" Vector__XXX
 SG_ DisengageDiffLockRqCentral : 32|2@1+ (1,0) [0|3] "" Vector__XXX
 SG_ DisengageDiffLockRqCentralFront : 34|2@1+ (1,0) [0|3] "" Vector__XXX
 SG_ DisengageDiffLockRqCentralRear : 36|2@1+ (1,0) [0|3] "" Vector__XXX
 SG_ TransMode1 : 40|2@1+ (1,0) [0|3] "" Vector__XXX
 SG_ TransMode2 : 42|2@1+ (1,0) [0|3] "" Vector__XXX
 SG_ TransMode3 : 44|2@1+ (1,0) [0|3] "" Vector__XXX
 SG_ TransMode4 : 46|2@1+ (1,0) [0|3] "" Vector__XXX
 SG_ TransRequestedLaunchGear : 50|4@1+ (1,0) [0|15] "" Vector__XXX
 SG_ TrnsShftSlectorDisplayModeSwitch : 54|2@1+ (1,0) [0|3] "" Vector__XXX
 SG_ TransMode5 : 56|2@1+ (1,0) [0|3] "" Vector__XXX
 SG_ TransMode6 : 58|2@1+ (1,0) [0|3] "" Vector__XXX
 SG_ TransMode7 : 60|2@1+ (1,0) [0|3] "" Vector__XXX
 SG_ TransMode8 : 62|2@1+ (1,0) [0|3] "" Vector__XXX

BO_ 2348876549 TC1_Shifter: 8 Vector__XXX
 SG_ TransGearShiftInhibitRq : 0|2@1+ (1,0) [0|3] "" Vector__XXX
 SG_ TrnsTrqeConverterLockupDisableRq : 2|2@1+ (1,0) [0|3] "" Vector__XXX
 SG_ DisengageDrivelineRq : 4|2@1+ (1,0) [0|3] "" Vector__XXX
 SG_ TransReverseGearShiftInhibitRq : 6|2@1+ (1,0) [0|3] "" Vector__XXX
 SG_ RequestedPercentClutchSlip : 8|8@1+ (1,0) [0|100] "%" Vector__XXX
 SG_ TransRequestedGear : 16|8@1+ (1,-125) [-125|125] "" Vector__XXX
 SG_ DisengageDiffLockRqFrontAxle1 : 24|2@1+ (1,0) [0|3] "" Vector__XXX
 SG_ DisengageDiffLockRqFrontAxle2 : 26|2@1+ (1,0) [0|3] "" Vector__XXX
 SG_ DisengageDiffLockRqRearAxle1 : 28|2@1+ (1,0) [0|3] "" Vector__XXX
 SG_ DisengageDiffLockRqRearAxle2 : 30|2@1+ (1,0) [0|3] "" Vector__XXX
 SG_ DisengageDiffLockRqCentral : 32|2@1+ (1,0) [0|3] "" Vector__XXX
 SG_ DisengageDiffLockRqCentralFront : 34|2@1+ (1,0) [0|3] "" Vector__XXX
 SG_ DisengageDiffLockRqCentralRear : 36|2@1+ (1,0) [0|3] "" Vector__XXX
 SG_ TransMode1 : 40|2@1+ (1,0) [0|3] "" Vector__XXX
 SG_ TransMode2 : 42|2@1+ (1,0) [0|3] "" Vector__XXX
 SG_ TransMode3 : 44|2@1+ (1,0) [0|3] "" Vector__XXX
 SG_ TransMode4 : 46|2@1+ (1,0) [0|3] "" Vector__XXX
 SG_ TransRequestedLaunchGear : 50|4@1+ (1,0) [0|15] "" Vector__XXX
 SG_ TrnsShftSlectorDisplayModeSwitch : 54|2@1+ (1,0) [0|3] "" Vector__XXX
 SG_ TransMode5 : 56|2@1+ (1,0) [0|3] "" Vector__XXX
 SG_ TransMode6 : 58|2@1+ (1,0) [0|3] "" Vector__XXX
 SG_ TransMode7 : 60|2@1+ (1,0) [0|3] "" Vector__XXX
 SG_ TransMode8 : 62|2@1+ (1,0) [0|3] "" Vector__XXX

BO_ 2348814091 TSC1_EngBrk: 8 VCU
 SG_ EngOverrideCtrlMode : 0|2@1+ (1,0) [0|3] "" Vector__XXX
 SG_ EngRequestedSpeedCtrlConditions : 2|2@1+ (1,0) [0|3] "" Vector__XXX
 SG_ OverrideCtrlModePriority : 4|2@1+ (1,0) [0|3] "" Vector__XXX
 SG_ EngRequestedSpeed_SpeedLimit : 8|16@1+ (0.125,0) [0|8031.88] "rpm" Vector__XXX
 SG_ EngRequestedTorque_TorqueLimit : 24|8@1+ (1,-125) [-125|125] "%" Vector__XXX
 SG_ TSC1TransRate : 32|3@1+ (1,0) [0|7] "" Vector__XXX
 SG_ TSC1CtrlPurpose : 35|5@1+ (1,0) [0|31] "" Vector__XXX
 SG_ EngRequestedTrq_Fractional : 40|4@1+ (0.125,0) [0|0.875] "%" Vector__XXX
 SG_ MessageCounter : 56|4@1+ (1,0) [0|15] "" Vector__XXX
 SG_ MessageChecksum : 60|4@1+ (1,0) [0|15] "" Vector__XXX

BO_ 2147516566 EBC2_8096: 8 Vector__XXX
 SG_ FrontAxleSpeed : 0|16@1+ (0.003906,0) [0|250.98] "km/h" Vector__XXX
 SG_ RelativeSpeedFrontAxleLeftWheel : 16|8@1+ (0.0625,-7.8125) [-7.8125|7.8125] "km/h" Vector__XXX
 SG_ RelativeSpeedFrontAxleRightWheel : 24|8@1+ (0.0625,-7.8125) [-7.8125|7.8125] "km/h" Vector__XXX
 SG_ RelativeSpeedRearAxle1LeftWheel : 32|8@1+ (0.0625,-7.8125) [-7.8125|7.8125] "km/h" Vector__XXX
 SG_ RelativeSpeedRearAxle1RightWheel : 40|8@1+ (0.0625,-7.8125) [-7.8125|7.8125] "km/h" Vector__XXX
 SG_ RelativeSpeedRearAxle2LeftWheel : 48|8@1+ (0.0625,-7.8125) [-7.8125|7.8125] "km/h" Vector__XXX
 SG_ RelativeSpeedRearAxle2RightWheel : 56|8@1+ (0.0625,-7.8125) [-7.8125|7.8125] "km/h" Vector__XXX

BO_ 2565865777 EBC1_31: 8 Vector__XXX
 SG_ ASREngCtrlActive : 0|2@1+ (1,0) [0|3] "" Vector__XXX
 SG_ ASRBrakeCtrlActive : 2|2@1+ (1,0) [0|3] "" Vector__XXX
 SG_ AntiLockBrakingActive : 4|2@1+ (1,0) [0|3] "" Vector__XXX
 SG_ EBSBrakeSwitch : 6|2@1+ (1,0) [0|3] "" Vector__XXX
 SG_ BrakePedalPos : 8|8@1+ (0.4,0) [0|100] "%" Vector__XXX
 SG_ ABSOffroadSwitch : 16|2@1+ (1,0) [0|3] "" Vector__XXX
 SG_ ASROffroadSwitch : 18|2@1+ (1,0) [0|3] "" Vector__XXX
 SG_ ASRHillHolderSwitch : 20|2@1+ (1,0) [0|3] "" Vector__XXX
 SG_ TractionCtrlOverrideSwitch : 22|2@1+ (1,0) [0|3] "" Vector__XXX
 SG_ AccelInterlockSwitch : 24|2@1+ (1,0) [0|3] "" Vector__XXX
 SG_ EngDerateSwitch : 26|2@1+ (1,0) [0|3] "" Vector__XXX
 SG_ EngAuxShutdownSwitch : 28|2@1+ (1,0) [0|3] "" Vector__XXX
 SG_ RemoteAccelEnableSwitch : 30|2@1+ (1,0) [0|3] "" Vector__XXX
 SG_ EngRetarderSelection : 32|8@1+ (0.4,0) [0|100] "%" Vector__XXX
 SG_ ABSFullyOperational : 40|2@1+ (1,0) [0|3] "" Vector__XXX
 SG_ EBSRedWarningSignal : 42|2@1+ (1,0) [0|3] "" Vector__XXX
 SG_ ABS_EBSAmberWarningSignal : 44|2@1+ (1,0) [0|3] "" Vector__XXX
 SG_ ATC_ASRInformationSignal : 46|2@1+ (1,0) [0|3] "" Vector__XXX
 SG_ SrcAddrssOfCntrllngDvcFrBrkeCtrl : 48|8@1+ (1,0) [0|255] "" Vector__XXX
 SG_ HaltBrakeSwitch : 58|2@1+ (1,0) [0|3] "" Vector__XXX
 SG_ TrailerABSStatus : 60|2@1+ (1,0) [0|3] "" Vector__XXX
 SG_ TrctrMntdTrailerABSWarningSignal : 62|2@1+ (1,0) [0|3] "" Vector__XXX
 SG_ RailroadModeSwitch : 56|2@1+ (1,0) [0|3] "" Vector__XXX

BO_ 2565865867 EBC1_8B: 8 Vector__XXX
 SG_ ASREngCtrlActive : 0|2@1+ (1,0) [0|3] "" Vector__XXX
 SG_ ASRBrakeCtrlActive : 2|2@1+ (1,0) [0|3] "" Vector__XXX
 SG_ AntiLockBrakingActive : 4|2@1+ (1,0) [0|3] "" Vector__XXX
 SG_ EBSBrakeSwitch : 6|2@1+ (1,0) [0|3] "" Vector__XXX
 SG_ BrakePedalPos : 8|8@1+ (0.4,0) [0|100] "%" Vector__XXX
 SG_ ABSOffroadSwitch : 16|2@1+ (1,0) [0|3] "" Vector__XXX
 SG_ ASROffroadSwitch : 18|2@1+ (1,0) [0|3] "" Vector__XXX
 SG_ ASRHillHolderSwitch : 20|2@1+ (1,0) [0|3] "" Vector__XXX
 SG_ TractionCtrlOverrideSwitch : 22|2@1+ (1,0) [0|3] "" Vector__XXX
 SG_ AccelInterlockSwitch : 24|2@1+ (1,0) [0|3] "" Vector__XXX
 SG_ EngDerateSwitch : 26|2@1+ (1,0) [0|3] "" Vector__XXX
 SG_ EngAuxShutdownSwitch : 28|2@1+ (1,0) [0|3] "" Vector__XXX
 SG_ RemoteAccelEnableSwitch : 30|2@1+ (1,0) [0|3] "" Vector__XXX
 SG_ EngRetarderSelection : 32|8@1+ (0.4,0) [0|100] "%" Vector__XXX
 SG_ ABSFullyOperational : 40|2@1+ (1,0) [0|3] "" Vector__XXX
 SG_ EBSRedWarningSignal : 42|2@1+ (1,0) [0|3] "" Vector__XXX
 SG_ ABS_EBSAmberWarningSignal : 44|2@1+ (1,0) [0|3] "" Vector__XXX
 SG_ ATC_ASRInformationSignal : 46|2@1+ (1,0) [0|3] "" Vector__XXX
 SG_ SrcAddrssOfCntrllngDvcFrBrkeCtrl : 48|8@1+ (1,0) [0|255] "" Vector__XXX
 SG_ HaltBrakeSwitch : 58|2@1+ (1,0) [0|3] "" Vector__XXX
 SG_ TrailerABSStatus : 60|2@1+ (1,0) [0|3] "" Vector__XXX
 SG_ TrctrMntdTrailerABSWarningSignal : 62|2@1+ (1,0) [0|3] "" Vector__XXX
 SG_ RailroadModeSwitch : 56|2@1+ (1,0) [0|3] "" Vector__XXX

BO_ 2565865784 EBC1_38: 8 VCU
 SG_ ASREngCtrlActive : 0|2@1+ (1,0) [0|3] "" Vector__XXX
 SG_ ASRBrakeCtrlActive : 2|2@1+ (1,0) [0|3] "" Vector__XXX
 SG_ AntiLockBrakingActive : 4|2@1+ (1,0) [0|3] "" Vector__XXX
 SG_ EBSBrakeSwitch : 6|2@1+ (1,0) [0|3] "" Vector__XXX
 SG_ BrakePedalPos : 8|8@1+ (0.4,0) [0|100] "%" Vector__XXX
 SG_ ABSOffroadSwitch : 16|2@1+ (1,0) [0|3] "" Vector__XXX
 SG_ ASROffroadSwitch : 18|2@1+ (1,0) [0|3] "" Vector__XXX
 SG_ ASRHillHolderSwitch : 20|2@1+ (1,0) [0|3] "" Vector__XXX
 SG_ TractionCtrlOverrideSwitch : 22|2@1+ (1,0) [0|3] "" Vector__XXX
 SG_ AccelInterlockSwitch : 24|2@1+ (1,0) [0|3] "" Vector__XXX
 SG_ EngDerateSwitch : 26|2@1+ (1,0) [0|3] "" Vector__XXX
 SG_ EngAuxShutdownSwitch : 28|2@1+ (1,0) [0|3] "" Vector__XXX
 SG_ RemoteAccelEnableSwitch : 30|2@1+ (1,0) [0|3] "" Vector__XXX
 SG_ EngRetarderSelection : 32|8@1+ (0.4,0) [0|100] "%" Vector__XXX
 SG_ ABSFullyOperational : 40|2@1+ (1,0) [0|3] "" Vector__XXX
 SG_ EBSRedWarningSignal : 42|2@1+ (1,0) [0|3] "" Vector__XXX
 SG_ ABS_EBSAmberWarningSignal : 44|2@1+ (1,0) [0|3] "" Vector__XXX
 SG_ ATC_ASRInformationSignal : 46|2@1+ (1,0) [0|3] "" Vector__XXX
 SG_ SrcAddrssOfCntrllngDvcFrBrkeCtrl : 48|8@1+ (1,0) [0|255] "" Vector__XXX
 SG_ HaltBrakeSwitch : 58|2@1+ (1,0) [0|3] "" Vector__XXX
 SG_ TrailerABSStatus : 60|2@1+ (1,0) [0|3] "" Vector__XXX
 SG_ TrctrMntdTrailerABSWarningSignal : 62|2@1+ (1,0) [0|3] "" Vector__XXX
 SG_ RailroadModeSwitch : 56|2@1+ (1,0) [0|3] "" Vector__XXX

BO_ 2565865739 EBC1_0B: 8 Vector__XXX
 SG_ ASREngCtrlActive : 0|2@1+ (1,0) [0|3] "" Vector__XXX
 SG_ ASRBrakeCtrlActive : 2|2@1+ (1,0) [0|3] "" Vector__XXX
 SG_ AntiLockBrakingActive : 4|2@1+ (1,0) [0|3] "" Vector__XXX
 SG_ EBSBrakeSwitch : 6|2@1+ (1,0) [0|3] "" Vector__XXX
 SG_ BrakePedalPos : 8|8@1+ (0.4,0) [0|100] "%" Vector__XXX
 SG_ ABSOffroadSwitch : 16|2@1+ (1,0) [0|3] "" Vector__XXX
 SG_ ASROffroadSwitch : 18|2@1+ (1,0) [0|3] "" Vector__XXX
 SG_ ASRHillHolderSwitch : 20|2@1+ (1,0) [0|3] "" Vector__XXX
 SG_ TractionCtrlOverrideSwitch : 22|2@1+ (1,0) [0|3] "" Vector__XXX
 SG_ AccelInterlockSwitch : 24|2@1+ (1,0) [0|3] "" Vector__XXX
 SG_ EngDerateSwitch : 26|2@1+ (1,0) [0|3] "" Vector__XXX
 SG_ EngAuxShutdownSwitch : 28|2@1+ (1,0) [0|3] "" Vector__XXX
 SG_ RemoteAccelEnableSwitch : 30|2@1+ (1,0) [0|3] "" Vector__XXX
 SG_ EngRetarderSelection : 32|8@1+ (0.4,0) [0|100] "%" Vector__XXX
 SG_ ABSFullyOperational : 40|2@1+ (1,0) [0|3] "" Vector__XXX
 SG_ EBSRedWarningSignal : 42|2@1+ (1,0) [0|3] "" Vector__XXX
 SG_ ABS_EBSAmberWarningSignal : 44|2@1+ (1,0) [0|3] "" Vector__XXX
 SG_ ATC_ASRInformationSignal : 46|2@1+ (1,0) [0|3] "" Vector__XXX
 SG_ SrcAddrssOfCntrllngDvcFrBrkeCtrl : 48|8@1+ (1,0) [0|255] "" Vector__XXX
 SG_ HaltBrakeSwitch : 58|2@1+ (1,0) [0|3] "" Vector__XXX
 SG_ TrailerABSStatus : 60|2@1+ (1,0) [0|3] "" Vector__XXX
 SG_ TrctrMntdTrailerABSWarningSignal : 62|2@1+ (1,0) [0|3] "" Vector__XXX
 SG_ RailroadModeSwitch : 56|2@1+ (1,0) [0|3] ""  VCU

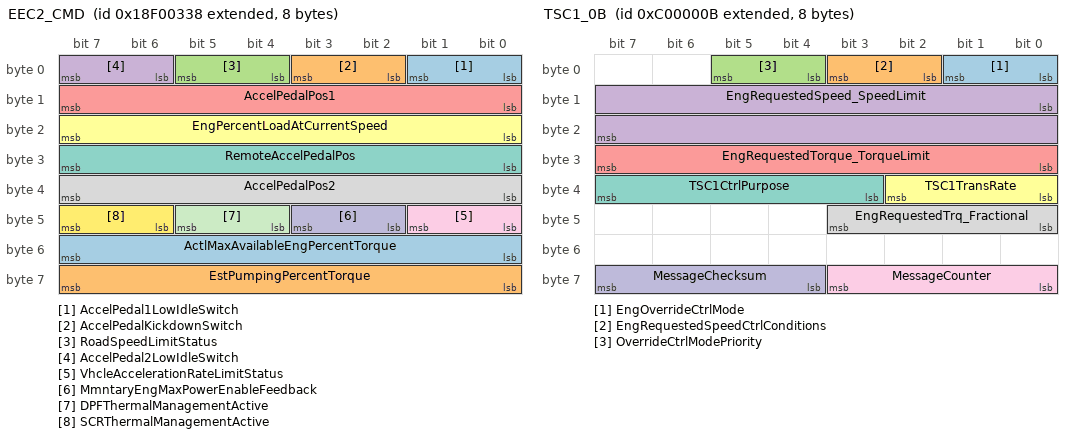
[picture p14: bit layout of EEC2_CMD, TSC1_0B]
BO_ 2565866296 EEC2_CMD: 8 VCU
 SG_ AccelPedal1LowIdleSwitch : 0|2@1+ (1,0) [0|3] "" Vector__XXX
 SG_ AccelPedalKickdownSwitch : 2|2@1+ (1,0) [0|3] "" Vector__XXX
 SG_ RoadSpeedLimitStatus : 4|2@1+ (1,0) [0|3] "" Vector__XXX
 SG_ AccelPedal2LowIdleSwitch : 6|2@1+ (1,0) [0|3] "" Vector__XXX
 SG_ AccelPedalPos1 : 8|8@1+ (0.4,0) [0|100] "%" Vector__XXX
 SG_ EngPercentLoadAtCurrentSpeed : 16|8@1+ (1,0) [0|250] "%" Vector__XXX
 SG_ RemoteAccelPedalPos : 24|8@1+ (0.4,0) [0|100] "%" Vector__XXX
 SG_ AccelPedalPos2 : 32|8@1+ (0.4,0) [0|100] "%" Vector__XXX
 SG_ VhcleAccelerationRateLimitStatus : 40|2@1+ (1,0) [0|3] "" Vector__XXX
 SG_ MmntaryEngMaxPowerEnableFeedback : 42|2@1+ (1,0) [0|3] "" Vector__XXX
 SG_ DPFThermalManagementActive : 44|2@1+ (1,0) [0|3] "" Vector__XXX
 SG_ SCRThermalManagementActive : 46|2@1+ (1,0) [0|3] "" Vector__XXX
 SG_ ActlMaxAvailableEngPercentTorque : 48|8@1+ (0.4,0) [0|100] "%" Vector__XXX
 SG_ EstPumpingPercentTorque : 56|8@1+ (1,-125) [-125|125] "%"  VCU

BO_ 2365587249 FCAN6: 8 Vector__XXX

BO_ 2565830705 FCAN5: 8 Vector__XXX

BO_ 2364530993 FCAN_CECU_CMD: 8 Vector__XXX
 SG_ LowBeamLHSignal : 48|16@1+ (1,0) [0|65535] "" Vector__XXX
 SG_ RunningLights : 40|8@1+ (1,0) [0|255] "" Vector__XXX
 SG_ HeadlightHighBeam : 32|8@1+ (1,0) [0|255] "" Vector__XXX
 SG_ HeadlightLowBeam : 24|8@1+ (1,0) [0|255] "" Vector__XXX
 SG_ HazardLight : 16|8@1+ (1,0) [0|255] "" Vector__XXX
 SG_ LeftTurnSignal : 9|1@1+ (1,0) [0|1] "" Vector__XXX
 SG_ RightTurnSignal : 8|1@1+ (1,0) [0|255] "" Vector__XXX

BO_ 2364465457 FCAN3: 8 Vector__XXX

BO_ 2364486113 FCAN2: 8 Vector__XXX

BO_ 2364420577 FCAN1: 8 Vector__XXX

BO_ 2348810251 TSC1_0B: 8 Vector__XXX
 SG_ EngOverrideCtrlMode : 0|2@1+ (1,0) [0|3] "" Vector__XXX
 SG_ EngRequestedSpeedCtrlConditions : 2|2@1+ (1,0) [0|3] "" Vector__XXX
 SG_ OverrideCtrlModePriority : 4|2@1+ (1,0) [0|3] "" Vector__XXX
 SG_ EngRequestedSpeed_SpeedLimit : 8|16@1+ (0.125,0) [0|8031.88] "rpm" Vector__XXX
 SG_ EngRequestedTorque_TorqueLimit : 24|8@1+ (1,-125) [-125|125] "%" Vector__XXX
 SG_ TSC1TransRate : 32|3@1+ (1,0) [0|7] "" Vector__XXX
 SG_ TSC1CtrlPurpose : 35|5@1+ (1,0) [0|31] "" Vector__XXX
 SG_ EngRequestedTrq_Fractional : 40|4@1+ (0.125,0) [0|0.875] "%" Vector__XXX
 SG_ MessageCounter : 56|4@1+ (1,0) [0|15] "" Vector__XXX
 SG_ MessageChecksum : 60|4@1+ (1,0) [0|15] "" Vector__XXX

BO_ 2566847488 DD_00: 8 Vector__XXX
 SG_ WasherFluidLevel : 0|8@1+ (0.4,0) [0|100] "%" Vector__XXX
 SG_ FuelLevel1 : 8|8@1+ (0.4,0) [0|100] "%" Vector__XXX
 SG_ EngFuelFilterDiffPress : 16|8@1+ (2,0) [0|500] "kPa" Vector__XXX
 SG_ EngOilFilterDiffPress : 24|8@1+ (0.5,0) [0|125] "kPa" Vector__XXX
 SG_ CargoAmbientTemp : 32|16@1+ (0.03125,-273) [-273|1734.97] "deg C" Vector__XXX
 SG_ FuelLevel2 : 48|8@1+ (0.4,0) [0|100] "%" Vector__XXX

BO_ 2566847025 B1: 8 Vector__XXX
 SG_ BrkAppPress : 0|8@1+ (4,0) [0|1000] "kPa" Vector__XXX
 SG_ BrkPrimPress : 8|8@1+ (4,0) [0|1000] "kPa" Vector__XXX
 SG_ BrkSecondPress : 16|8@1+ (4,0) [0|1000] "kPa" Vector__XXX
 SG_ ParkingBrkAct : 24|2@1+ (1,0) [0|3] "" Vector__XXX
 SG_ ParkingBrkRdWarnSig : 32|2@1+ (1,0) [0|3] "" Vector__XXX
 SG_ ParkBrkReleasenhibitSt : 40|2@1+ (1,0) [0|3] "" Vector__XXX

BO_ 2566846257 VEP1_31: 8 Vector__XXX
 SG_ BatteryPotential_PowerInput1 : 32|16@1+ (0.05,0) [0|3212.75] "V" Vector__XXX
 SG_ KeyswitchBatteryPotential : 48|16@1+ (0.05,0) [0|3212.75] "V" Vector__XXX
 SG_ NetBatteryCurrent : 0|8@1+ (1,-125) [-125|125] "A" Vector__XXX
 SG_ AltCurrent : 8|8@1+ (1,0) [0|250] "A" Vector__XXX
 SG_ ChargingSystemPotential : 16|16@1+ (0.05,0) [0|3212.75] "V" Vector__XXX

BO_ 2566846211 VEP1_03: 8 Vector__XXX
 SG_ BatteryPotential_PowerInput1 : 32|16@1+ (0.05,0) [0|3212.75] "V" Vector__XXX
 SG_ KeyswitchBatteryPotential : 48|16@1+ (0.05,0) [0|3212.75] "V" Vector__XXX
 SG_ NetBatteryCurrent : 0|8@1+ (1,-125) [-125|125] "A" Vector__XXX
 SG_ AltCurrent : 8|8@1+ (1,0) [0|250] "A" Vector__XXX
 SG_ ChargingSystemPotential : 16|16@1+ (0.05,0) [0|3212.75] "V" Vector__XXX

BO_ 2566844977 LFE1: 8 Vector__XXX
 SG_ EngFuelRate : 0|16@1+ (0.05,0) [0|3212.75] "l/h" Vector__XXX
 SG_ EngInstantaneousFuelEco : 16|16@1+ (0.001953,0) [0|125.49] "" Vector__XXX
 SG_ EngAvgeFuelEco : 32|16@1+ (0.001953,0) [0|125.49] "km/L" Vector__XXX
 SG_ EngThrotVal1Pos1 : 48|8@1+ (0.4,0) [0|100] "" Vector__XXX
 SG_ EngThrotVal2Pos : 56|8@1+ (0.4,0) [0|100] "" Vector__XXX

BO_ 2566844672 CCVS_BCD_spd: 8 Vector__XXX
 SG_ TwoSpdAxleSw : 0|2@1+ (1,0) [0|3] "bit" Vector__XXX
 SG_ ParkingBrakeSw : 2|2@1+ (1,0) [0|3] "" Vector__XXX
 SG_ CruiseCtrlPauseSw : 4|2@1+ (1,0) [0|3] "" Vector__XXX
 SG_ ParkBrakeReleaseInhibitReq : 6|2@1+ (1,0) [0|3] "" Vector__XXX
 SG_ WheelBasedVehSpd : 8|16@1+ (0.003906,0) [0|250.98] "km/h" Vector__XXX
 SG_ CruiseCtrlAct : 24|2@1+ (1,0) [0|3] "" Vector__XXX
 SG_ CruiseCtrlEnSw : 26|2@1+ (1,0) [0|3] "" Vector__XXX
 SG_ BrkSw : 28|2@1+ (1,0) [0|3] "" Vector__XXX
 SG_ ClutchSw : 30|2@1+ (1,0) [0|3] "" Vector__XXX
 SG_ CruiseCtrlSetSw : 32|2@1+ (1,0) [0|3] "" Vector__XXX
 SG_ CruiseCtrlCoastSw : 34|2@1+ (1,0) [0|3] "" Vector__XXX
 SG_ CruiseCtrlReSw : 36|2@1+ (1,0) [0|3] "" Vector__XXX
 SG_ CruiseCtrlAccSw : 38|2@1+ (1,0) [0|3] "" Vector__XXX
 SG_ CruiseCtrlSetSpd : 40|8@1+ (1,0) [0|250] "" Vector__XXX
 SG_ PTOGovernorSt : 48|5@1+ (1,0) [0|31] "" Vector__XXX
 SG_ CruiseCtrlSt : 53|3@1+ (1,0) [0|7] "" Vector__XXX
 SG_ EngIdleIncreSw : 56|2@1+ (1,0) [0|3] "" Vector__XXX
 SG_ EngIdleDecreSw : 58|2@1+ (1,0) [0|3] "" Vector__XXX
 SG_ EngDiagTestMdSw : 60|2@1+ (1,0) [0|3] "" Vector__XXX
 SG_ EngShutOvrdSw : 62|2@1+ (1,0) [0|3] ""  VCU

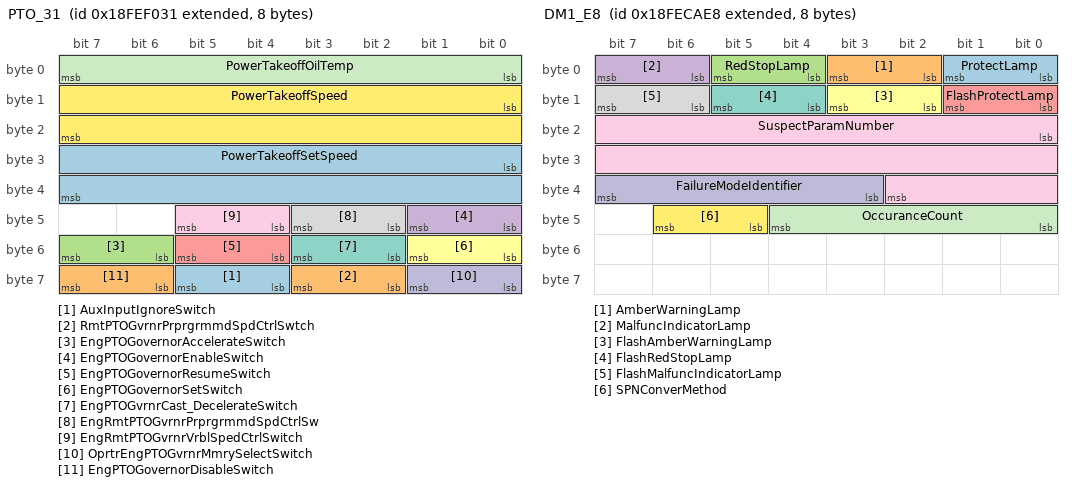
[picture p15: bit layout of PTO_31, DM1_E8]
BO_ 2566844465 PTO_31: 8 Vector__XXX
 SG_ AuxInputIgnoreSwitch : 60|2@1+ (1,0) [0|3] "" Vector__XXX
 SG_ RmtPTOGvrnrPrprgrmmdSpdCtrlSwtch : 58|2@1+ (1,0) [0|3] "" Vector__XXX
 SG_ EngPTOGovernorAccelerateSwitch : 54|2@1+ (1,0) [0|3] "" Vector__XXX
 SG_ EngPTOGovernorEnableSwitch : 40|2@1+ (1,0) [0|3] "" Vector__XXX
 SG_ EngPTOGovernorResumeSwitch : 52|2@1+ (1,0) [0|3] "" Vector__XXX
 SG_ EngPTOGovernorSetSwitch : 48|2@1+ (1,0) [0|3] "" Vector__XXX
 SG_ EngPTOGvrnrCast_DecelerateSwitch : 50|2@1+ (1,0) [0|3] "" Vector__XXX
 SG_ EngRmtPTOGvrnrPrprgrmmdSpdCtrlSw : 42|2@1+ (1,0) [0|3] "" Vector__XXX
 SG_ EngRmtPTOGvrnrVrblSpedCtrlSwitch : 44|2@1+ (1,0) [0|3] "" Vector__XXX
 SG_ OprtrEngPTOGvrnrMmrySelectSwitch : 56|2@1+ (1,0) [0|3] "" Vector__XXX
 SG_ PowerTakeoffOilTemp : 0|8@1+ (1,-40) [-40|210] "deg C" Vector__XXX
 SG_ PowerTakeoffSpeed : 8|16@1+ (0.125,0) [0|8031.88] "rpm" Vector__XXX
 SG_ PowerTakeoffSetSpeed : 24|16@1+ (0.125,0) [0|8031.88] "rpm" Vector__XXX
 SG_ EngPTOGovernorDisableSwitch : 62|2@1+ (1,0) [0|3] "" Vector__XXX

BO_ 2566842624 LFC1: 8 Vector__XXX
 SG_ EngineTripFuel : 0|32@1+ (0.5,0) [0|2147480000] "l" Vector__XXX
 SG_ EngineTotalFuelUsed : 32|32@1+ (0.5,0) [0|2147480000] "l" Vector__XXX

BO_ 2566834920 DM1_E8: 8 Vector__XXX
 SG_ ProtectLamp : 0|2@1+ (1,0) [0|3] "" Vector__XXX
 SG_ AmberWarningLamp : 2|2@1+ (1,0) [0|3] "" Vector__XXX
 SG_ RedStopLamp : 4|2@1+ (1,0) [0|3] "" Vector__XXX
 SG_ MalfuncIndicatorLamp : 6|2@1+ (1,0) [0|3] "" Vector__XXX
 SG_ FlashProtectLamp : 8|2@1+ (1,0) [0|3] "" Vector__XXX
 SG_ FlashAmberWarningLamp : 10|2@1+ (1,0) [0|3] "" Vector__XXX
 SG_ FlashRedStopLamp : 12|2@1+ (1,0) [0|3] "" Vector__XXX
 SG_ FlashMalfuncIndicatorLamp : 14|2@1+ (1,0) [0|3] "" Vector__XXX
 SG_ SuspectParamNumber : 16|19@1+ (1,0) [0|524287] "" Vector__XXX
 SG_ FailureModeIdentifier : 35|5@1+ (1,0) [0|31] "" Vector__XXX
 SG_ OccuranceCount : 40|5@1+ (1,0) [0|31] "" Vector__XXX
 SG_ SPNConverMethod : 45|2@1+ (1,0) [0|3] "" Vector__XXX

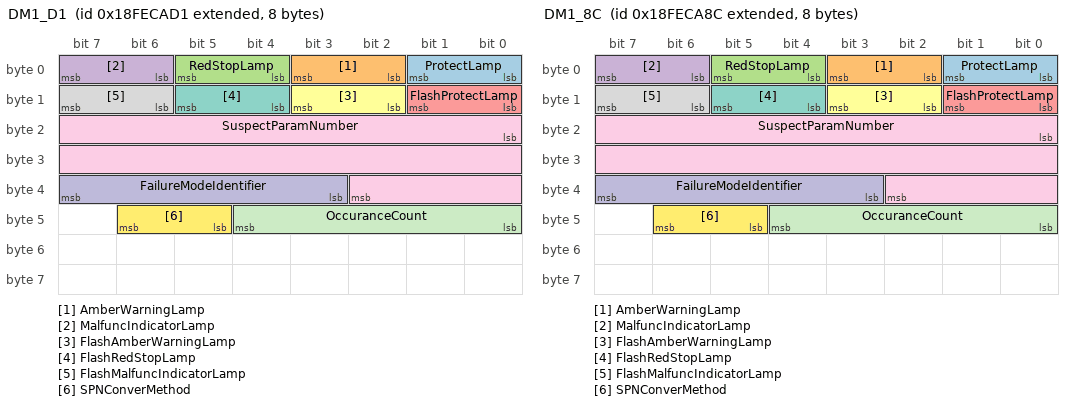
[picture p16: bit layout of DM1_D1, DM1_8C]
BO_ 2566834897 DM1_D1: 8 Vector__XXX
 SG_ ProtectLamp : 0|2@1+ (1,0) [0|3] "" Vector__XXX
 SG_ AmberWarningLamp : 2|2@1+ (1,0) [0|3] "" Vector__XXX
 SG_ RedStopLamp : 4|2@1+ (1,0) [0|3] "" Vector__XXX
 SG_ MalfuncIndicatorLamp : 6|2@1+ (1,0) [0|3] "" Vector__XXX
 SG_ FlashProtectLamp : 8|2@1+ (1,0) [0|3] "" Vector__XXX
 SG_ FlashAmberWarningLamp : 10|2@1+ (1,0) [0|3] "" Vector__XXX
 SG_ FlashRedStopLamp : 12|2@1+ (1,0) [0|3] "" Vector__XXX
 SG_ FlashMalfuncIndicatorLamp : 14|2@1+ (1,0) [0|3] "" Vector__XXX
 SG_ SuspectParamNumber : 16|19@1+ (1,0) [0|524287] "" Vector__XXX
 SG_ FailureModeIdentifier : 35|5@1+ (1,0) [0|31] "" Vector__XXX
 SG_ OccuranceCount : 40|5@1+ (1,0) [0|31] "" Vector__XXX
 SG_ SPNConverMethod : 45|2@1+ (1,0) [0|3] "" Vector__XXX

BO_ 2566834828 DM1_8C: 8 Vector__XXX
 SG_ ProtectLamp : 0|2@1+ (1,0) [0|3] "" Vector__XXX
 SG_ AmberWarningLamp : 2|2@1+ (1,0) [0|3] "" Vector__XXX
 SG_ RedStopLamp : 4|2@1+ (1,0) [0|3] "" Vector__XXX
 SG_ MalfuncIndicatorLamp : 6|2@1+ (1,0) [0|3] "" Vector__XXX
 SG_ FlashProtectLamp : 8|2@1+ (1,0) [0|3] "" Vector__XXX
 SG_ FlashAmberWarningLamp : 10|2@1+ (1,0) [0|3] "" Vector__XXX
 SG_ FlashRedStopLamp : 12|2@1+ (1,0) [0|3] "" Vector__XXX
 SG_ FlashMalfuncIndicatorLamp : 14|2@1+ (1,0) [0|3] "" Vector__XXX
 SG_ SuspectParamNumber : 16|19@1+ (1,0) [0|524287] "" Vector__XXX
 SG_ FailureModeIdentifier : 35|5@1+ (1,0) [0|31] "" Vector__XXX
 SG_ OccuranceCount : 40|5@1+ (1,0) [0|31] "" Vector__XXX
 SG_ SPNConverMethod : 45|2@1+ (1,0) [0|3] "" Vector__XXX

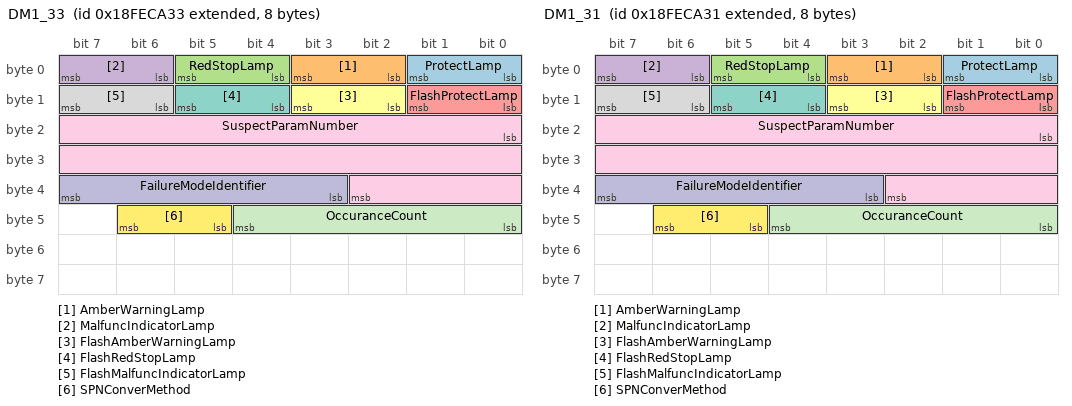
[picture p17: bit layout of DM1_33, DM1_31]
BO_ 2566834739 DM1_33: 8 Vector__XXX
 SG_ ProtectLamp : 0|2@1+ (1,0) [0|3] "" Vector__XXX
 SG_ AmberWarningLamp : 2|2@1+ (1,0) [0|3] "" Vector__XXX
 SG_ RedStopLamp : 4|2@1+ (1,0) [0|3] "" Vector__XXX
 SG_ MalfuncIndicatorLamp : 6|2@1+ (1,0) [0|3] "" Vector__XXX
 SG_ FlashProtectLamp : 8|2@1+ (1,0) [0|3] "" Vector__XXX
 SG_ FlashAmberWarningLamp : 10|2@1+ (1,0) [0|3] "" Vector__XXX
 SG_ FlashRedStopLamp : 12|2@1+ (1,0) [0|3] "" Vector__XXX
 SG_ FlashMalfuncIndicatorLamp : 14|2@1+ (1,0) [0|3] "" Vector__XXX
 SG_ SuspectParamNumber : 16|19@1+ (1,0) [0|524287] "" Vector__XXX
 SG_ FailureModeIdentifier : 35|5@1+ (1,0) [0|31] "" Vector__XXX
 SG_ OccuranceCount : 40|5@1+ (1,0) [0|31] "" Vector__XXX
 SG_ SPNConverMethod : 45|2@1+ (1,0) [0|3] "" Vector__XXX

BO_ 2566834737 DM1_31: 8 Vector__XXX
 SG_ ProtectLamp : 0|2@1+ (1,0) [0|3] "" Vector__XXX
 SG_ AmberWarningLamp : 2|2@1+ (1,0) [0|3] "" Vector__XXX
 SG_ RedStopLamp : 4|2@1+ (1,0) [0|3] "" Vector__XXX
 SG_ MalfuncIndicatorLamp : 6|2@1+ (1,0) [0|3] "" Vector__XXX
 SG_ FlashProtectLamp : 8|2@1+ (1,0) [0|3] "" Vector__XXX
 SG_ FlashAmberWarningLamp : 10|2@1+ (1,0) [0|3] "" Vector__XXX
 SG_ FlashRedStopLamp : 12|2@1+ (1,0) [0|3] "" Vector__XXX
 SG_ FlashMalfuncIndicatorLamp : 14|2@1+ (1,0) [0|3] "" Vector__XXX
 SG_ SuspectParamNumber : 16|19@1+ (1,0) [0|524287] "" Vector__XXX
 SG_ FailureModeIdentifier : 35|5@1+ (1,0) [0|31] "" Vector__XXX
 SG_ OccuranceCount : 40|5@1+ (1,0) [0|31] "" Vector__XXX
 SG_ SPNConverMethod : 45|2@1+ (1,0) [0|3] "" Vector__XXX

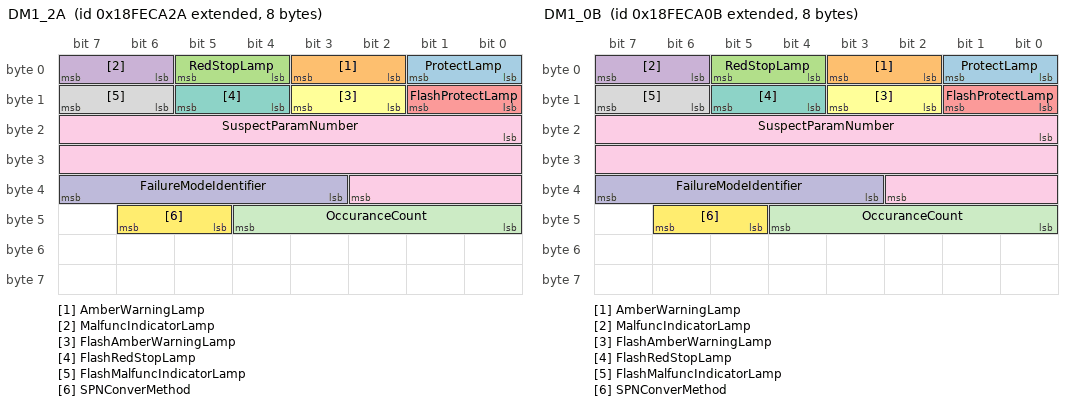
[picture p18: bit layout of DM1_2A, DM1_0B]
BO_ 2566834730 DM1_2A: 8 Vector__XXX
 SG_ ProtectLamp : 0|2@1+ (1,0) [0|3] "" Vector__XXX
 SG_ AmberWarningLamp : 2|2@1+ (1,0) [0|3] "" Vector__XXX
 SG_ RedStopLamp : 4|2@1+ (1,0) [0|3] "" Vector__XXX
 SG_ MalfuncIndicatorLamp : 6|2@1+ (1,0) [0|3] "" Vector__XXX
 SG_ FlashProtectLamp : 8|2@1+ (1,0) [0|3] "" Vector__XXX
 SG_ FlashAmberWarningLamp : 10|2@1+ (1,0) [0|3] "" Vector__XXX
 SG_ FlashRedStopLamp : 12|2@1+ (1,0) [0|3] "" Vector__XXX
 SG_ FlashMalfuncIndicatorLamp : 14|2@1+ (1,0) [0|3] "" Vector__XXX
 SG_ SuspectParamNumber : 16|19@1+ (1,0) [0|524287] "" Vector__XXX
 SG_ FailureModeIdentifier : 35|5@1+ (1,0) [0|31] "" Vector__XXX
 SG_ OccuranceCount : 40|5@1+ (1,0) [0|31] "" Vector__XXX
 SG_ SPNConverMethod : 45|2@1+ (1,0) [0|3] "" Vector__XXX

BO_ 2566834699 DM1_0B: 8 Vector__XXX
 SG_ ProtectLamp : 0|2@1+ (1,0) [0|3] "" Vector__XXX
 SG_ AmberWarningLamp : 2|2@1+ (1,0) [0|3] "" Vector__XXX
 SG_ RedStopLamp : 4|2@1+ (1,0) [0|3] "" Vector__XXX
 SG_ MalfuncIndicatorLamp : 6|2@1+ (1,0) [0|3] "" Vector__XXX
 SG_ FlashProtectLamp : 8|2@1+ (1,0) [0|3] "" Vector__XXX
 SG_ FlashAmberWarningLamp : 10|2@1+ (1,0) [0|3] "" Vector__XXX
 SG_ FlashRedStopLamp : 12|2@1+ (1,0) [0|3] "" Vector__XXX
 SG_ FlashMalfuncIndicatorLamp : 14|2@1+ (1,0) [0|3] "" Vector__XXX
 SG_ SuspectParamNumber : 16|19@1+ (1,0) [0|524287] "" Vector__XXX
 SG_ FailureModeIdentifier : 35|5@1+ (1,0) [0|31] "" Vector__XXX
 SG_ OccuranceCount : 40|5@1+ (1,0) [0|31] "" Vector__XXX
 SG_ SPNConverMethod : 45|2@1+ (1,0) [0|3] "" Vector__XXX

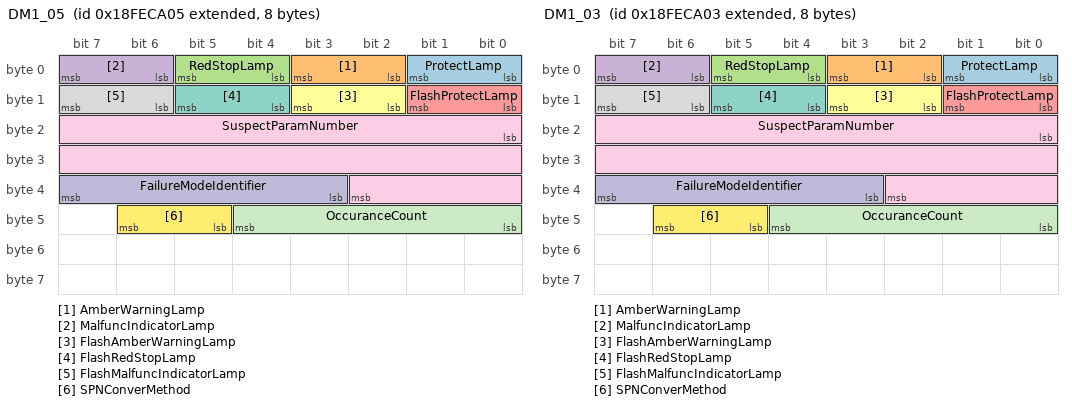
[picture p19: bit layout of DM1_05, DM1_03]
BO_ 2566834693 DM1_05: 8 Vector__XXX
 SG_ ProtectLamp : 0|2@1+ (1,0) [0|3] "" Vector__XXX
 SG_ AmberWarningLamp : 2|2@1+ (1,0) [0|3] "" Vector__XXX
 SG_ RedStopLamp : 4|2@1+ (1,0) [0|3] "" Vector__XXX
 SG_ MalfuncIndicatorLamp : 6|2@1+ (1,0) [0|3] "" Vector__XXX
 SG_ FlashProtectLamp : 8|2@1+ (1,0) [0|3] "" Vector__XXX
 SG_ FlashAmberWarningLamp : 10|2@1+ (1,0) [0|3] "" Vector__XXX
 SG_ FlashRedStopLamp : 12|2@1+ (1,0) [0|3] "" Vector__XXX
 SG_ FlashMalfuncIndicatorLamp : 14|2@1+ (1,0) [0|3] "" Vector__XXX
 SG_ SuspectParamNumber : 16|19@1+ (1,0) [0|524287] "" Vector__XXX
 SG_ FailureModeIdentifier : 35|5@1+ (1,0) [0|31] "" Vector__XXX
 SG_ OccuranceCount : 40|5@1+ (1,0) [0|31] "" Vector__XXX
 SG_ SPNConverMethod : 45|2@1+ (1,0) [0|3] "" Vector__XXX

BO_ 2566834691 DM1_03: 8 Vector__XXX
 SG_ ProtectLamp : 0|2@1+ (1,0) [0|3] "" Vector__XXX
 SG_ AmberWarningLamp : 2|2@1+ (1,0) [0|3] "" Vector__XXX
 SG_ RedStopLamp : 4|2@1+ (1,0) [0|3] "" Vector__XXX
 SG_ MalfuncIndicatorLamp : 6|2@1+ (1,0) [0|3] "" Vector__XXX
 SG_ FlashProtectLamp : 8|2@1+ (1,0) [0|3] "" Vector__XXX
 SG_ FlashAmberWarningLamp : 10|2@1+ (1,0) [0|3] "" Vector__XXX
 SG_ FlashRedStopLamp : 12|2@1+ (1,0) [0|3] "" Vector__XXX
 SG_ FlashMalfuncIndicatorLamp : 14|2@1+ (1,0) [0|3] "" Vector__XXX
 SG_ SuspectParamNumber : 16|19@1+ (1,0) [0|524287] "" Vector__XXX
 SG_ FailureModeIdentifier : 35|5@1+ (1,0) [0|31] "" Vector__XXX
 SG_ OccuranceCount : 40|5@1+ (1,0) [0|31] "" Vector__XXX
 SG_ SPNConverMethod : 45|2@1+ (1,0) [0|3] "" Vector__XXX

BO_ 2566832433 VDHR_31: 8 Vector__XXX
 SG_ HghRsolutionTotalVehicleDistance : 0|32@1+ (0.005,0) [0|21055400] "km" Vector__XXX
 SG_ HighResolutionTripDistance : 32|32@1+ (0.005,0) [0|21055400] "km" Vector__XXX

BO_ 2566757120 A1DEFI1: 8 Vector__XXX
 SG_ AftreatDieselExhaustFluidTemp2 : 0|8@1+ (1,-40) [-40|215] "C" Vector__XXX
 SG_ Aftreat1ExhaustFluidConcent : 8|8@1+ (0.25,0) [0|63.75] "%" Vector__XXX
 SG_ Aftreat1ExhaustFluidConduct : 16|8@1+ (5,0) [0|1250] "µSiemens/mm" Vector__XXX
 SG_ AftreatExhaustTemp2PreFMI : 24|5@1+ (1,0) [0|31] "binary" Vector__XXX
 SG_ Afttreat1ExhaustProperPreFMI : 32|5@1+ (1,0) [0|31] "binary" Vector__XXX
 SG_ Aftreat1ExhaustProp : 40|4@1+ (1,0) [0|15] "bit" Vector__XXX
 SG_ DieselFluidSpdofSound : 48|16@1+ (0.1,0) [0|6425.5] "m/s" Vector__XXX

BO_ 2566662656 OII: 8 Vector__XXX
 SG_ OperatorInducementTrqDerateL1 : 0|8@1+ (1,0) [0|250] "%" Vector__XXX
 SG_ OperatorInducementT2TrqDerateL1 : 8|16@1+ (1,0) [0|65535] "min" Vector__XXX
 SG_ OperatorInducementTrqDerateL2 : 24|8@1+ (1,0) [0|255] "%" Vector__XXX
 SG_ OperatorInducementT2TrqDerateL2 : 32|16@1+ (1,0) [0|65535] "min" Vector__XXX
 SG_ OpInduceT2FinalInduceAction : 48|16@1+ (1,0) [0|65535] "min" Vector__XXX

BO_ 2565935153 B2: 3 Vector__XXX
 SG_ DmdBrkAppPress : 0|16@1+ (10,0) [0|65540] "kPa" Vector__XXX
 SG_ BrkPedalSwitch2 : 16|2@1+ (1,0) [0|3] "" Vector__XXX

BO_ 2349465642 CCVS2: 5 Vector__XXX
 SG_ CruiseCtrlDisableCmd : 0|2@1+ (1,0) [0|3] "" Vector__XXX
 SG_ IdleSpdReq : 8|16@1+ (0.125,0) [0|8031.88] "rpm" Vector__XXX
 SG_ CruiseCtrlResumeCmd : 2|2@1+ (1,0) [0|3] "" Vector__XXX
 SG_ CruiseCtlPauseCmd : 4|2@1+ (1,0) [0|3] "" Vector__XXX
 SG_ IdleCtrlEnableState : 24|2@1+ (1,0) [0|3] "" Vector__XXX
 SG_ IdleCtrlReqAct : 32|2@1+ (1,0) [0|3] "" Vector__XXX

BO_ 2297441790 ACCS: 8 Vector__XXX
 SG_ LongitudinalAccelerationExRange : 16|16@1+ (0.01,-320) [-320|322.55] "" Vector__XXX
 SG_ LateralAccelerationExRange : 0|16@1+ (0.01,-320) [-320|322.55] "" Vector__XXX
 SG_ VerticalAccelerationExRange : 32|16@1+ (0.01,-320) [-320|322.55] "" Vector__XXX
 SG_ LtrlAcclrtonExRangeFigureOfMerit : 48|2@1+ (1,0) [0|3] "" Vector__XXX
 SG_ LngtdnlAcclrtnExRngFigureOfMerit : 50|2@1+ (1,0) [0|3] "" Vector__XXX
 SG_ VrtclAcclrtnExRangeFigureOfMerit : 52|2@1+ (1,0) [0|3] "" Vector__XXX
 SG_ SpprtVrblTrnsRpttnRtFrAcclrtnSns : 54|2@1+ (1,0) [0|3] "" Vector__XXX

BO_ 2566712062 VEP4: 8 Vector__XXX
 SG_ HybridBatteryPackRemainingCharge : 0|16@1+ (0.0025,0) [0|160.637] "%" Vector__XXX

BO_TX_BU_ 2365544037 : VCU,Body;

CM_ BO_ 3221225472 "This is a message for not used signals, created by Vector CANdb++ DBC OLE DB Provider.";
CM_ SG_ 2566912992 PowerBussP3 "Ports 5 & 6 power, shut off all bank outputs if the maximum current exceeds 13 amps per buss";
CM_ SG_ 2566912992 PowerBussP2 "Ports 3 & 4 power, shut off all bank outputs if the maximum current exceeds 13 amps per buss";
CM_ SG_ 2566912992 PowerBussP4 "Ports 7 & 8 power, shut off all bank outputs if the maximum current exceeds 13 amps per buss";
CM_ SG_ 2566912992 PowerBussP1 "Ports 1 & 2 power, shut off all bank outputs if the maximum current exceeds 13 amps per buss
00 = off
01 = on
10 = fault";
CM_ SG_ 2566912992 ConfigPair5 "Node ID 4's configuration jumper is applied";
CM_ SG_ 2566912992 ConfigPair4 "Node ID 3's configuration jumper is applied";
CM_ SG_ 2566912992 ConfigPair3 "Node ID 2's configuration jumper is applied";
CM_ SG_ 2566912992 ConfigPair2 "Node ID 1's configuration jumper is applied";
CM_ SG_ 2566913248 CNFG3 "Additional Configuration";
CM_ SG_ 2566913248 TEMP "Module Temperature";
CM_ SG_ 2566913248 CNFG2 "PCB Assembly Revision";
CM_ SG_ 2566913248 CNFG1 "Hardware Configuration";
CM_ SG_ 2147553424 Voltage2 "Voltage after PDS main relay";
CM_ SG_ 2147553424 Temperature2 "Temperature after main relay";
CM_ SG_ 2147614738 PitchRate "about x axis rotation";
CM_ SG_ 2147614738 RollRate "about y axis rotation";
CM_ SG_ 2147614738 Ay "longitudinal acceleration";
CM_ SG_ 2147614738 Ax "lateral acceleration";
CM_ BO_ 2566852135 "ICAN";
CM_ SG_ 2566865191 DRLFrontLeft "Tractor Indication Hazard and DRL Front Left Command";
CM_ SG_ 2566865191 DRLFrontRight "Tractor Indication Hazard and DRL (Daytime running lights) Front Right Command ";
CM_ SG_ 2566865191 HazardSideRight "Tractor Indication and Hazard Lamp Side Right Command ";
CM_ SG_ 2566865191 HazardSideLeft "Tractor Indication and Hazard Lamp Side Left Command";
CM_ SG_ 2566865191 BrkHazardRearLeft "Tractor Indication Brake and Hazard Lamp Rear Left Command ";
CM_ SG_ 2566865191 BrkHazardRearRight "Tractor Indication Brake and Hazard Lamp Rear Right Command ";
CM_ SG_ 2566865191 FrontParkLight "Front Tractor Position Lamp";
CM_ SG_ 2566865191 FrontFogLight "Fog/Driving Lamps Front";
CM_ SG_ 2566865191 RunRight "Daytime Running Light
00b : OFF
01b : ON
10b : ERROR
11b : Not Available ";
CM_ SG_ 2566865191 RunLeft "Daytime Running Light Left";
CM_ SG_ 2566865191 RightCmd "Trailer Indication/Hazard Light Right Command ";
CM_ SG_ 2566865191 LeftCmd "Trailer Indication/Hazard Light Left Command ";
CM_ SG_ 2566838767 AuxI_O03_AutoSwLtgColor "0 off
1 red
2 blue
3 N/A";
CM_ SG_ 2566838767 AuxI_O04_AutoSwSts "0 switch down(off)
1 switch up(on)
2 error
3 NA";
CM_ SG_ 2566838767 AuxI_O02_AutoSwLtgSts "0 off
1 on solid
2 on slow flash
3 on fast flash";
CM_ SG_ 2566838767 AuxI_O01_PrkBrkCmd "0 not commanding park brake
1 commanding park brake on
2 error
3 NA";
CM_ SG_ 2566838767 RightTurnRq "0 not requesting right turn signal to be on
1 requesting right turn signal to be on
2 error
3 NA";
CM_ SG_ 2566838767 LeftTurnRq "0 not requesting left turn signal to be on
1 requesting left turn signal to be on
2 error
3 NA";
CM_ SG_ 2566838767 AuxI_O05_CityHorn "0 not commanding city horn
1 commanding city horn to be on
2 error
3 NA";
CM_ SG_ 2566838561 AuxI_O03_AutoSwLtgColor "0 off
1 red
2 blue
3 N/A";
CM_ SG_ 2566838561 AuxI_O04_AutoSwSts "0 switch down(off)
1 switch up(on)
2 error
3 NA";
CM_ SG_ 2566838561 AuxI_O02_AutoSwLtgSts "0 off
1 on solid
2 on slow flash
3 on fast flash";
CM_ SG_ 2566838561 AuxI_O01_PrkBrkCmd "0 not commanding park brake
1 commanding park brake on
2 error
3 NA";
CM_ SG_ 2566838561 RightTurnRq "0 not requesting right turn signal to be on
1 requesting right turn signal to be on
2 error
3 NA";
CM_ SG_ 2566838561 LeftTurnRq "0 not requesting left turn signal to be on
1 requesting left turn signal to be on
2 error
3 NA";
CM_ SG_ 2566838561 AuxI_O05_CityHorn "0 not commanding city horn
1 commanding city horn to be on
2 error
3 NA";
CM_ SG_ 2365443105 TurnSignalSwitch "0 no turn
1 left turn
2 right turn
3-13 reserve
14 error(include left & right select simultaneously)
15 NA";
CM_ SG_ 2365443105 HazardLightSwitch "0 hazard off
1 hazard flashing
2 error
3 NA";
CM_ SG_ 2349662981 TranMd9 "0 Disable
1 Enable
2 Reserved
3 Take no action";
CM_ BO_ 2566870016 "See document J1939-21 for PGN details.";
CM_ BO_ 2566864899 "See document J1939-21 for PGN details.";
BA_DEF_  "BusType" STRING ;
BA_DEF_ BO_  "GenMsgCycleTime" INT 0 65535;
BA_DEF_DEF_  "BusType" "";
BA_DEF_DEF_  "GenMsgCycleTime" 0;
BA_ "BusType" "CAN";
BA_ "GenMsgCycleTime" BO_ 2147488545 10;
BA_ "GenMsgCycleTime" BO_ 2147484440 50;
BA_ "GenMsgCycleTime" BO_ 2147484438 50;
BA_ "GenMsgCycleTime" BO_ 2633943600 1000;
BA_ "GenMsgCycleTime" BO_ 2298375728 20;
BA_ "GenMsgCycleTime" BO_ 2566834736 1000;
BA_ "GenMsgCycleTime" BO_ 2566844711 100;
BA_ "GenMsgCycleTime" BO_ 2566844683 100;
BA_ "GenMsgCycleTime" BO_ 2566844705 100;
BA_ "GenMsgCycleTime" BO_ 2566865712 20;
BA_ "GenMsgCycleTime" BO_ 2364539648 10;
BA_ "GenMsgCycleTime" BO_ 2565866296 10;
BA_ "GenMsgCycleTime" BO_ 2566844672 100;
VAL_ 3221225472 CTIWheelEndElectricalFault_00 0 "Ok" 1 "NotDefined" 2 "Error" 3 "NotSupported" ;
VAL_ 3221225472 CTIWheelSensorStatus_00 0 "Off_IsolatedFromCTIPressCtrl" 1 "On" 2 "NotDefined" 3 "NotSupported" ;
VAL_ 3221225472 TirePressThresholdDetection_00 0 "ExtrmOvrPrssTrPrssrIsAtALvlWhrT" 1 "OvrPrssTrPrssrIsHghrThnThPrssrD" 2 "NWrnngPrssTrPrssrIsWthnThThrshl" 3 "UndrPrssTrPrssrIsLwrThnThPrssrD" 4 "ExtrmUndrPrssTrPrssrIsAtALvlWhr" 5 "NotDefined" 6 "ErrorIndicator" 7 "NotAvailable" ;
VAL_ 3221225472 TirePressThresholdDetection_20 0 "ExtrmOvrPrssTrPrssrIsAtALvlWhrT" 1 "OvrPrssTrPrssrIsHghrThnThPrssrD" 2 "NWrnngPrssTrPrssrIsWthnThThrshl" 3 "UndrPrssTrPrssrIsLwrThnThPrssrD" 4 "ExtrmUndrPrssTrPrssrIsAtALvlWhr" 5 "NotDefined" 6 "ErrorIndicator" 7 "NotAvailable" ;
VAL_ 3221225472 TirePressThresholdDetection_21 0 "ExtrmOvrPrssTrPrssrIsAtALvlWhrT" 1 "OvrPrssTrPrssrIsHghrThnThPrssrD" 2 "NWrnngPrssTrPrssrIsWthnThThrshl" 3 "UndrPrssTrPrssrIsLwrThnThPrssrD" 4 "ExtrmUndrPrssTrPrssrIsAtALvlWhr" 5 "NotDefined" 6 "ErrorIndicator" 7 "NotAvailable" ;
VAL_ 3221225472 TirePressThresholdDetection_22 0 "ExtrmOvrPrssTrPrssrIsAtALvlWhrT" 1 "OvrPrssTrPrssrIsHghrThnThPrssrD" 2 "NWrnngPrssTrPrssrIsWthnThThrshl" 3 "UndrPrssTrPrssrIsLwrThnThPrssrD" 4 "ExtrmUndrPrssTrPrssrIsAtALvlWhr" 5 "NotDefined" 6 "ErrorIndicator" 7 "NotAvailable" ;
VAL_ 3221225472 TirePressThresholdDetection_23 0 "ExtrmOvrPrssTrPrssrIsAtALvlWhrT" 1 "OvrPrssTrPrssrIsHghrThnThPrssrD" 2 "NWrnngPrssTrPrssrIsWthnThThrshl" 3 "UndrPrssTrPrssrIsLwrThnThPrssrD" 4 "ExtrmUndrPrssTrPrssrIsAtALvlWhr" 5 "NotDefined" 6 "ErrorIndicator" 7 "NotAvailable" ;
VAL_ 3221225472 TirePressThresholdDetection_30 0 "ExtrmOvrPrssTrPrssrIsAtALvlWhrT" 1 "OvrPrssTrPrssrIsHghrThnThPrssrD" 2 "NWrnngPrssTrPrssrIsWthnThThrshl" 3 "UndrPrssTrPrssrIsLwrThnThPrssrD" 4 "ExtrmUndrPrssTrPrssrIsAtALvlWhr" 5 "NotDefined" 6 "ErrorIndicator" 7 "NotAvailable" ;
VAL_ 3221225472 TirePressThresholdDetection_31 0 "ExtrmOvrPrssTrPrssrIsAtALvlWhrT" 1 "OvrPrssTrPrssrIsHghrThnThPrssrD" 2 "NWrnngPrssTrPrssrIsWthnThThrshl" 3 "UndrPrssTrPrssrIsLwrThnThPrssrD" 4 "ExtrmUndrPrssTrPrssrIsAtALvlWhr" 5 "NotDefined" 6 "ErrorIndicator" 7 "NotAvailable" ;
VAL_ 3221225472 TirePressThresholdDetection_32 0 "ExtrmOvrPrssTrPrssrIsAtALvlWhrT" 1 "OvrPrssTrPrssrIsHghrThnThPrssrD" 2 "NWrnngPrssTrPrssrIsWthnThThrshl" 3 "UndrPrssTrPrssrIsLwrThnThPrssrD" 4 "ExtrmUndrPrssTrPrssrIsAtALvlWhr" 5 "NotDefined" 6 "ErrorIndicator" 7 "NotAvailable" ;
VAL_ 3221225472 TirePressThresholdDetection_33 0 "ExtrmOvrPrssTrPrssrIsAtALvlWhrT" 1 "OvrPrssTrPrssrIsHghrThnThPrssrD" 2 "NWrnngPrssTrPrssrIsWthnThThrshl" 3 "UndrPrssTrPrssrIsLwrThnThPrssrD" 4 "ExtrmUndrPrssTrPrssrIsAtALvlWhr" 5 "NotDefined" 6 "ErrorIndicator" 7 "NotAvailable" ;
VAL_ 3221225472 CTITireStatus_01 0 "Ok" 1 "TireLeakDetected" 2 "Error" 3 "NotSupported" ;
VAL_ 3221225472 CTITireStatus_10 0 "Ok" 1 "TireLeakDetected" 2 "Error" 3 "NotSupported" ;
VAL_ 3221225472 CTITireStatus_11 0 "Ok" 1 "TireLeakDetected" 2 "Error" 3 "NotSupported" ;
VAL_ 3221225472 CTITireStatus_12 0 "Ok" 1 "TireLeakDetected" 2 "Error" 3 "NotSupported" ;
VAL_ 3221225472 CTITireStatus_13 0 "Ok" 1 "TireLeakDetected" 2 "Error" 3 "NotSupported" ;
VAL_ 3221225472 CTITireStatus_20 0 "Ok" 1 "TireLeakDetected" 2 "Error" 3 "NotSupported" ;
VAL_ 3221225472 CTITireStatus_21 0 "Ok" 1 "TireLeakDetected" 2 "Error" 3 "NotSupported" ;
VAL_ 3221225472 CTITireStatus_22 0 "Ok" 1 "TireLeakDetected" 2 "Error" 3 "NotSupported" ;
VAL_ 3221225472 CTITireStatus_23 0 "Ok" 1 "TireLeakDetected" 2 "Error" 3 "NotSupported" ;
VAL_ 3221225472 CTITireStatus_30 0 "Ok" 1 "TireLeakDetected" 2 "Error" 3 "NotSupported" ;
VAL_ 3221225472 CTITireStatus_31 0 "Ok" 1 "TireLeakDetected" 2 "Error" 3 "NotSupported" ;
VAL_ 3221225472 CTITireStatus_32 0 "Ok" 1 "TireLeakDetected" 2 "Error" 3 "NotSupported" ;
VAL_ 3221225472 CTITireStatus_33 0 "Ok" 1 "TireLeakDetected" 2 "Error" 3 "NotSupported" ;
VAL_ 3221225472 CTIWheelEndElectricalFault_01 0 "Ok" 1 "NotDefined" 2 "Error" 3 "NotSupported" ;
VAL_ 3221225472 CTIWheelEndElectricalFault_10 0 "Ok" 1 "NotDefined" 2 "Error" 3 "NotSupported" ;
VAL_ 3221225472 CTIWheelEndElectricalFault_11 0 "Ok" 1 "NotDefined" 2 "Error" 3 "NotSupported" ;
VAL_ 3221225472 CTIWheelEndElectricalFault_12 0 "Ok" 1 "NotDefined" 2 "Error" 3 "NotSupported" ;
VAL_ 3221225472 CTIWheelEndElectricalFault_13 0 "Ok" 1 "NotDefined" 2 "Error" 3 "NotSupported" ;
VAL_ 3221225472 CTIWheelEndElectricalFault_20 0 "Ok" 1 "NotDefined" 2 "Error" 3 "NotSupported" ;
VAL_ 3221225472 CTIWheelEndElectricalFault_21 0 "Ok" 1 "NotDefined" 2 "Error" 3 "NotSupported" ;
VAL_ 3221225472 CTIWheelEndElectricalFault_22 0 "Ok" 1 "NotDefined" 2 "Error" 3 "NotSupported" ;
VAL_ 3221225472 CTIWheelEndElectricalFault_23 0 "Ok" 1 "NotDefined" 2 "Error" 3 "NotSupported" ;
VAL_ 3221225472 CTIWheelEndElectricalFault_30 0 "Ok" 1 "NotDefined" 2 "Error" 3 "NotSupported" ;
VAL_ 3221225472 CTIWheelEndElectricalFault_31 0 "Ok" 1 "NotDefined" 2 "Error" 3 "NotSupported" ;
VAL_ 3221225472 CTIWheelEndElectricalFault_32 0 "Ok" 1 "NotDefined" 2 "Error" 3 "NotSupported" ;
VAL_ 3221225472 CTIWheelSensorStatus_01 0 "Off_IsolatedFromCTIPressCtrl" 1 "On" 2 "NotDefined" 3 "NotSupported" ;
VAL_ 3221225472 CTIWheelSensorStatus_10 0 "Off_IsolatedFromCTIPressCtrl" 1 "On" 2 "NotDefined" 3 "NotSupported" ;
VAL_ 3221225472 CTIWheelSensorStatus_11 0 "Off_IsolatedFromCTIPressCtrl" 1 "On" 2 "NotDefined" 3 "NotSupported" ;
VAL_ 3221225472 CTIWheelSensorStatus_12 0 "Off_IsolatedFromCTIPressCtrl" 1 "On" 2 "NotDefined" 3 "NotSupported" ;
VAL_ 3221225472 CTIWheelSensorStatus_13 0 "Off_IsolatedFromCTIPressCtrl" 1 "On" 2 "NotDefined" 3 "NotSupported" ;
VAL_ 3221225472 CTIWheelSensorStatus_20 0 "Off_IsolatedFromCTIPressCtrl" 1 "On" 2 "NotDefined" 3 "NotSupported" ;
VAL_ 3221225472 CTIWheelSensorStatus_21 0 "Off_IsolatedFromCTIPressCtrl" 1 "On" 2 "NotDefined" 3 "NotSupported" ;
VAL_ 3221225472 CTIWheelSensorStatus_22 0 "Off_IsolatedFromCTIPressCtrl" 1 "On" 2 "NotDefined" 3 "NotSupported" ;
VAL_ 3221225472 CTIWheelSensorStatus_23 0 "Off_IsolatedFromCTIPressCtrl" 1 "On" 2 "NotDefined" 3 "NotSupported" ;
VAL_ 3221225472 CTIWheelSensorStatus_30 0 "Off_IsolatedFromCTIPressCtrl" 1 "On" 2 "NotDefined" 3 "NotSupported" ;
VAL_ 3221225472 CTIWheelSensorStatus_31 0 "Off_IsolatedFromCTIPressCtrl" 1 "On" 2 "NotDefined" 3 "NotSupported" ;
VAL_ 3221225472 CTIWheelSensorStatus_32 0 "Off_IsolatedFromCTIPressCtrl" 1 "On" 2 "NotDefined" 3 "NotSupported" ;
VAL_ 3221225472 TirePressThresholdDetection_01 0 "ExtrmOvrPrssTrPrssrIsAtALvlWhrT" 1 "OvrPrssTrPrssrIsHghrThnThPrssrD" 2 "NWrnngPrssTrPrssrIsWthnThThrshl" 3 "UndrPrssTrPrssrIsLwrThnThPrssrD" 4 "ExtrmUndrPrssTrPrssrIsAtALvlWhr" 5 "NotDefined" 6 "ErrorIndicator" 7 "NotAvailable" ;
VAL_ 3221225472 TirePressThresholdDetection_10 0 "ExtrmOvrPrssTrPrssrIsAtALvlWhrT" 1 "OvrPrssTrPrssrIsHghrThnThPrssrD" 2 "NWrnngPrssTrPrssrIsWthnThThrshl" 3 "UndrPrssTrPrssrIsLwrThnThPrssrD" 4 "ExtrmUndrPrssTrPrssrIsAtALvlWhr" 5 "NotDefined" 6 "ErrorIndicator" 7 "NotAvailable" ;
VAL_ 3221225472 TirePressThresholdDetection_11 0 "ExtrmOvrPrssTrPrssrIsAtALvlWhrT" 1 "OvrPrssTrPrssrIsHghrThnThPrssrD" 2 "NWrnngPrssTrPrssrIsWthnThThrshl" 3 "UndrPrssTrPrssrIsLwrThnThPrssrD" 4 "ExtrmUndrPrssTrPrssrIsAtALvlWhr" 5 "NotDefined" 6 "ErrorIndicator" 7 "NotAvailable" ;
VAL_ 3221225472 TirePressThresholdDetection_12 0 "ExtrmOvrPrssTrPrssrIsAtALvlWhrT" 1 "OvrPrssTrPrssrIsHghrThnThPrssrD" 2 "NWrnngPrssTrPrssrIsWthnThThrshl" 3 "UndrPrssTrPrssrIsLwrThnThPrssrD" 4 "ExtrmUndrPrssTrPrssrIsAtALvlWhr" 5 "NotDefined" 6 "ErrorIndicator" 7 "NotAvailable" ;
VAL_ 2147484440 PwrSevereWarn 2 "All Clear" 1 "Warning Active" 0 "Offline" ;
VAL_ 2147484438 TSevereWarn 2 "All Clear" 1 "Warning Active" 0 "Offline" ;
VAL_ 2348810398 EngOverrideCtrlMode 0 "Override disabled  Disable any existing control commanded by the source of this command" 1 "Speed control  Govern speed to the included desired speed value" 2 "Torque control  Control torque to the included desired torque value" 3 "Speed/torque limit control  Limit speed and/or torque based on the included limit values The speed limit governor is" ;
VAL_ 2348810398 EngRequestedSpeedCtrlConditions 0 "Transient Optimized for driveline disengaged and nonlockup conditions" 1 "Stability Optimized for driveline disengaged and nonlockup conditions" 3 "Stability Optimized for driveline engaged and/or in lockup condition 2 eg PTO driveline" 2 "Stability Optimized for driveline engaged and/or in lockup condition 1 eg vehicle driveline" ;
VAL_ 2348810398 OverrideCtrlModePriority 0 "Highest priority" 1 "High priority" 2 "Medium priority" 3 "Low priority" ;
VAL_ 2348810398 TSC1TransRate 0 "1000 ms transmission rate" 1 "750 ms transmission rate" 2 "500 ms transmission rate" 3 "250 ms transmission rate" 4 "100 ms transmission rate" 5 "50 ms transmission rate" 6 "20 ms transmission rate" 7 "Use standard TSC1 transmission rates of 10 ms to engine" ;
VAL_ 2348810398 TSC1CtrlPurpose 0 "P1  Accelerator Pedal/Operator Selection" 1 "P2  Cruise Control" 2 "P3  PTO Governor" 3 "P4  Road Speed Governor" 4 "P5  Engine Protection" 5 "11110  P6P31  Reserved for SAE Assignment" 31 "P32  Temporary Power Train Control Original use of TSC1 Command" ;
VAL_ 2348810398 EngRequestedTrq_Fractional 8 "1111  not available" 0 "0000" 1 "0125" 7 "0875" ;
VAL_ 2348810282 EngOverrideCtrlMode 0 "Override disabled  Disable any existing control commanded by the source of this command" 1 "Speed control  Govern speed to the included desired speed value" 2 "Torque control  Control torque to the included desired torque value" 3 "Speed/torque limit control  Limit speed and/or torque based on the included limit values The speed limit governor is" ;
VAL_ 2348810282 EngRequestedSpeedCtrlConditions 0 "Transient Optimized for driveline disengaged and nonlockup conditions" 1 "Stability Optimized for driveline disengaged and nonlockup conditions" 3 "Stability Optimized for driveline engaged and/or in lockup condition 2 eg PTO driveline" 2 "Stability Optimized for driveline engaged and/or in lockup condition 1 eg vehicle driveline" ;
VAL_ 2348810282 OverrideCtrlModePriority 0 "Highest priority" 1 "High priority" 2 "Medium priority" 3 "Low priority" ;
VAL_ 2348810282 TSC1TransRate 0 "1000 ms transmission rate" 1 "750 ms transmission rate" 2 "500 ms transmission rate" 3 "250 ms transmission rate" 4 "100 ms transmission rate" 5 "50 ms transmission rate" 6 "20 ms transmission rate" 7 "Use standard TSC1 transmission rates of 10 ms to engine" ;
VAL_ 2348810282 TSC1CtrlPurpose 0 "P1  Accelerator Pedal/Operator Selection" 1 "P2  Cruise Control" 2 "P3  PTO Governor" 3 "P4  Road Speed Governor" 4 "P5  Engine Protection" 5 "11110  P6P31  Reserved for SAE Assignment" 31 "P32  Temporary Power Train Control Original use of TSC1 Command" ;
VAL_ 2348810282 EngRequestedTrq_Fractional 8 "1111  not available" 0 "0000" 1 "0125" 7 "0875" ;
VAL_ 2348814238 EngOverrideCtrlMode 0 "Override disabled  Disable any existing control commanded by the source of this command" 1 "Speed control  Govern speed to the included desired speed value" 2 "Torque control  Control torque to the included desired torque value" 3 "Speed/torque limit control  Limit speed and/or torque based on the included limit values The speed limit governor is" ;
VAL_ 2348814238 EngRequestedSpeedCtrlConditions 0 "Transient Optimized for driveline disengaged and nonlockup conditions" 1 "Stability Optimized for driveline disengaged and nonlockup conditions" 3 "Stability Optimized for driveline engaged and/or in lockup condition 2 eg PTO driveline" 2 "Stability Optimized for driveline engaged and/or in lockup condition 1 eg vehicle driveline" ;
VAL_ 2348814238 OverrideCtrlModePriority 0 "Highest priority" 1 "High priority" 2 "Medium priority" 3 "Low priority" ;
VAL_ 2348814238 TSC1TransRate 0 "1000 ms transmission rate" 1 "750 ms transmission rate" 2 "500 ms transmission rate" 3 "250 ms transmission rate" 4 "100 ms transmission rate" 5 "50 ms transmission rate" 6 "20 ms transmission rate" 7 "Use standard TSC1 transmission rates of 10 ms to engine" ;
VAL_ 2348814238 TSC1CtrlPurpose 0 "P1  Accelerator Pedal/Operator Selection" 1 "P2  Cruise Control" 2 "P3  PTO Governor" 3 "P4  Road Speed Governor" 4 "P5  Engine Protection" 5 "11110  P6P31  Reserved for SAE Assignment" 31 "P32  Temporary Power Train Control Original use of TSC1 Command" ;
VAL_ 2348814238 EngRequestedTrq_Fractional 8 "1111  not available" 0 "0000" 1 "0125" 7 "0875" ;
VAL_ 2349075302 XBREBIMode 0 "No Endurance Brake Integration allowed" 1 "Only Endurance Brakes allowed" 2 "Endurance Brake Integration allowed" 3 "Not defined" ;
VAL_ 2349075302 XBRPriority 0 "Highest priority  used for emergency situations eg for future Collision Avoidance System This mode overrides" 1 "High priority  not defined" 2 "Medium priority  used for ACCSystems This mode does not override brake protection measures of the brake" 3 "Low priority  used in override disabled XBR Control Mode" ;
VAL_ 2349075302 XBRCtrlMode 0 "Override disabled  Disable any existing control commanded by the source of this command" 1 "Acceleration control with addition mode  Add the XBR acceleration demand to the drivers acceleration demand" 2 "Acceleration control with maximum mode  Execute the XBR acceleration demand if it is higher than the drivers" 3 "Not defined" ;
VAL_ 2147516726 HighBeamHeadLightsCmdFb 0 "Deactivate" 1 "Activate" 2 "Reserved" 3 "Dont Care" ;
VAL_ 2147516726 LowBeamHeadLightsCmdFb 0 "Deactivate" 1 "Activate" 2 "Reserved" 3 "Dont Care" ;
VAL_ 2147516726 RunningLightsCmdFb 0 "Deactivate" 1 "Activate" 2 "Reserved" 3 "Dont Care" ;
VAL_ 2147516726 HazardLightsCmdFb 0 "Deactivate" 1 "Activate" 2 "Reserved" 3 "Dont Care" ;
VAL_ 2147516726 RightTurnSignalLightsCmdFb 0 "Deactivate" 1 "Activate" 2 "Reserved" 3 "Dont Care" ;
VAL_ 2147516726 LeftTurnSignalLightsCmdFb 0 "Deactivate" 1 "Activate" 2 "Reserved" 3 "Dont Care" ;
VAL_ 2147516432 HighBeamHeadLightCmd 0 "Deactivate" 1 "Activate" 2 "Reserved" 3 "Dont Care" ;
VAL_ 2147516432 LowBeamHeadLightCmd 0 "Deactivate" 1 "Activate" 2 "Reserved" 3 "Dont Care" ;
VAL_ 2147516432 RightTurnSignalLightsCmd 0 "Deactivate" 1 "Activate" 2 "Reserved" 3 "Dont Care" ;
VAL_ 2147516432 LeftTurnSignalLightsCmd 0 "Deactivate" 1 "Activate" 2 "Reserved" 3 "Dont Care" ;
VAL_ 2348810333 EngOverrideCtrlMode 0 "Override disabled  Disable any existing control commanded by the source of this command" 1 "Speed control  Govern speed to the included desired speed value" 2 "Torque control  Control torque to the included desired torque value" 3 "Speed/torque limit control  Limit speed and/or torque based on the included limit values The speed limit governor is" ;
VAL_ 2348810333 EngRequestedSpeedCtrlConditions 0 "Transient Optimized for driveline disengaged and nonlockup conditions" 1 "Stability Optimized for driveline disengaged and nonlockup conditions" 3 "Stability Optimized for driveline engaged and/or in lockup condition 2 eg PTO driveline" 2 "Stability Optimized for driveline engaged and/or in lockup condition 1 eg vehicle driveline" ;
VAL_ 2348810333 OverrideCtrlModePriority 0 "Highest priority" 1 "High priority" 2 "Medium priority" 3 "Low priority" ;
VAL_ 2348810333 TSC1TransRate 0 "1000 ms transmission rate" 1 "750 ms transmission rate" 2 "500 ms transmission rate" 3 "250 ms transmission rate" 4 "100 ms transmission rate" 5 "50 ms transmission rate" 6 "20 ms transmission rate" 7 "Use standard TSC1 transmission rates of 10 ms to engine" ;
VAL_ 2348810333 TSC1CtrlPurpose 0 "P1  Accelerator Pedal/Operator Selection" 1 "P2  Cruise Control" 2 "P3  PTO Governor" 3 "P4  Road Speed Governor" 4 "P5  Engine Protection" 5 "11110  P6P31  Reserved for SAE Assignment" 31 "P32  Temporary Power Train Control Original use of TSC1 Command" ;
VAL_ 2348810333 EngRequestedTrq_Fractional 8 "1111  not available" 0 "0000" 1 "0125" 7 "0875" ;
VAL_ 2566759427 EnblSwtchTrnsfrCseOutputShaftPTO 0 "Enable switch off  PTO operation not desired" 1 "Enable switch off  PTO operation desired" 2 "Error" 3 "Not available" ;
VAL_ 2566759427 EnableSwitchTransOutputShaftPTO 0 "Enable switch off  PTO operation not desired" 1 "Enable switch off  PTO operation desired" 2 "Error" 3 "Not available" ;
VAL_ 2566759427 EnableSwitchTransInputShaftPTO2 0 "Enable switch off  PTO operation not desired" 1 "Enable switch off  PTO operation desired" 2 "Error" 3 "Not available" ;
VAL_ 2566759427 EnableSwitchTransInputShaftPTO1 0 "Enable switch off  PTO operation not desired" 1 "Enable switch off  PTO operation desired" 2 "Error" 3 "Not available" ;
VAL_ 2566759427 EnableSwitchPTOEngFlywheel 0 "Enable switch off  PTO operation not desired" 1 "Enable switch on  PTO operation desired" 2 "Error" 3 "Not available" ;
VAL_ 2566759427 EnbleSwitchPTOEngAccessoryDrive1 0 "Enable switch off  PTO operation not desired" 1 "Enable switch on  PTO operation desired" 2 "Error" 3 "Not available" ;
VAL_ 2566759427 EnbleSwitchPTOEngAccessoryDrive2 0 "Enable switch off  PTO operation not desired" 1 "Enable switch on  PTO operation desired" 2 "Error" 3 "Not available" ;
VAL_ 2566759427 EnggmntCnsntTrnsfrCsOtptShaftPTO 0 "Consent not given  PTO drive should not be engaged" 1 "Consent given  PTO drive may be engaged" 2 "Error" 3 "Not available" ;
VAL_ 2566759427 EnggmntCnsentTransOutputShaftPTO 0 "Consent not given  PTO drive should not be engaged" 1 "Consent given  PTO drive may be engaged" 2 "Error" 3 "Not available" ;
VAL_ 2566759427 EnggmntCnsentTransInputShaftPTO2 0 "Consent not given  PTO drive should not be engaged" 1 "Consent given  PTO drive may be engaged" 2 "Error" 3 "Not available" ;
VAL_ 2566759427 EnggmntCnsentTransInputShaftPTO1 0 "Consent not given  PTO drive should not be engaged" 1 "Consent given  PTO drive may be engaged" 2 "Error" 3 "Not available" ;
VAL_ 2566759427 EngagementConsentPTOEngFlywheel 0 "Consent not given  PTO drive may not be engaged" 1 "Consent given  PTO drive may be engaged" 2 "Error" 3 "Not available" ;
VAL_ 2566759427 EnggmntCnsntPTOEngAccssoryDrive1 0 "Consent not given  PTO drive may not be engaged" 1 "Consent given  PTO drive may be engaged" 2 "Error" 3 "Not available" ;
VAL_ 2566759427 EnggmntCnsntPTOEngAccssoryDrive2 0 "Consent not given  PTO drive may not be engaged" 1 "Consent given  PTO drive may be engaged" 2 "Error" 3 "Not available" ;
VAL_ 2566759427 EnggmntSttsTrnsfrCsOtputShaftPTO 0 "Drive not engaged" 1 "Drive is engaged" 2 "Error" 3 "Not available" ;
VAL_ 2566759427 EnggmntStatusTransOutputShaftPTO 0 "Drive not engaged" 1 "Drive is engaged" 2 "Error" 3 "Not available" ;
VAL_ 2566759427 EnggmntStatusTransInputShaftPTO2 0 "Drive not engaged" 1 "Drive is engaged" 2 "Error" 3 "Not available" ;
VAL_ 2566759427 EnggmntStatusTransInputShaftPTO1 0 "Drive not engaged" 1 "Drive is engaged" 2 "Error" 3 "Not available" ;
VAL_ 2566759427 EngagementStatusPTOEngFlywheel 0 "Drive not engaged" 1 "Drive engaged" 2 "Error" 3 "Not available" ;
VAL_ 2566759427 EnggmntSttsPTOEngAccessoryDrive1 0 "Drive not engaged" 1 "Drive engaged" 2 "Error" 3 "Not available" ;
VAL_ 2566759427 EnggmntSttsPTOEngAccessoryDrive2 0 "Drive not engaged" 1 "Drive engaged" 2 "Error" 3 "Not available" ;
VAL_ 2566759427 AtLeastOnePTOEngaged 0 "No PTO drive is engaged" 1 "At least one PTO drive is engaged" 2 "Error" 3 "Not available" ;
VAL_ 2566842913 AxleLocation 0 "Axle0_Position0" 16 "Axle1_Position0" 32 "Axle2_Position0" 48 "Axle3_Position0" ;
VAL_ 2566799393 RunningLight 0 "Deactivated" 1 "Activated" 2 "Fault Detected" 3 "Not Available" ;
VAL_ 2566799393 AltBeamHeadLightData 0 "Deactivated" 1 "Activated" 2 "Fault Detected" 3 "Not Available" ;
VAL_ 2566799393 LowBeamHeadLightData 0 "Deactivated" 1 "Activated" 2 "Fault Detected" 3 "Not Available" ;
VAL_ 2566799393 HighBeamHeadLightData 0 "Deactivated" 1 "Activated" 2 "Fault Detected" 3 "Not Available" ;
VAL_ 2566799393 TractorFrontFogLights 0 "Deactivated" 1 "Activated" 2 "Fault Detected" 3 "Not Available" ;
VAL_ 2566799393 RotatingBeaconLight 0 "Deactivated" 1 "Activated" 2 "Fault Detected" 3 "Not Available" ;
VAL_ 2566799393 RightTurnSignalLights 0 "Deactivated" 1 "Activated" 2 "Fault Detected" 3 "Not Available" ;
VAL_ 2566799393 LeftTurnSignalLights 0 "Deactivated" 1 "Activated" 2 "Fault Detected" 3 "Not Available" ;
VAL_ 2566799393 BackUpLightAndAlarmHorn 0 "Deactivated" 1 "Activated" 2 "Fault Detected" 3 "Not Available" ;
VAL_ 2566799393 CenterStopLight 0 "Deactivated" 1 "Activated" 2 "Fault Detected" 3 "Not Available" ;
VAL_ 2566799393 RightStopLight 0 "Deactivated" 1 "Activated" 2 "Fault Detected" 3 "Not Available" ;
VAL_ 2566799393 LeftStopLight 0 "Deactivated" 1 "Activated" 2 "Fault Detected" 3 "Not Available" ;
VAL_ 2566799393 ImplementClearanceLight 0 "Deactivated" 1 "Activated" 2 "Fault Detected" 3 "Not Available" ;
VAL_ 2566799393 TractorClearanceLight 0 "Deactivated" 1 "Activated" 2 "Fault Detected" 3 "Not Available" ;
VAL_ 2566799393 ImplementMarkerLight 0 "Deactivated" 1 "Activated" 2 "Fault Detected" 3 "Not Available" ;
VAL_ 2566799393 TractorMarkerLight 0 "Deactivated" 1 "Activated" 2 "Fault Detected" 3 "Not Available" ;
VAL_ 2566799393 RearFogLights 0 "Deactivated" 1 "Activated" 2 "Fault Detected" 3 "Not Available" ;
VAL_ 2566799393 TrctorUndersideMountedWorkLights 0 "Deactivated" 1 "Activated" 2 "Fault Detected" 3 "Not Available" ;
VAL_ 2566799393 TractorRearLowMountedWorkLights 0 "Deactivated" 1 "Activated" 2 "Fault Detected" 3 "Not Available" ;
VAL_ 2566799393 TractorRearHighMountedWorkLights 0 "Deactivated" 1 "Activated" 2 "Fault Detected" 3 "Not Available" ;
VAL_ 2566799393 TractorSideLowMountedWorkLights 0 "Deactivated" 1 "Activated" 2 "Fault Detected" 3 "Not Available" ;
VAL_ 2566799393 TractorSideHighMountedWorkLights 0 "Deactivated" 1 "Activated" 2 "Fault Detected" 3 "Not Available" ;
VAL_ 2566799393 TractorFrontLowMountedWorkLights 0 "Deactivated" 1 "Activated" 2 "Fault Detected" 3 "Not Available" ;
VAL_ 2566799393 TrctorFrontHighMountedWorkLights 0 "Deactivated" 1 "Activated" 2 "Fault Detected" 3 "Not Available" ;
VAL_ 2566799393 ImplementOEMOption2Light 0 "Deactivated" 1 "Activated" 2 "Fault Detected" 3 "Not Available" ;
VAL_ 2566799393 ImplementOEMOption1Light 0 "Deactivated" 1 "Activated" 2 "Fault Detected" 3 "Not Available" ;
VAL_ 2566799393 ImplementRightFacingWorkLight 0 "Deactivated" 1 "Activated" 2 "Fault Detected" 3 "Not Available" ;
VAL_ 2566799393 ImplementLeftFacingWorkLight 0 "Deactivate" 1 "Activate" 2 "Fault Detected" 3 "Not Available" ;
VAL_ 2566799393 ImplementRightForwardWorkLight 0 "Deactivated" 1 "Activated" 2 "Fault Detected" 3 "Not Available" ;
VAL_ 2566799393 ImplementLeftForwardWorkLight 0 "Deactivated" 1 "Activated" 2 "Fault Detected" 3 "Not Available" ;
VAL_ 2566799393 ImplementRearWorkLight 0 "Deactivated" 1 "Activated" 2 "Fault Detected" 3 "Not Available" ;
VAL_ 2566718743 EngProtectLampData 0 "Lamp deactivated Off" 1 "Lamp activated On" 2 "Error" 3 "Not available" ;
VAL_ 2566718743 EngAmberWarningLampData 0 "Lamp deactivated Off" 1 "Lamp activated On" 2 "Error" 3 "Not available" ;
VAL_ 2566718743 EngRedStopLampData 0 "Lamp deactivated Off" 1 "Lamp activated On" 2 "Error" 3 "Not available" ;
VAL_ 2566718743 OBDMalfunctionIndicatorLampData 0 "Lamp deactivated Off" 1 "Lamp activated On" 2 "Error" 3 "Not available" ;
VAL_ 2566718743 EngBrakeActiveLampData 0 "Lamp deactivated Off" 1 "Lamp activated On" 2 "Error" 3 "Not available" ;
VAL_ 2566718743 CmprssnBrkEnblSwtchIndctrLmpData 0 "Lamp deactivated Off" 1 "Lamp activated On" 2 "Error" 3 "Not available" ;
VAL_ 2566718743 EngOilPressLowLampData 0 "Lamp deactivated Off" 1 "Lamp activated On" 2 "Error" 3 "Not available" ;
VAL_ 2566718743 EngCoolantTempHighLampData 0 "Lamp deactivated Off" 1 "Lamp activated On" 2 "Error" 3 "Not available" ;
VAL_ 2566718743 EngCoolantLevelLowLampData 0 "Lamp deactivated Off" 1 "Lamp activated On" 2 "Error" 3 "Not available" ;
VAL_ 2566718743 EngIdleManagementActiveLampData 0 "Lamp deactivated Off" 1 "Lamp activated On" 2 "Error" 3 "Not available" ;
VAL_ 2566718743 EngAirFilterRestrictionLampData 0 "Lamp deactivated Off" 1 "Lamp activated On" 2 "Error" 3 "Not available" ;
VAL_ 2566718743 EngFuelFilterRestrictedLampData 0 "Lamp deactivated Off" 1 "Lamp activated On" 2 "Error" 3 "Not available" ;
VAL_ 2566718743 EngWaitToStartLampData 0 "Lamp deactive" 1 "Lamp active" 2 "Error" 3 "Not available" ;
VAL_ 2432541440 EngTrbCmprssrBypssActtr1TmpSttus 0 "High Most severe" 1 "High Least severe" 2 "In Range" 3 "Low Least severe" 4 "Low Most severe" 5 "Not Defined" 6 "Error" 7 "Not available" ;
VAL_ 2364549379 PitchAngleExRangeCompensation 0 "On" 1 "Off" 2 "Error" 3 "Not Available" ;
VAL_ 2364549379 PitchAngleExRangeFigureOfMerit 0 "Pitch rate fully functional Data is within sensor specification" 1 "Pitch rate degraded Data is suspect due to environmental conditions" 2 "Error" 3 "Not available" ;
VAL_ 2364549379 RollAngleExRangeCompensation 0 "On" 1 "Off" 2 "Error" 3 "Not Available" ;
VAL_ 2364549379 RollAngleExRangeFigureOfMerit 0 "Roll rate fully functional Data is within sensor specification" 1 "Roll rate degraded Data is suspect due to environmental conditions" 2 "Error" 3 "Not available" ;
VAL_ 2348941061 TransGearShiftInhibitRq 0 "Gear shifts are allowed disable function" 1 "Gear shifts are inhibited enable function" 3 "Take no action leave function as is" 2 "Reserved" ;
VAL_ 2348941061 TrnsTrqeConverterLockupDisableRq 0 "Allow torque converter lockup" 1 "Disable torque converter lockup" 2 "Reserved" 3 "Take no action" ;
VAL_ 2348941061 DisengageDrivelineRq 0 "Allow driveline engagement" 1 "Disengage driveline" 3 "Take no action" 2 "Reserved" ;
VAL_ 2348941061 TransReverseGearShiftInhibitRq 0 "Allow shifts into Reverse gear" 1 "Inhibit shifts into Reverse gear and shift transmission to Neutral if already in Reverse or attempting to shift to" 2 "Reserved" 3 "Take no action" ;
VAL_ 2348941061 DisengageDiffLockRqFrontAxle1 0 "Engage differential lock" 1 "Disengage differential lock" 2 "Reserved" 3 "Take no action" ;
VAL_ 2348941061 DisengageDiffLockRqFrontAxle2 0 "Engage differential lock" 1 "Disengage differential lock" 2 "Reserved" 3 "Take no action" ;
VAL_ 2348941061 DisengageDiffLockRqRearAxle1 0 "Engage differential lock" 1 "Disengage differential lock" 2 "Reserved" 3 "Take no action" ;
VAL_ 2348941061 DisengageDiffLockRqRearAxle2 0 "Engage differential lock" 1 "Disengage differential lock" 2 "Reserved" 3 "Take no action" ;
VAL_ 2348941061 DisengageDiffLockRqCentral 0 "Engage differential lock" 1 "Disengage differential lock" 2 "Reserved" 3 "Take no action" ;
VAL_ 2348941061 DisengageDiffLockRqCentralFront 0 "Engage differential lock" 1 "Disengage differential lock" 2 "Reserved" 3 "Take no action" ;
VAL_ 2348941061 DisengageDiffLockRqCentralRear 0 "Engage differential lock" 1 "Disengage differential lock" 2 "Reserved" 3 "Take no action" ;
VAL_ 2348941061 TransMode1 0 "Disable" 1 "Enable" 2 "Reserved" 3 "Take no action" ;
VAL_ 2348941061 TransMode2 0 "Disable" 1 "Enable" 2 "Reserved" 3 "Take no action" ;
VAL_ 2348941061 TransMode3 0 "Disable" 1 "Enable" 2 "Reserved" 3 "Take no action" ;
VAL_ 2348941061 TransMode4 0 "Disable" 1 "Enable" 2 "Reserved" 3 "Take no action" ;
VAL_ 2348941061 TransRequestedLaunchGear 0 "No specific launch gear requested use default launch gear" 1 "Launch the vehicle in 1st gear" 2 "Launch the vehicle in 2nd gear" 3 "Launch the vehicle in 3rd gear" 4 "Launch the vehicle in 4th gear" 5 "Launch the vehicle in 5th gear" 6 "Launch the vehicle in 6th gear" 7 "Launch the vehicle in 7th gear" 8 "Launch the vehicle in 8th gear" 9 "Launch the vehicle in Reverse 1" 10 "Launch the vehicle in Reverse 2" 11 "Launch the vehicle in Reverse 3" 12 "Launch the vehicle in Reverse 4" 13 "Reserved" 14 "Error" 15 "Not Available" ;
VAL_ 2348941061 TrnsShftSlectorDisplayModeSwitch 0 "Off" 1 "On" 2 "Error" 3 "Not available" ;
VAL_ 2348941061 TransMode5 0 "Disable" 1 "Enable" 2 "Reserved" 3 "Take no action" ;
VAL_ 2348941061 TransMode6 0 "Disable" 1 "Enable" 2 "Reserved" 3 "Take no action" ;
VAL_ 2348941061 TransMode7 0 "Disable" 1 "Enable" 2 "Reserved" 3 "Take no action" ;
VAL_ 2348941061 TransMode8 0 "Disable" 1 "Enable" 2 "Reserved" 3 "Take no action" ;
VAL_ 2566764544 FuelSystemMonitoringComplete 0 "CompleteCycleOrNotSupported" 1 "NotCompleteCycle" ;
VAL_ 2566764544 ACSystemRefrigerantMonEnabled 0 "CompleteCycleOrNotSupported" 1 "NotCompleteCycle" ;
VAL_ 2566764544 ACSystemRefrigerantMonComplete 0 "CompleteCycleOrNotSupported" 1 "NotCompleteCycle" ;
VAL_ 2566764544 CatalystMonEnabled 0 "CompleteCycleOrNotSupported" 1 "NotCompleteCycle" ;
VAL_ 2566764544 CatalystMonComplete 0 "CompleteCycleOrNotSupported" 1 "NotCompleteCycle" ;
VAL_ 2566764544 ColdStartAidSystemMonEnabled 0 "DisabledForRestOfCycle" 1 "EnabledForCycle" ;
VAL_ 2566764544 ColdStartAidSystemMonComplete 0 "DisabledForRestOfCycle" 1 "EnabledForCycle" ;
VAL_ 2566764544 EGRSystemMonitoringEnabled 0 "DisabledForRestOfCycle" 1 "EnabledForCycle" ;
VAL_ 2566764544 EGRSystemMonitoringComplete 0 "CompleteCycleOrNotSupported" 1 "NotCompleteCycle" ;
VAL_ 2566764544 EvaporativeSystemMonEnabled 0 "CompleteCycleOrNotSupported" 1 "NotCompleteCycle" ;
VAL_ 2566764544 EvaporativeSystemMonComplete 0 "CompleteCycleOrNotSupported" 1 "NotCompleteCycle" ;
VAL_ 2566764544 HeatedCatalystMonEnabled 0 "DisabledForRestOfCycle" 1 "EnabledForCycle" ;
VAL_ 2566764544 HeatedCatalystMonComplete 0 "DisabledForRestOfCycle" 1 "EnabledForCycle" ;
VAL_ 2566764544 OxygenSensorHeaterMonEnabled 0 "CompleteCycleOrNotSupported" 1 "NotCompleteCycle" ;
VAL_ 2566764544 OxygenSensorHeaterMonComplete 0 "DisabledForRestOfCycle" 1 "EnabledForCycle" ;
VAL_ 2566764544 OxygenSensorMonEnabled 0 "CompleteCycleOrNotSupported" 1 "NotCompleteCycle" ;
VAL_ 2566764544 OxygenSensorMonComplete 0 "DisabledForRestOfCycle" 1 "EnabledForCycle" ;
VAL_ 2566764544 SecondAirSystemMonEnabled 0 "DisabledForRestOfCycle" 1 "EnabledForCycle" ;
VAL_ 2566764544 SecondAirSystemMonComplete 0 "DisabledForRestOfCycle" 1 "EnabledForCycle" ;
VAL_ 2566764544 ComprehensiveCompMonEnabled 0 "CompleteCycleOrNotSupported" 1 "NotCompleteCycle" ;
VAL_ 2566764544 ComprehensiveComptMonComplete 0 "CompleteCycleOrNotSupported" 1 "NotCompleteCycle" ;
VAL_ 2566764544 FuelSystemMonitoringEnabled 0 "CompleteCycleOrNotSupported" 1 "NotCompleteCycle" ;
VAL_ 2566764544 MisfireMonitoringEnabled 0 "DisabledForRestOfCycle" 1 "EnabledForCycle" ;
VAL_ 2566764544 MisfireMonitoringComplete 0 "DisabledForRestOfCycle" 1 "EnabledForCycle" ;
VAL_ 2348876555 TransGearShiftInhibitRq 0 "Gear shifts are allowed disable function" 1 "Gear shifts are inhibited enable function" 3 "Take no action leave function as is" 2 "Reserved" ;
VAL_ 2348876555 TrnsTrqeConverterLockupDisableRq 0 "Allow torque converter lockup" 1 "Disable torque converter lockup" 2 "Reserved" 3 "Take no action" ;
VAL_ 2348876555 DisengageDrivelineRq 0 "Allow driveline engagement" 1 "Disengage driveline" 3 "Take no action" 2 "Reserved" ;
VAL_ 2348876555 TransReverseGearShiftInhibitRq 0 "Allow shifts into Reverse gear" 1 "Inhibit shifts into Reverse gear and shift transmission to Neutral if already in Reverse or attempting to shift to" 2 "Reserved" 3 "Take no action" ;
VAL_ 2348876555 DisengageDiffLockRqFrontAxle1 0 "Engage differential lock" 1 "Disengage differential lock" 2 "Reserved" 3 "Take no action" ;
VAL_ 2348876555 DisengageDiffLockRqFrontAxle2 0 "Engage differential lock" 1 "Disengage differential lock" 2 "Reserved" 3 "Take no action" ;
VAL_ 2348876555 DisengageDiffLockRqRearAxle1 0 "Engage differential lock" 1 "Disengage differential lock" 2 "Reserved" 3 "Take no action" ;
VAL_ 2348876555 DisengageDiffLockRqRearAxle2 0 "Engage differential lock" 1 "Disengage differential lock" 2 "Reserved" 3 "Take no action" ;
VAL_ 2348876555 DisengageDiffLockRqCentral 0 "Engage differential lock" 1 "Disengage differential lock" 2 "Reserved" 3 "Take no action" ;
VAL_ 2348876555 DisengageDiffLockRqCentralFront 0 "Engage differential lock" 1 "Disengage differential lock" 2 "Reserved" 3 "Take no action" ;
VAL_ 2348876555 DisengageDiffLockRqCentralRear 0 "Engage differential lock" 1 "Disengage differential lock" 2 "Reserved" 3 "Take no action" ;
VAL_ 2348876555 TransMode1 0 "Disable" 1 "Enable" 2 "Reserved" 3 "Take no action" ;
VAL_ 2348876555 TransMode2 0 "Disable" 1 "Enable" 2 "Reserved" 3 "Take no action" ;
VAL_ 2348876555 TransMode3 0 "Disable" 1 "Enable" 2 "Reserved" 3 "Take no action" ;
VAL_ 2348876555 TransMode4 0 "Disable" 1 "Enable" 2 "Reserved" 3 "Take no action" ;
VAL_ 2348876555 TransRequestedLaunchGear 0 "No specific launch gear requested use default launch gear" 1 "Launch the vehicle in 1st gear" 2 "Launch the vehicle in 2nd gear" 3 "Launch the vehicle in 3rd gear" 4 "Launch the vehicle in 4th gear" 5 "Launch the vehicle in 5th gear" 6 "Launch the vehicle in 6th gear" 7 "Launch the vehicle in 7th gear" 8 "Launch the vehicle in 8th gear" 9 "Launch the vehicle in Reverse 1" 10 "Launch the vehicle in Reverse 2" 11 "Launch the vehicle in Reverse 3" 12 "Launch the vehicle in Reverse 4" 13 "Reserved" 14 "Error" 15 "Not Available" ;
VAL_ 2348876555 TrnsShftSlectorDisplayModeSwitch 0 "Off" 1 "On" 2 "Error" 3 "Not available" ;
VAL_ 2348876555 TransMode5 0 "Disable" 1 "Enable" 2 "Reserved" 3 "Take no action" ;
VAL_ 2348876555 TransMode6 0 "Disable" 1 "Enable" 2 "Reserved" 3 "Take no action" ;
VAL_ 2348876555 TransMode7 0 "Disable" 1 "Enable" 2 "Reserved" 3 "Take no action" ;
VAL_ 2348876555 TransMode8 0 "Disable" 1 "Enable" 2 "Reserved" 3 "Take no action" ;
VAL_ 2348814083 EngOverrideCtrlMode 0 "Override disabled  Disable any existing control commanded by the source of this command" 1 "Speed control  Govern speed to the included desired speed value" 2 "Torque control  Control torque to the included desired torque value" 3 "Speed/torque limit control  Limit speed and/or torque based on the included limit values The speed limit governor is" ;
VAL_ 2348814083 EngRequestedSpeedCtrlConditions 0 "Transient Optimized for driveline disengaged and nonlockup conditions" 1 "Stability Optimized for driveline disengaged and nonlockup conditions" 3 "Stability Optimized for driveline engaged and/or in lockup condition 2 eg PTO driveline" 2 "Stability Optimized for driveline engaged and/or in lockup condition 1 eg vehicle driveline" ;
VAL_ 2348814083 OverrideCtrlModePriority 0 "Highest priority" 1 "High priority" 2 "Medium priority" 3 "Low priority" ;
VAL_ 2348814083 TSC1TransRate 0 "1000 ms transmission rate" 1 "750 ms transmission rate" 2 "500 ms transmission rate" 3 "250 ms transmission rate" 4 "100 ms transmission rate" 5 "50 ms transmission rate" 6 "20 ms transmission rate" 7 "Use standard TSC1 transmission rates of 10 ms to engine" ;
VAL_ 2348814083 TSC1CtrlPurpose 0 "P1  Accelerator Pedal/Operator Selection" 1 "P2  Cruise Control" 2 "P3  PTO Governor" 3 "P4  Road Speed Governor" 4 "P5  Engine Protection" 5 "11110  P6P31  Reserved for SAE Assignment" 31 "P32  Temporary Power Train Control Original use of TSC1 Command" ;
VAL_ 2348814083 EngRequestedTrq_Fractional 8 "1111  not available" 0 "0000" 1 "0125" 7 "0875" ;
VAL_ 2561272017 LaneDepartureWarningEnableCmd 0 "Disable Lane Departure Warning" 1 "Enable Lane Departure Warning" 2 "Reserved" 3 "Dont care" ;
VAL_ 2550203141 TransGearShiftInhibitRq 0 "Gear shifts are allowed disable function" 1 "Gear shifts are inhibited enable function" 3 "Take no action leave function as is" 2 "Reserved" ;
VAL_ 2550203141 TrnsTrqeConverterLockupDisableRq 0 "Allow torque converter lockup" 1 "Disable torque converter lockup" 2 "Reserved" 3 "Take no action" ;
VAL_ 2550203141 DisengageDrivelineRq 0 "Allow driveline engagement" 1 "Disengage driveline" 3 "Take no action" 2 "Reserved" ;
VAL_ 2550203141 TransReverseGearShiftInhibitRq 0 "Allow shifts into Reverse gear" 1 "Inhibit shifts into Reverse gear and shift transmission to Neutral if already in Reverse or attempting to shift to" 2 "Reserved" 3 "Take no action" ;
VAL_ 2550203141 DisengageDiffLockRqFrontAxle1 0 "Engage differential lock" 1 "Disengage differential lock" 2 "Reserved" 3 "Take no action" ;
VAL_ 2550203141 DisengageDiffLockRqFrontAxle2 0 "Engage differential lock" 1 "Disengage differential lock" 2 "Reserved" 3 "Take no action" ;
VAL_ 2550203141 DisengageDiffLockRqRearAxle1 0 "Engage differential lock" 1 "Disengage differential lock" 2 "Reserved" 3 "Take no action" ;
VAL_ 2550203141 DisengageDiffLockRqRearAxle2 0 "Engage differential lock" 1 "Disengage differential lock" 2 "Reserved" 3 "Take no action" ;
VAL_ 2550203141 DisengageDiffLockRqCentral 0 "Engage differential lock" 1 "Disengage differential lock" 2 "Reserved" 3 "Take no action" ;
VAL_ 2550203141 DisengageDiffLockRqCentralFront 0 "Engage differential lock" 1 "Disengage differential lock" 2 "Reserved" 3 "Take no action" ;
VAL_ 2550203141 DisengageDiffLockRqCentralRear 0 "Engage differential lock" 1 "Disengage differential lock" 2 "Reserved" 3 "Take no action" ;
VAL_ 2550203141 TransMode1 0 "Disable" 1 "Enable" 2 "Reserved" 3 "Take no action" ;
VAL_ 2550203141 TransMode2 0 "Disable" 1 "Enable" 2 "Reserved" 3 "Take no action" ;
VAL_ 2550203141 TransMode3 0 "Disable" 1 "Enable" 2 "Reserved" 3 "Take no action" ;
VAL_ 2550203141 TransMode4 0 "Disable" 1 "Enable" 2 "Reserved" 3 "Take no action" ;
VAL_ 2550203141 TransRequestedLaunchGear 0 "No specific launch gear requested use default launch gear" 1 "Launch the vehicle in 1st gear" 2 "Launch the vehicle in 2nd gear" 3 "Launch the vehicle in 3rd gear" 4 "Launch the vehicle in 4th gear" 5 "Launch the vehicle in 5th gear" 6 "Launch the vehicle in 6th gear" 7 "Launch the vehicle in 7th gear" 8 "Launch the vehicle in 8th gear" 9 "Launch the vehicle in Reverse 1" 10 "Launch the vehicle in Reverse 2" 11 "Launch the vehicle in Reverse 3" 12 "Launch the vehicle in Reverse 4" 13 "Reserved" 14 "Error" 15 "Not Available" ;
VAL_ 2550203141 TrnsShftSlectorDisplayModeSwitch 0 "Off" 1 "On" 2 "Error" 3 "Not available" ;
VAL_ 2550203141 TransMode5 0 "Disable" 1 "Enable" 2 "Reserved" 3 "Take no action" ;
VAL_ 2550203141 TransMode6 0 "Disable" 1 "Enable" 2 "Reserved" 3 "Take no action" ;
VAL_ 2550203141 TransMode7 0 "Disable" 1 "Enable" 2 "Reserved" 3 "Take no action" ;
VAL_ 2550203141 TransMode8 0 "Disable" 1 "Enable" 2 "Reserved" 3 "Take no action" ;
VAL_ 2348876549 TransGearShiftInhibitRq 0 "Gear shifts are allowed disable function" 1 "Gear shifts are inhibited enable function" 3 "Take no action leave function as is" 2 "Reserved" ;
VAL_ 2348876549 TrnsTrqeConverterLockupDisableRq 0 "Allow torque converter lockup" 1 "Disable torque converter lockup" 2 "Reserved" 3 "Take no action" ;
VAL_ 2348876549 DisengageDrivelineRq 0 "Allow driveline engagement" 1 "Disengage driveline" 3 "Take no action" 2 "Reserved" ;
VAL_ 2348876549 TransReverseGearShiftInhibitRq 0 "Allow shifts into Reverse gear" 1 "Inhibit shifts into Reverse gear and shift transmission to Neutral if already in Reverse or attempting to shift to" 2 "Reserved" 3 "Take no action" ;
VAL_ 2348876549 DisengageDiffLockRqFrontAxle1 0 "Engage differential lock" 1 "Disengage differential lock" 2 "Reserved" 3 "Take no action" ;
VAL_ 2348876549 DisengageDiffLockRqFrontAxle2 0 "Engage differential lock" 1 "Disengage differential lock" 2 "Reserved" 3 "Take no action" ;
VAL_ 2348876549 DisengageDiffLockRqRearAxle1 0 "Engage differential lock" 1 "Disengage differential lock" 2 "Reserved" 3 "Take no action" ;
VAL_ 2348876549 DisengageDiffLockRqRearAxle2 0 "Engage differential lock" 1 "Disengage differential lock" 2 "Reserved" 3 "Take no action" ;
VAL_ 2348876549 DisengageDiffLockRqCentral 0 "Engage differential lock" 1 "Disengage differential lock" 2 "Reserved" 3 "Take no action" ;
VAL_ 2348876549 DisengageDiffLockRqCentralFront 0 "Engage differential lock" 1 "Disengage differential lock" 2 "Reserved" 3 "Take no action" ;
VAL_ 2348876549 DisengageDiffLockRqCentralRear 0 "Engage differential lock" 1 "Disengage differential lock" 2 "Reserved" 3 "Take no action" ;
VAL_ 2348876549 TransMode1 0 "Disable" 1 "Enable" 2 "Reserved" 3 "Take no action" ;
VAL_ 2348876549 TransMode2 0 "Disable" 1 "Enable" 2 "Reserved" 3 "Take no action" ;
VAL_ 2348876549 TransMode3 0 "Disable" 1 "Enable" 2 "Reserved" 3 "Take no action" ;
VAL_ 2348876549 TransMode4 0 "Disable" 1 "Enable" 2 "Reserved" 3 "Take no action" ;
VAL_ 2348876549 TransRequestedLaunchGear 0 "No specific launch gear requested use default launch gear" 1 "Launch the vehicle in 1st gear" 2 "Launch the vehicle in 2nd gear" 3 "Launch the vehicle in 3rd gear" 4 "Launch the vehicle in 4th gear" 5 "Launch the vehicle in 5th gear" 6 "Launch the vehicle in 6th gear" 7 "Launch the vehicle in 7th gear" 8 "Launch the vehicle in 8th gear" 9 "Launch the vehicle in Reverse 1" 10 "Launch the vehicle in Reverse 2" 11 "Launch the vehicle in Reverse 3" 12 "Launch the vehicle in Reverse 4" 13 "Reserved" 14 "Error" 15 "Not Available" ;
VAL_ 2348876549 TrnsShftSlectorDisplayModeSwitch 0 "Off" 1 "On" 2 "Error" 3 "Not available" ;
VAL_ 2348876549 TransMode5 0 "Disable" 1 "Enable" 2 "Reserved" 3 "Take no action" ;
VAL_ 2348876549 TransMode6 0 "Disable" 1 "Enable" 2 "Reserved" 3 "Take no action" ;
VAL_ 2348876549 TransMode7 0 "Disable" 1 "Enable" 2 "Reserved" 3 "Take no action" ;
VAL_ 2348876549 TransMode8 0 "Disable" 1 "Enable" 2 "Reserved" 3 "Take no action" ;
VAL_ 2348814091 EngOverrideCtrlMode 0 "Override disabled  Disable any existing control commanded by the source of this command" 1 "Speed control  Govern speed to the included desired speed value" 2 "Torque control  Control torque to the included desired torque value" 3 "Speed/torque limit control  Limit speed and/or torque based on the included limit values The speed limit governor is" ;
VAL_ 2348814091 EngRequestedSpeedCtrlConditions 0 "Transient Optimized for driveline disengaged and nonlockup conditions" 1 "Stability Optimized for driveline disengaged and nonlockup conditions" 3 "Stability Optimized for driveline engaged and/or in lockup condition 2 eg PTO driveline" 2 "Stability Optimized for driveline engaged and/or in lockup condition 1 eg vehicle driveline" ;
VAL_ 2348814091 OverrideCtrlModePriority 0 "Highest priority" 1 "High priority" 2 "Medium priority" 3 "Low priority" ;
VAL_ 2348814091 TSC1TransRate 0 "1000 ms transmission rate" 1 "750 ms transmission rate" 2 "500 ms transmission rate" 3 "250 ms transmission rate" 4 "100 ms transmission rate" 5 "50 ms transmission rate" 6 "20 ms transmission rate" 7 "Use standard TSC1 transmission rates of 10 ms to engine" ;
VAL_ 2348814091 TSC1CtrlPurpose 0 "P1  Accelerator Pedal/Operator Selection" 1 "P2  Cruise Control" 2 "P3  PTO Governor" 3 "P4  Road Speed Governor" 4 "P5  Engine Protection" 5 "11110  P6P31  Reserved for SAE Assignment" 31 "P32  Temporary Power Train Control Original use of TSC1 Command" ;
VAL_ 2348814091 EngRequestedTrq_Fractional 8 "1111  not available" 0 "0000" 1 "0125" 7 "0875" ;
VAL_ 2348810251 EngOverrideCtrlMode 0 "Override disabled  Disable any existing control commanded by the source of this command" 1 "Speed control  Govern speed to the included desired speed value" 2 "Torque control  Control torque to the included desired torque value" 3 "Speed/torque limit control  Limit speed and/or torque based on the included limit values The speed limit governor is" ;
VAL_ 2348810251 EngRequestedSpeedCtrlConditions 0 "Transient Optimized for driveline disengaged and nonlockup conditions" 1 "Stability Optimized for driveline disengaged and nonlockup conditions" 3 "Stability Optimized for driveline engaged and/or in lockup condition 2 eg PTO driveline" 2 "Stability Optimized for driveline engaged and/or in lockup condition 1 eg vehicle driveline" ;
VAL_ 2348810251 OverrideCtrlModePriority 0 "Highest priority" 1 "High priority" 2 "Medium priority" 3 "Low priority" ;
VAL_ 2348810251 TSC1TransRate 0 "1000 ms transmission rate" 1 "750 ms transmission rate" 2 "500 ms transmission rate" 3 "250 ms transmission rate" 4 "100 ms transmission rate" 5 "50 ms transmission rate" 6 "20 ms transmission rate" 7 "Use standard TSC1 transmission rates of 10 ms to engine" ;
VAL_ 2348810251 TSC1CtrlPurpose 0 "P1  Accelerator Pedal/Operator Selection" 1 "P2  Cruise Control" 2 "P3  PTO Governor" 3 "P4  Road Speed Governor" 4 "P5  Engine Protection" 5 "11110  P6P31  Reserved for SAE Assignment" 31 "P32  Temporary Power Train Control Original use of TSC1 Command" ;
VAL_ 2348810251 EngRequestedTrq_Fractional 8 "1111  not available" 0 "0000" 1 "0125" 7 "0875" ;
VAL_ 2297441790 LtrlAcclrtonExRangeFigureOfMerit 0 "lateral acceleration is fully functional Data is within sensor specification" 1 "lateral acceleration is degraded Data is suspect due to enviromental conditions" 2 "error" 3 "not available" ;
VAL_ 2297441790 LngtdnlAcclrtnExRngFigureOfMerit 0 "longitudinal acceleration is fully functional Data is within sensor specification" 1 "longitudinal acceleration is degraded Data is suspect due to enviromental conditions" 2 "error" 3 "not available" ;
VAL_ 2297441790 VrtclAcclrtnExRangeFigureOfMerit 0 "vertical acceleration is fully functional Data is within sensor specification" 1 "verticalacceleration is degraded Data is suspect due to enviromental conditions" 2 "error" 3 "not available" ;
